VERSION ""

NS_ :

BS_:

BU_: ECU BMU SHDN CHRG TOOL LOGGER C125 DTI_L DTI_R SEVCON_L SEVCON_R SBG

BO_ 256 SBG_ECAN_MSG_STATUS_01: 8 SBG
 SG_ SBG_MSG_01_TIME_STAMP : 0|32@1+ (1,0) [0|4294970000] "µs" C125
 SG_ SBG_MSG_01_GENERAL : 32|16@1+ (1,0) [0|65535] "" C125
 SG_ SBG_MSG_01_CLOCK : 48|16@1+ (1,0) [0|65535] "" C125

BO_ 257 SBG_ECAN_MSG_STATUS_02: 8 SBG
 SG_ SBG_MSG_02_COM : 0|32@1+ (1,0) [0|4294970000] "" Vector__XXX
 SG_ SBG_MSG_02_AIDING : 32|32@1+ (1,0) [0|4294970000] "" Vector__XXX

BO_ 258 SBG_ECAN_MSG_STATUS_03: 6 SBG
 SG_ SBG_MSG_03_SOLUTION : 0|32@1+ (1,0) [0|4294970000] "" Vector__XXX
 SG_ SBG_MSG_03_HEAVE_STATUS : 32|16@1+ (1,0) [0|65535] "" Vector__XXX

BO_ 272 SBG_ECAN_MSG_UTC_0: 8 SBG
 SG_ SBG_UTC_0_TIME_STAMP : 0|32@1+ (1,0) [0|4294970000] "µs" Vector__XXX
 SG_ SBG_UTC_0_GPS_TOW : 32|32@1+ (1,0) [0|4294970000] "ms" Vector__XXX

BO_ 273 SBG_ECAN_MSG_UTC_1: 8 SBG
 SG_ YEAR : 0|8@1+ (1,2000) [2000|2255] "year" Vector__XXX
 SG_ MONTH : 8|8@1+ (1,0) [0|255] "month" Vector__XXX
 SG_ DAY : 16|8@1+ (1,0) [0|255] "d" Vector__XXX
 SG_ HOUR : 24|8@1+ (1,0) [0|255] "h" Vector__XXX
 SG_ MIN : 32|8@1+ (1,0) [0|255] "min" Vector__XXX
 SG_ SEC : 40|8@1+ (1,0) [0|255] "s" Vector__XXX
 SG_ MICRO_SEC : 48|16@1+ (100,0) [0|6553500] "us" Vector__XXX

BO_ 288 SBG_ECAN_MSG_IMU_INFO: 8 SBG
 SG_ SBG_IMU_TIME_STAMP : 0|32@1+ (1,0) [0|4294970000] "µs" Vector__XXX
 SG_ SBG_IMU_STATUS : 32|16@1+ (1,0) [0|65535] "" Vector__XXX
 SG_ SBG_IMU_TEMPERATURE : 48|16@1- (0.01,0) [-327.68|327.67] "°C" Vector__XXX

BO_ 289 SBG_ECAN_MSG_IMU_ACCEL: 6 SBG
 SG_ SBG_IMU_ACCEL_X : 0|16@1- (0.01,0) [-327.68|327.67] "m.s-2" C125
 SG_ SBG_IMU_ACCEL_Y : 16|16@1- (0.01,0) [-327.68|327.67] "m.s-2" C125
 SG_ SBG_IMU_ACCEL_Z : 32|16@1- (0.01,0) [-327.68|327.67] "m.s-2" C125

BO_ 290 SBG_ECAN_MSG_IMU_GYRO: 6 SBG
 SG_ SBG_IMU_GYRO_X : 0|16@1- (0.001,0) [-32.768|32.767] "rad.s-1" C125
 SG_ SBG_IMU_GYRO_Y : 16|16@1- (0.001,0) [-32.768|32.767] "rad.s-1" C125
 SG_ SBG_IMU_GYRO_Z : 32|16@1- (0.001,0) [-32.768|32.767] "rad.s-1" C125

BO_ 291 SBG_ECAN_MSG_IMU_DELTA_VEL: 6 SBG
 SG_ SBG_DELTA_VEL_X : 0|16@1- (0.01,0) [-327.68|327.67] "m.s-2" Vector__XXX
 SG_ SBG_DELTA_VEL_Y : 16|16@1- (0.01,0) [-327.68|327.67] "m.s-2" Vector__XXX
 SG_ SBG_DELTA_VEL_Z : 32|16@1- (0.01,0) [-327.68|327.67] "m.s-2" Vector__XXX

BO_ 292 SBG_ECAN_MSG_IMU_DELTA_ANGLE: 6 SBG
 SG_ SBG_DELTA_ANGLE_X : 0|16@1- (0.001,0) [-32.768|32.767] "rad.s-1" Vector__XXX
 SG_ SBG_DELTA_ANGLE_Y : 16|16@1- (0.001,0) [-32.768|32.767] "rad.s-1" Vector__XXX
 SG_ SBG_DELTA_ANGLE_Z : 32|16@1- (0.001,0) [-32.768|32.767] "rad.s-1" Vector__XXX

BO_ 304 SBG_ECAN_MSG_EKF_INFO: 4 SBG
 SG_ SBG_EFK_TIME_STAMP : 0|32@1+ (1,0) [0|4294970000] "µs" C125

BO_ 305 SBG_ECAN_MSG_EKF_QUAT: 8 SBG
 SG_ Q0 : 0|16@1- (0.0000305185,0) [-1|1] "" Vector__XXX
 SG_ Q1 : 16|16@1- (0.0000305185,0) [-1|1] "" Vector__XXX
 SG_ Q2 : 32|16@1- (0.0000305185,0) [-1|1] "" Vector__XXX
 SG_ Q3 : 48|16@1- (0.0000305185,0) [-1|1] "" Vector__XXX

BO_ 306 SBG_ECAN_MSG_EKF_EULER: 6 SBG
 SG_ SBG_EKF_EULER_ROLL : 0|16@1- (0.0001,0) [-3.2768|3.2767] "rad" C125
 SG_ SBG_EKF_EULER_PITCH : 16|16@1- (0.0001,0) [-3.2768|3.2767] "rad" C125
 SG_ SBG_EKF_EULER_YAW : 32|16@1- (0.0001,0) [-3.2768|3.2767] "rad" C125

BO_ 307 SBG_ECAN_MSG_EKF_ORIENTATION_ACC: 6 SBG
 SG_ SBG_EKF_ORIE_ROLL_ACC : 0|16@1+ (0.0001,0) [0|6.5535] "rad" Vector__XXX
 SG_ SBG_EKF_ORIE_PITCH_ACC : 16|16@1+ (0.0001,0) [0|6.5535] "rad" Vector__XXX
 SG_ SBG_EKF_ORIE_YAW_ACC : 32|16@1+ (0.0001,0) [0|6.5535] "rad" Vector__XXX

BO_ 308 SBG_ECAN_MSG_EKF_POS: 8 SBG
 SG_ SBG_EKF_POS_LATITUDE : 0|32@1- (0.0000001,0) [-214.7483648|214.7483647] "°" C125
 SG_ SBG_EKF_POS_LONGITUDE : 32|32@1- (0.0000001,0) [-214.7483648|214.7483647] "°" C125

BO_ 309 SBG_ECAN_MSG_EKF_ALTITUDE: 6 SBG
 SG_ SBG_EKF_ALTITUDE : 0|32@1- (0.001,0) [-2147480|2147480] "m" C125
 SG_ SBG_EKF_UNDULATION : 32|16@1- (0.005,0) [-163.84|163.835] "m" C125

BO_ 310 SBG_ECAN_MSG_EKF_POS_ACC: 6 SBG
 SG_ SBG_EKF_POS_LATITUDE_ACC : 0|16@1+ (0.01,0) [0|655.35] "m" Vector__XXX
 SG_ SBG_EKF_POS_LONGITUDE_ACC : 16|16@1+ (0.01,0) [0|655.35] "m" Vector__XXX
 SG_ SBG_EKF_POS_ALTITUDE_ACC : 32|16@1+ (0.01,0) [0|655.35] "m" Vector__XXX

BO_ 311 SBG_ECAN_MSG_EKF_VEL_NED: 6 SBG
 SG_ SBG_EKF_NED_VELOCITY_N : 0|16@1- (0.01,0) [-327.68|327.67] "m.s-1" C125
 SG_ SBG_EKF_NED_VELOCITY_E : 16|16@1- (0.01,0) [-327.68|327.67] "m.s-1" C125
 SG_ SBG_EKF_NED_VELOCITY_D : 32|16@1- (0.01,0) [-327.68|327.67] "m.s-1" C125

BO_ 312 SBG_ECAN_MSG_EKF_VEL_NED_ACC: 6 SBG
 SG_ SBG_EKF_NED_VELOCITY_ACC_N : 0|16@1- (0.01,0) [-327.68|327.67] "m.s-1" Vector__XXX
 SG_ SBG_EKF_NED_VELOCITY_ACC_E : 16|16@1- (0.01,0) [-327.68|327.67] "m.s-1" Vector__XXX
 SG_ SBG_EKF_NED_VELOCITY_ACC_D : 32|16@1- (0.01,0) [-327.68|327.67] "m.s-1" Vector__XXX

BO_ 313 SBG_ECAN_MSG_EKF_VEL_BODY: 6 SBG
 SG_ SBG_EKF_BODY_VELOCITY_X : 0|16@1- (0.01,0) [-327.68|327.67] "m.s-1" C125
 SG_ SBG_EKF_BODY_VELOCITY_Y : 16|16@1- (0.01,0) [-327.68|327.67] "m.s-1" C125
 SG_ SBG_EKF_BODY_VELOCITY_Z : 32|16@1- (0.01,0) [-327.68|327.67] "m.s-1" C125

BO_ 320 SBG_ECAN_MSG_SHIP_MOTION_INFO: 8 SBG
 SG_ SBG_SM_TIME_STAMP : 0|32@1+ (1,0) [0|4294970000] "µs" Vector__XXX
 SG_ SBG_SM_PERIOD : 32|16@1+ (0.01,0) [0|655.35] "s" Vector__XXX
 SG_ SBG_SM_STATUS : 48|16@1+ (1,0) [0|65535] "" Vector__XXX

BO_ 321 SBG_ECAN_MSG_SHIP_MOTION_0: 6 SBG
 SG_ SBG_SM_0_SURGE : 0|16@1- (0.001,0) [-32.768|32.767] "m" Vector__XXX
 SG_ SBG_SM_0_SWAY : 16|16@1- (0.001,0) [-32.768|32.767] "m" Vector__XXX
 SG_ SBG_SM_0_HEAVE : 32|16@1- (0.001,0) [-32.768|32.767] "m" Vector__XXX

BO_ 325 SBG_ECAN_MSG_SHIP_MOTION_1: 6 SBG
 SG_ SBG_SM_1_ACCEL_X : 0|16@1- (0.01,0) [-327.68|327.67] "m.s-2" Vector__XXX
 SG_ SBG_SM_1_ACCEL_Y : 16|16@1- (0.01,0) [-327.68|327.67] "m.s-2" Vector__XXX
 SG_ SBG_SM_1_ACCEL_Z : 32|16@1- (0.01,0) [-327.68|327.67] "m.s-2" Vector__XXX

BO_ 329 SBG_ECAN_MSG_SHIP_MOTION_2: 6 SBG
 SG_ SBG_SM_2_VEL_X : 0|16@1- (0.01,0) [-327.68|327.67] "m.s-1" Vector__XXX
 SG_ SBG_SM_2_VEL_Y : 16|16@1- (0.01,0) [-327.68|327.67] "m.s-1" Vector__XXX
 SG_ SBG_SM_2_VEL_Z : 32|16@1- (0.01,0) [-327.68|327.67] "m.s-1" Vector__XXX

BO_ 330 SBG_ECAN_MSG_SHIP_MOTION_HP_INFO: 8 SBG
 SG_ SBG_SM_HP_TIME_STAMP : 0|32@1+ (1,0) [0|4294970000] "µs" Vector__XXX
 SG_ SBG_SM_HP_PERIOD : 32|16@1+ (0.01,0) [0|655.35] "s" Vector__XXX
 SG_ SBG_SM_HP_STATUS : 48|16@1+ (1,0) [0|65535] "" Vector__XXX

BO_ 331 SBG_ECAN_MSG_SHIP_MOTION_HP_0: 6 SBG
 SG_ SBG_SM_HP_0_SURGE : 0|16@1- (0.001,0) [-32.768|32.767] "m" Vector__XXX
 SG_ SBG_SM_HP_0_SWAY : 16|16@1- (0.001,0) [-32.768|32.767] "m" Vector__XXX
 SG_ SBG_SM_HP_0_HEAVE : 32|16@1- (0.001,0) [-32.768|32.767] "m" Vector__XXX

BO_ 332 SBG_ECAN_MSG_SHIP_MOTION_HP_1: 6 SBG
 SG_ SBG_SM_HP_1_ACCEL_X : 0|16@1- (0.01,0) [-327.68|327.67] "m.s-2" Vector__XXX
 SG_ SBG_SM_HP_1_ACCEL_Y : 16|16@1- (0.01,0) [-327.68|327.67] "m.s-2" Vector__XXX
 SG_ SBG_SM_HP_1_ACCEL_Z : 32|16@1- (0.01,0) [-327.68|327.67] "m.s-2" Vector__XXX

BO_ 333 SBG_ECAN_MSG_SHIP_MOTION_HP_2: 6 SBG
 SG_ SBG_SM_HP_2_VEL_X : 0|16@1- (0.01,0) [-327.68|327.67] "m.s-1" Vector__XXX
 SG_ SBG_SM_HP_2_VEL_Y : 16|16@1- (0.01,0) [-327.68|327.67] "m.s-1" Vector__XXX
 SG_ SBG_SM_HP_2_VEL_Z : 32|16@1- (0.01,0) [-327.68|327.67] "m.s-1" Vector__XXX

BO_ 336 SBG_ECAN_MSG_MAG_0: 6 SBG
 SG_ SBG_MAG_0_TIME_STAMP : 0|32@1+ (1,0) [0|4294970000] "µs" Vector__XXX
 SG_ SBG_MAG_0_STATUS : 32|16@1+ (1,0) [0|65535] "" Vector__XXX

BO_ 337 SBG_ECAN_MSG_MAG_1: 6 SBG
 SG_ SBG_MAG_1_MAG_X : 0|16@1- (0.001,0) [-32.768|32.767] "a.u." Vector__XXX
 SG_ SBG_MAG_1_MAG_Y : 16|16@1- (0.001,0) [-32.768|32.767] "a.u." Vector__XXX
 SG_ SBG_MAG_1_MAG_Z : 32|16@1- (0.001,0) [-32.768|32.767] "a.u." Vector__XXX

BO_ 338 SBG_ECAN_MSG_MAG_2: 6 SBG
 SG_ SBG_MAG_2_ACCEL_X : 0|16@1- (0.01,0) [-327.68|327.67] "m.s-2" Vector__XXX
 SG_ SBG_MAG_2_ACCEL_Y : 16|16@1- (0.01,0) [-327.68|327.67] "m.s-2" Vector__XXX
 SG_ SBG_MAG_2_ACCEL_Z : 32|16@1- (0.01,0) [-327.68|327.67] "m.s-2" Vector__XXX

BO_ 352 SBG_ECAN_MSG_ODO_INFO: 6 SBG
 SG_ SBG_ODO_TIME_STAMP : 0|32@1+ (1,0) [0|4294970000] "µs" Vector__XXX
 SG_ SBG_ODO_ODO_STATUS : 32|16@1+ (1,0) [0|65535] "" Vector__XXX

BO_ 353 SBG_ECAN_MSG_ODO_VEL: 2 SBG
 SG_ SBG_ODO_VELOCITY : 0|16@1- (0.01,0) [-327.68|327.67] "m.s-1" Vector__XXX

BO_ 354 SBG_ECAN_MSG_AIR_DATA_INFO: 7 SBG
 SG_ SBG_AIR_TIME_STAMP : 0|32@1+ (1,0) [0|4294970000] "us" Vector__XXX
 SG_ SBG_AIR_AIR_DATA_STATUS : 32|8@1+ (1,0) [0|255] "" Vector__XXX
 SG_ SBG_AIR_AIR_TEMPERATURE : 40|16@1- (0.01,0) [-327.68|327.67] "°C" Vector__XXX

BO_ 355 SBG_ECAN_MSG_AIR_DATA_ALTITUDE: 8 SBG
 SG_ SBG_AIR_PRESSURE_ABS : 0|32@1+ (0.001,0) [0|4294967.2949999999] "Pa" Vector__XXX
 SG_ SBG_AIR_ALTITUDE : 32|32@1- (0.001,0) [-2147483.648|2147483.6469999999] "m" Vector__XXX

BO_ 356 SBG_ECAN_MSG_AIR_DATA_AIRSPEED: 6 SBG
 SG_ SBG_AIR_PRESSURE_DIFF : 0|32@1- (0.001,0) [-2147483.648|2147483.6469999999] "Pa" Vector__XXX
 SG_ SBG_AIR_AIRSPEED : 32|16@1- (0.01,0) [-327.68|327.67] "m.s-1" Vector__XXX

BO_ 358 SBG_ECAN_MSG_DEPTH_INFO: 5 SBG
 SG_ SBG_DEPTH_TIME_STAMP : 0|32@1+ (1,0) [0|4294970000] "us" Vector__XXX
 SG_ SBG_DEPTH_DEPTH_STATUS : 32|8@1+ (1,0) [0|255] "" Vector__XXX

BO_ 359 SBG_ECAN_MSG_DEPTH_ALTITUDE: 8 SBG
 SG_ SBG_DEPTH_PRESSURE_ABS : 0|32@1+ (0.1,0) [0|429497000] "Pa" Vector__XXX
 SG_ SBG_DEPTH_DEPTH : 32|32@1- (0.001,0) [-2147480|2147480] "m" Vector__XXX

BO_ 368 SBG_ECAN_MSG_GPS1_VEL_INFO: 8 SBG
 SG_ SBG_GPS1_VEL_TIME_STAMP : 0|32@1+ (1,0) [0|4294970000] "µs" Vector__XXX
 SG_ SBG_GPS1_VEL_STATUS : 32|32@1+ (1,0) [0|4294970000] "" Vector__XXX

BO_ 369 SBG_ECAN_MSG_GPS1_VEL: 6 SBG
 SG_ SBG_GPS1_VEL_VELOCITY_N : 0|16@1- (0.01,0) [-327.68|327.67] "m.s-1" C125
 SG_ SBG_GPS1_VEL_VELOCITY_E : 16|16@1- (0.01,0) [-327.68|327.67] "m.s-1" C125
 SG_ SBG_GPS1_VEL_VELOCITY_D : 32|16@1- (0.01,0) [-327.68|327.67] "m.s-1" C125

BO_ 370 SBG_ECAN_MSG_GPS1_VEL_ACC: 6 SBG
 SG_ SBG_GPS1_VEL_VELOCITY_ACC_N : 0|16@1- (0.01,0) [-327.68|327.67] "m.s-1" Vector__XXX
 SG_ SBG_GPS1_VEL_VELOCITY_ACC_E : 16|16@1- (0.01,0) [-327.68|327.67] "m.s-1" Vector__XXX
 SG_ SBG_GPS1_VEL_VELOCITY_ACC_D : 32|16@1- (0.01,0) [-327.68|327.67] "m.s-1" Vector__XXX

BO_ 371 SBG_ECAN_MSG_GPS1_VEL_COURSE: 4 SBG
 SG_ SBG_GPS1_VEL_COURSE : 0|16@1+ (0.01,0) [0|655.35] "°" Vector__XXX
 SG_ SBG_GPS1_VEL_COURSE_ACC : 16|16@1+ (0.01,0) [0|655.35] "°" Vector__XXX

BO_ 372 SBG_ECAN_MSG_GPS1_POS_INFO: 8 SBG
 SG_ SBG_GPS1_POS_TIME_STAMP : 0|32@1+ (1,0) [0|4294970000] "µs" Vector__XXX
 SG_ SBG_GPS1_POS_STATUS : 32|32@1+ (1,0) [0|4294970000] "" Vector__XXX

BO_ 373 SBG_ECAN_MSG_GPS1_POS: 8 SBG
 SG_ SBG_GPS1_POS_LATITUDE : 0|32@1- (0.0000001,0) [-214.7483648|214.7483647] "°" C125
 SG_ SBG_GPS1_POS_LONGITUDE : 32|32@1- (0.0000001,0) [-214.7483648|214.7483647] "°" C125

BO_ 374 SBG_ECAN_MSG_GPS1_POS_ALT: 8 SBG
 SG_ SBG_GPS1_POS_ALTITUDE : 0|32@1- (0.001,0) [-2147480|2147480] "m" Vector__XXX
 SG_ SBG_GPS1_POS_UNDULATION : 32|16@1- (0.005,0) [-163.84|163.835] "m" Vector__XXX
 SG_ SBG_GPS1_POS_NUM_SV : 48|8@1+ (1,0) [0|255] "" Vector__XXX
 SG_ SBG_GPS1_POS_DIFF_CORR_AGE : 56|8@1+ (1,0) [0|255] "s" Vector__XXX

BO_ 375 SBG_ECAN_MSG_GPS1_POS_ACC: 8 SBG
 SG_ SBG_GPS1_POS_LATITUDE_ACC : 0|16@1+ (0.01,0) [0|655.35] "m" Vector__XXX
 SG_ SBG_GPS1_POS_LONGITUDE_ACC : 16|16@1+ (0.01,0) [0|655.35] "m" Vector__XXX
 SG_ SBG_GPS1_POS_ALTITUDE_ACC : 32|16@1+ (0.01,0) [0|655.35] "m" Vector__XXX
 SG_ SBG_GPS1_POS_BASE_STATION_ID : 48|16@1+ (1,0) [0|65535] "" Vector__XXX

BO_ 376 SBG_ECAN_MSG_GPS1_HDT_INFO: 6 SBG
 SG_ SBG_GPS1_HDT_TIME_STAMP : 0|32@1+ (1,0) [0|4294970000] "µs" Vector__XXX
 SG_ SBG_GPS1_HDT_STATUS : 32|16@1+ (1,0) [0|65535] "" Vector__XXX

BO_ 377 SBG_ECAN_MSG_GPS1_HDT: 8 SBG
 SG_ SBG_GPS1_HDT_TRUE_HEADING : 0|16@1+ (0.01,0) [0|655.35] "°" Vector__XXX
 SG_ SBG_GPS1_HDT_TRUE_HEADING_ACC : 16|16@1+ (0.01,0) [0|655.35] "°" Vector__XXX
 SG_ SBG_GPS1_HDT_PITCH : 32|16@1- (0.01,0) [-327.68|327.67] "°" Vector__XXX
 SG_ SBG_GPS1_HDT_PITCH_ACC : 48|16@1+ (0.01,0) [0|655.35] "°" Vector__XXX

BO_ 384 SBG_ECAN_MSG_GPS2_VEL_INFO: 8 SBG
 SG_ SBG_GPS2_VEL_TIME_STAMP : 0|32@1+ (1,0) [0|4294970000] "µs" Vector__XXX
 SG_ SBG_GPS2_VEL_STATUS : 32|32@1+ (1,0) [0|4294970000] "" Vector__XXX

BO_ 385 SBG_ECAN_MSG_GPS2_VEL: 6 SBG
 SG_ VELOCITY_N : 0|16@1- (0.01,0) [-327.68|327.67] "m.s-1" Vector__XXX
 SG_ SBG_GPS2_VEL_VELOCITY_E : 16|16@1- (0.01,0) [-327.68|327.67] "m.s-1" Vector__XXX
 SG_ SBG_GPS2_VEL_VELOCITY_D : 32|16@1- (0.01,0) [-327.68|327.67] "m.s-1" Vector__XXX

BO_ 386 SBG_ECAN_MSG_GPS2_VEL_ACC: 6 SBG
 SG_ SBG_GPS2_VEL_VELOCITY_ACC_N : 0|16@1- (0.01,0) [-327.68|327.67] "m.s-1" Vector__XXX
 SG_ SBG_GPS2_VEL_VELOCITY_ACC_E : 16|16@1- (0.01,0) [-327.68|327.67] "m.s-1" Vector__XXX
 SG_ SBG_GPS2_VEL_VELOCITY_ACC_D : 32|16@1- (0.01,0) [-327.68|327.67] "m.s-1" Vector__XXX

BO_ 387 SBG_ECAN_MSG_GPS2_VEL_COURSE: 4 SBG
 SG_ SBG_GPS2_VEL_COURSE : 0|16@1+ (0.01,0) [0|655.35] "°" Vector__XXX
 SG_ SBG_GPS2_VEL_COURSE_ACC : 16|16@1+ (0.01,0) [0|655.35] "°" Vector__XXX

BO_ 388 SBG_ECAN_MSG_GPS2_POS_INFO: 8 SBG
 SG_ SGB_GPS2_POS_TIME_STAMP : 0|32@1+ (1,0) [0|4294970000] "µs" Vector__XXX
 SG_ SBG_GPS2_POS_STATUS : 32|32@1+ (1,0) [0|4294970000] "" Vector__XXX

BO_ 389 SBG_ECAN_MSG_GPS2_POS: 8 SBG
 SG_ SBG_GPS2_POS_LATITUDE : 0|32@1- (0.0000001,0) [-214.7483648|214.7483647] "°" Vector__XXX
 SG_ SBG_GPS2_POS_LONGITUDE : 32|32@1- (0.0000001,0) [-214.7483648|214.7483647] "°" Vector__XXX

BO_ 390 SBG_ECAN_MSG_GPS2_POS_ALT: 8 SBG
 SG_ SBG_GPS2_POS_ALTITUDE : 0|32@1- (0.001,0) [-2147480|2147480] "m" Vector__XXX
 SG_ SBG_GPS2_POS_UNDULATION : 32|16@1- (0.005,0) [-163.84|163.835] "m" Vector__XXX
 SG_ SBG_GPS2_POS_NUM_SV : 48|8@1+ (1,0) [0|255] "" Vector__XXX
 SG_ SBG_GPS2_POS_DIFF_CORR_AGE : 56|8@1+ (1,0) [0|255] "s" Vector__XXX

BO_ 391 SBG_ECAN_MSG_GPS2_POS_ACC: 8 SBG
 SG_ SBG_GPS2_POS_LATITUDE_ACC : 0|16@1+ (0.01,0) [0|655.35] "m" Vector__XXX
 SG_ SBG_GPS2_POS_LONGITUDE_ACC : 16|16@1+ (0.01,0) [0|655.35] "m" Vector__XXX
 SG_ SBG_GPS2_POS_ALTITUDE_ACC : 32|16@1+ (0.01,0) [0|655.35] "m" Vector__XXX
 SG_ SBG_GPS2_POS_BASE_STATION_ID : 48|16@1+ (1,0) [0|65535] "" Vector__XXX

BO_ 392 SBG_ECAN_MSG_GPS2_HDT_INFO: 6 SBG
 SG_ SBG_GPS2_HDT_TIME_STAMP : 0|32@1+ (1,0) [0|4294970000] "µs" Vector__XXX
 SG_ SBG_GPS2_HDT_STATUS : 32|16@1+ (1,0) [0|65535] "" Vector__XXX

BO_ 393 SBG_ECAN_MSG_GPS2_HDT: 8 SBG
 SG_ SBG_GPS2_HDT_TRUE_HEADING : 0|16@1+ (0.01,0) [0|655.35] "°" Vector__XXX
 SG_ SBG_GPS2_HDT_TRUE_HEADING_ACC : 16|16@1+ (0.01,0) [0|655.35] "°" Vector__XXX
 SG_ SBG_GPS2_HDT_PITCH : 32|16@1- (0.01,0) [-327.68|327.67] "°" Vector__XXX
 SG_ SBG_GPS2_HDT_PITCH_ACC : 48|16@1+ (0.01,0) [0|655.35] "°" Vector__XXX

BO_ 512 SBG_ECAN_MSG_EVENT_INFO_A: 8 SBG
 SG_ SBG_A_TIME_STAMP : 0|32@1+ (1,0) [0|4294970000] "µs" Vector__XXX
 SG_ SBG_A_STATUS : 32|16@1+ (1,0) [0|65535] "" Vector__XXX

BO_ 513 SBG_ECAN_MSG_EVENT_TIME_A: 8 SBG
 SG_ SBG_A_TIME_OFFSET_0 : 0|16@1+ (1,0) [0|65535] "µs" Vector__XXX
 SG_ SBG_A_TIME_OFFSET_1 : 16|16@1+ (1,0) [0|65535] "µs" Vector__XXX
 SG_ SBG_A_TIME_OFFSET_2 : 32|16@1+ (1,0) [0|65535] "µs" Vector__XXX
 SG_ SBG_A_TIME_OFFSET_3 : 48|16@1+ (1,0) [0|65535] "µs" Vector__XXX

BO_ 514 SBG_ECAN_MSG_EVENT_INFO_B: 8 SBG
 SG_ SBG_B_TIME_STAMP : 0|32@1+ (1,0) [0|4294970000] "µs" Vector__XXX
 SG_ SBG_B_STATUS : 32|16@1+ (1,0) [0|65535] "" Vector__XXX

BO_ 515 SBG_ECAN_MSG_EVENT_TIME_B: 8 SBG
 SG_ SBG_B_TIME_OFFSET_0 : 0|16@1+ (1,0) [0|65535] "µs" Vector__XXX
 SG_ SBG_B_TIME_OFFSET_1 : 16|16@1+ (1,0) [0|65535] "µs" Vector__XXX
 SG_ SBG_B_TIME_OFFSET_2 : 32|16@1+ (1,0) [0|65535] "µs" Vector__XXX
 SG_ SBG_B_TIME_OFFSET_3 : 48|16@1+ (1,0) [0|65535] "µs" Vector__XXX

BO_ 516 SBG_ECAN_MSG_EVENT_INFO_C: 8 SBG
 SG_ SBG_C_TIME_STAMP : 0|32@1+ (1,0) [0|4294970000] "µs" Vector__XXX
 SG_ SBG_C_STATUS : 32|16@1+ (1,0) [0|65535] "" Vector__XXX

BO_ 517 SBG_ECAN_MSG_EVENT_TIME_C: 8 SBG
 SG_ SBG_C_TIME_OFFSET_0 : 0|16@1+ (1,0) [0|65535] "µs" Vector__XXX
 SG_ SBG_C_TIME_OFFSET_1 : 16|16@1+ (1,0) [0|65535] "µs" Vector__XXX
 SG_ SBG_C_TIME_OFFSET_2 : 32|16@1+ (1,0) [0|65535] "µs" Vector__XXX
 SG_ SBG_C_TIME_OFFSET_3 : 48|16@1+ (1,0) [0|65535] "µs" Vector__XXX

BO_ 518 SBG_ECAN_MSG_EVENT_INFO_D: 8 SBG
 SG_ SBG_D_TIME_STAMP : 0|32@1+ (1,0) [0|4294970000] "µs" Vector__XXX
 SG_ SBG_D_STATUS : 32|16@1+ (1,0) [0|65535] "" Vector__XXX

BO_ 519 SBG_ECAN_MSG_EVENT_TIME_D: 8 SBG
 SG_ SBG_D_TIME_OFFSET_0 : 0|16@1+ (1,0) [0|65535] "µs" Vector__XXX
 SG_ SBG_D_TIME_OFFSET_1 : 16|16@1+ (1,0) [0|65535] "µs" Vector__XXX
 SG_ SBG_D_TIME_OFFSET_2 : 32|16@1+ (1,0) [0|65535] "µs" Vector__XXX
 SG_ SBG_D_TIME_OFFSET_3 : 48|16@1+ (1,0) [0|65535] "µs" Vector__XXX

BO_ 520 SBG_ECAN_MSG_EVENT_INFO_E: 8 SBG
 SG_ SBG_E_TIME_STAMP : 0|32@1+ (1,0) [0|4294970000] "µs" Vector__XXX
 SG_ SBG_E_STATUS : 32|16@1+ (1,0) [0|65535] "" Vector__XXX

BO_ 521 SBG_ECAN_MSG_EVENT_TIME_E: 8 SBG
 SG_ SBG_E_TIME_OFFSET_0 : 0|16@1+ (1,0) [0|65535] "µs" Vector__XXX
 SG_ SBG_E_TIME_OFFSET_1 : 16|16@1+ (1,0) [0|65535] "µs" Vector__XXX
 SG_ SBG_E_TIME_OFFSET_2 : 32|16@1+ (1,0) [0|65535] "µs" Vector__XXX
 SG_ SBG_E_TIME_OFFSET_3 : 48|16@1+ (1,0) [0|65535] "µs" Vector__XXX

BO_ 544 SBG_ECAN_MSG_AUTO_SLIP_CURV: 7 SBG
 SG_ SBG_ASLIP_ANGLE_TRACK : 0|16@1- (0.0001,0) [-3.2768|3.2767] "rad" C125
 SG_ SBG_ASLIP_ANGLE_SLIP : 16|16@1- (0.0001,0) [-3.2768|3.2767] "rad" C125
 SG_ SBG_ASLIP_CURVATURE_RADIUS : 32|16@1+ (0.01,0) [0|655.35] "m" C125
 SG_ SBG_ASLIP_AUTO_STATUS : 48|8@1+ (1,0) [0|255] "" C125

BO_ 2147484988 DTI_L_SET_REL_CURRENT: 8 ECU
 SG_ DTI_L_CmdRelCurrent : 7|16@0- (0.1,0) [-100|100] "%" DTI_L,C125

BO_ 2147484989 DTI_R_SET_REL_CURRENT: 8 ECU
 SG_ DTI_R_CmdRelCurrent : 7|16@0- (0.1,0) [-100|100] "%" DTI_R,C125

BO_ 2147485244 DTI_L_SET_REL_BRAKE: 8 ECU
 SG_ DTI_L_CmdRelBrake : 7|16@0- (0.1,0) [0|100] "%" DTI_L

BO_ 2147485245 DTI_R_SET_REL_BRAKE: 8 ECU
 SG_ DTI_R_CmdRelBrake : 7|16@0- (0.1,0) [0|100] "%" DTI_R

BO_ 2147485756 DTI_L_SET_MAX_AC_CURRENT: 8 ECU
 SG_ DTI_L_CmdMaxAc : 7|16@0- (0.1,0) [-3276.8|3276.7] "A" DTI_L

BO_ 2147485757 DTI_R_SET_MAX_AC_CURRENT: 8 ECU
 SG_ DTI_R_CmdMaxAc : 7|16@0- (0.1,0) [-3276.8|3276.7] "A" DTI_R

BO_ 2147486012 DTI_L_SET_MAX_AC_BRAKE: 8 ECU
 SG_ DTI_L_CmdMaxAcBrake : 7|16@0- (0.1,0) [-3276.8|3276.7] "A" DTI_L

BO_ 2147486013 DTI_R_SET_MAX_AC_BRAKE: 8 ECU
 SG_ DTI_R_CmdMaxAcBrake : 7|16@0- (0.1,0) [-3276.8|3276.7] "A" DTI_R

BO_ 2147486268 DTI_L_SET_MAX_DC_CURRENT: 8 ECU
 SG_ DTI_L_CmdMaxDc : 7|16@0- (0.1,0) [-3276.8|3276.7] "A" DTI_L

BO_ 2147486269 DTI_R_SET_MAX_DC_CURRENT: 8 ECU
 SG_ DTI_R_CmdMaxDc : 7|16@0- (0.1,0) [-3276.8|3276.7] "A" DTI_R

BO_ 2147486524 DTI_L_SET_MAX_DC_BRAKE: 8 ECU
 SG_ DTI_L_CmdMaxDcBrake : 7|16@0- (0.1,0) [-3276.8|3276.7] "A" DTI_L

BO_ 2147486525 DTI_R_SET_MAX_DC_BRAKE: 8 ECU
 SG_ DTI_R_CmdMaxDcBrake : 7|16@0- (0.1,0) [-3276.8|3276.7] "A" DTI_R

BO_ 2147486780 DTI_L_DRIVE_ENABLE: 8 ECU
 SG_ DTI_L_CmdDriveEnable : 7|8@0+ (1,0) [0|255] "" DTI_L,C125

BO_ 2147486781 DTI_R_DRIVE_ENABLE: 8 ECU
 SG_ DTI_R_CmdDriveEnable : 7|8@0+ (1,0) [0|255] "" DTI_R,C125

BO_ 2147491644 DTI_L_CONTROL_MODE: 8 DTI_L
 SG_ DTI_L_ControlMode : 7|8@0+ (1,0) [0|255] "" ECU
 SG_ DTI_L_TargetIq : 15|16@0- (0.1,0) [-3276.8|3276.7] "A" ECU
 SG_ DTI_L_MotorPosition : 31|16@0+ (0.1,0) [0|6553.5] "deg" ECU
 SG_ DTI_L_MotorStill : 47|8@0+ (1,0) [0|255] "" ECU

BO_ 2147491645 DTI_R_CONTROL_MODE: 8 DTI_R
 SG_ DTI_R_ControlMode : 7|8@0+ (1,0) [0|255] "" ECU
 SG_ DTI_R_TargetIq : 15|16@0- (0.1,0) [-3276.8|3276.7] "A" ECU
 SG_ DTI_R_MotorPosition : 31|16@0+ (0.1,0) [0|6553.5] "deg" ECU
 SG_ DTI_R_MotorStill : 47|8@0+ (1,0) [0|255] "" ECU

BO_ 2147491900 DTI_L_ERPM_DUTY_VIN: 8 DTI_L
 SG_ DTI_L_Erpm : 7|32@0- (1,0) [-2147483648|2147483647] "rpm" ECU,C125
 SG_ DTI_L_Duty : 39|16@0- (0.1,0) [-3276.8|3276.7] "%" ECU,C125
 SG_ DTI_L_InputVoltage : 55|16@0- (1,0) [-32768|32767] "V" ECU,C125

BO_ 2147491901 DTI_R_ERPM_DUTY_VIN: 8 DTI_R
 SG_ DTI_R_Erpm : 7|32@0- (1,0) [-2147483648|2147483647] "rpm" ECU,C125
 SG_ DTI_R_Duty : 39|16@0- (0.1,0) [-3276.8|3276.7] "%" ECU,C125
 SG_ DTI_R_InputVoltage : 55|16@0- (1,0) [-32768|32767] "V" ECU,C125

BO_ 2147492156 DTI_L_CURRENTS: 8 DTI_L
 SG_ DTI_L_AcCurrent : 7|16@0- (0.1,0) [-3276.8|3276.7] "A" ECU,C125
 SG_ DTI_L_DcCurrent : 23|16@0- (0.1,0) [-3276.8|3276.7] "A" ECU,C125

BO_ 2147492157 DTI_R_CURRENTS: 8 DTI_R
 SG_ DTI_R_AcCurrent : 7|16@0- (0.1,0) [-3276.8|3276.7] "A" ECU,C125
 SG_ DTI_R_DcCurrent : 23|16@0- (0.1,0) [-3276.8|3276.7] "A" ECU,C125

BO_ 2147492412 DTI_L_TEMPS_FAULT: 8 DTI_L
 SG_ DTI_L_CtrlTemp : 7|16@0- (0.1,0) [-3276.8|3276.7] "degC" ECU,C125
 SG_ DTI_L_MotorTemp : 23|16@0- (0.1,0) [-3276.8|3276.7] "degC" ECU,C125
 SG_ DTI_L_FaultCode : 39|8@0+ (1,0) [0|255] "" ECU,C125

BO_ 2147492413 DTI_R_TEMPS_FAULT: 8 DTI_R
 SG_ DTI_R_CtrlTemp : 7|16@0- (0.1,0) [-3276.8|3276.7] "degC" ECU,C125
 SG_ DTI_R_MotorTemp : 23|16@0- (0.1,0) [-3276.8|3276.7] "degC" ECU,C125
 SG_ DTI_R_FaultCode : 39|8@0+ (1,0) [0|255] "" ECU,C125

BO_ 2147492668 DTI_L_ID_IQ: 8 DTI_L
 SG_ DTI_L_Id : 7|32@0- (0.01,0) [-21474836.4800000004|21474836.4699999988] "A" ECU
 SG_ DTI_L_Iq : 39|32@0- (0.01,0) [-21474836.4800000004|21474836.4699999988] "A" ECU

BO_ 2147492669 DTI_R_ID_IQ: 8 DTI_R
 SG_ DTI_R_Id : 7|32@0- (0.01,0) [-21474836.4800000004|21474836.4699999988] "A" ECU
 SG_ DTI_R_Iq : 39|32@0- (0.01,0) [-21474836.4800000004|21474836.4699999988] "A" ECU

BO_ 2147492924 DTI_L_IO_STATUS: 8 DTI_L
 SG_ DTI_L_Throttle : 7|8@0- (1,0) [-128|127] "%" ECU
 SG_ DTI_L_Brake : 15|8@0- (1,0) [-128|127] "%" ECU
 SG_ DTI_L_DigOut4 : 23|1@0+ (1,0) [0|1] "" ECU
 SG_ DTI_L_DigOut3 : 22|1@0+ (1,0) [0|1] "" ECU
 SG_ DTI_L_DigOut2 : 21|1@0+ (1,0) [0|1] "" ECU
 SG_ DTI_L_DigOut1 : 20|1@0+ (1,0) [0|1] "" ECU
 SG_ DTI_L_DigIn4 : 19|1@0+ (1,0) [0|1] "" ECU
 SG_ DTI_L_DigIn3 : 18|1@0+ (1,0) [0|1] "" ECU
 SG_ DTI_L_DigIn2 : 17|1@0+ (1,0) [0|1] "" ECU
 SG_ DTI_L_DigIn1 : 16|1@0+ (1,0) [0|1] "" ECU
 SG_ DTI_L_DriveEnabled : 31|8@0+ (1,0) [0|255] "" ECU,C125
 SG_ DTI_L_LimMotorTemp : 39|1@0+ (1,0) [0|1] "" ECU,C125
 SG_ DTI_L_LimMotorAccelTemp : 38|1@0+ (1,0) [0|1] "" ECU,C125
 SG_ DTI_L_LimInputVoltage : 37|1@0+ (1,0) [0|1] "" ECU,C125
 SG_ DTI_L_LimIgbtTemp : 36|1@0+ (1,0) [0|1] "" ECU,C125
 SG_ DTI_L_LimIgbtAccelTemp : 35|1@0+ (1,0) [0|1] "" ECU,C125
 SG_ DTI_L_LimDriveEnable : 34|1@0+ (1,0) [0|1] "" ECU,C125
 SG_ DTI_L_LimDcCurrent : 33|1@0+ (1,0) [0|1] "" ECU,C125
 SG_ DTI_L_LimCapTemp : 32|1@0+ (1,0) [0|1] "" ECU,C125
 SG_ DTI_L_LimPower : 42|1@0+ (1,0) [0|1] "" ECU,C125
 SG_ DTI_L_LimRpmMax : 41|1@0+ (1,0) [0|1] "" ECU,C125
 SG_ DTI_L_LimRpmMin : 40|1@0+ (1,0) [0|1] "" ECU,C125
 SG_ DTI_L_CanMapVersion : 63|8@0+ (0.1,0) [0|25.5] "" ECU

BO_ 2147492925 DTI_R_IO_STATUS: 8 DTI_R
 SG_ DTI_R_Throttle : 7|8@0- (1,0) [-128|127] "%" ECU
 SG_ DTI_R_Brake : 15|8@0- (1,0) [-128|127] "%" ECU
 SG_ DTI_R_DigOut4 : 23|1@0+ (1,0) [0|1] "" ECU
 SG_ DTI_R_DigOut3 : 22|1@0+ (1,0) [0|1] "" ECU
 SG_ DTI_R_DigOut2 : 21|1@0+ (1,0) [0|1] "" ECU
 SG_ DTI_R_DigOut1 : 20|1@0+ (1,0) [0|1] "" ECU
 SG_ DTI_R_DigIn4 : 19|1@0+ (1,0) [0|1] "" ECU
 SG_ DTI_R_DigIn3 : 18|1@0+ (1,0) [0|1] "" ECU
 SG_ DTI_R_DigIn2 : 17|1@0+ (1,0) [0|1] "" ECU
 SG_ DTI_R_DigIn1 : 16|1@0+ (1,0) [0|1] "" ECU
 SG_ DTI_R_DriveEnabled : 31|8@0+ (1,0) [0|255] "" ECU,C125
 SG_ DTI_R_LimMotorTemp : 39|1@0+ (1,0) [0|1] "" ECU,C125
 SG_ DTI_R_LimMotorAccelTemp : 38|1@0+ (1,0) [0|1] "" ECU,C125
 SG_ DTI_R_LimInputVoltage : 37|1@0+ (1,0) [0|1] "" ECU,C125
 SG_ DTI_R_LimIgbtTemp : 36|1@0+ (1,0) [0|1] "" ECU,C125
 SG_ DTI_R_LimIgbtAccelTemp : 35|1@0+ (1,0) [0|1] "" ECU,C125
 SG_ DTI_R_LimDriveEnable : 34|1@0+ (1,0) [0|1] "" ECU,C125
 SG_ DTI_R_LimDcCurrent : 33|1@0+ (1,0) [0|1] "" ECU,C125
 SG_ DTI_R_LimCapTemp : 32|1@0+ (1,0) [0|1] "" ECU,C125
 SG_ DTI_R_LimPower : 42|1@0+ (1,0) [0|1] "" ECU,C125
 SG_ DTI_R_LimRpmMax : 41|1@0+ (1,0) [0|1] "" ECU,C125
 SG_ DTI_R_LimRpmMin : 40|1@0+ (1,0) [0|1] "" ECU,C125
 SG_ DTI_R_CanMapVersion : 63|8@0+ (0.1,0) [0|25.5] "" ECU

BO_ 2147493180 DTI_L_AC_LIMITS: 8 DTI_L
 SG_ DTI_L_MaxAc : 7|16@0- (0.1,0) [-3276.8|3276.7] "A" ECU
 SG_ DTI_L_AvMaxAc : 23|16@0- (0.1,0) [-3276.8|3276.7] "A" ECU
 SG_ DTI_L_MinAc : 39|16@0- (0.1,0) [-3276.8|3276.7] "A" ECU
 SG_ DTI_L_AvMinAc : 55|16@0- (0.1,0) [-3276.8|3276.7] "A" ECU

BO_ 2147493181 DTI_R_AC_LIMITS: 8 DTI_R
 SG_ DTI_R_MaxAc : 7|16@0- (0.1,0) [-3276.8|3276.7] "A" ECU
 SG_ DTI_R_AvMaxAc : 23|16@0- (0.1,0) [-3276.8|3276.7] "A" ECU
 SG_ DTI_R_MinAc : 39|16@0- (0.1,0) [-3276.8|3276.7] "A" ECU
 SG_ DTI_R_AvMinAc : 55|16@0- (0.1,0) [-3276.8|3276.7] "A" ECU

BO_ 2147493436 DTI_L_DC_LIMITS: 8 DTI_L
 SG_ DTI_L_MaxDc : 7|16@0- (0.1,0) [-3276.8|3276.7] "A" ECU
 SG_ DTI_L_AvMaxDc : 23|16@0- (0.1,0) [-3276.8|3276.7] "A" ECU
 SG_ DTI_L_MinDc : 39|16@0- (0.1,0) [-3276.8|3276.7] "A" ECU
 SG_ DTI_L_AvMinDc : 55|16@0- (0.1,0) [-3276.8|3276.7] "A" ECU

BO_ 2147493437 DTI_R_DC_LIMITS: 8 DTI_R
 SG_ DTI_R_MaxDc : 7|16@0- (0.1,0) [-3276.8|3276.7] "A" ECU
 SG_ DTI_R_AvMaxDc : 23|16@0- (0.1,0) [-3276.8|3276.7] "A" ECU
 SG_ DTI_R_MinDc : 39|16@0- (0.1,0) [-3276.8|3276.7] "A" ECU
 SG_ DTI_R_AvMinDc : 55|16@0- (0.1,0) [-3276.8|3276.7] "A" ECU

BO_ 2164260864 SHDN_SHUTDOWN_TRIGGERED: 3 SHDN
 SG_ SHDN_TrigSegment : 0|8@1+ (1,0) [0|255] "" ECU,BMU
 SG_ SHDN_TrigOpenMask : 8|16@1+ (1,0) [0|65535] "" ECU,BMU

BO_ 2165338473 Sevcon_1_HC1: 8 ECU
 SG_ Sevcon_1_TorqueDemand : 0|16@1- (0.0625,0) [-2048|2047.9375] "Nm" SEVCON_L
 SG_ Sevcon_1_ControlWord : 16|16@1+ (1,0) [0|65535] "" SEVCON_L
 SG_ Sevcon_1_TorqueLimit : 32|16@1- (0.0625,0) [-2048|2047.9375] "Nm" SEVCON_L

BO_ 2165338729 Sevcon_2_HC1: 8 ECU
 SG_ Sevcon_2_TorqueDemand : 0|16@1- (0.0625,0) [-2048|2047.9375] "Nm" SEVCON_R
 SG_ Sevcon_2_ControlWord : 16|16@1+ (1,0) [0|65535] "" SEVCON_R
 SG_ Sevcon_2_TorqueLimit : 32|16@1- (0.0625,0) [-2048|2047.9375] "Nm" SEVCON_R

BO_ 2165404009 Sevcon_1_HC2: 8 ECU
 SG_ Sevcon_1_RegenTorqueLimit : 0|16@1- (0.0625,0) [-2048|2047.9375] "Nm" SEVCON_L
 SG_ Sevcon_1_FwdSpeedLimit : 16|16@1+ (1,0) [0|65535] "RPM" SEVCON_L
 SG_ Sevcon_1_RevSpeedLimit : 32|16@1- (1,0) [-32768|32767] "RPM" SEVCON_L

BO_ 2165404265 Sevcon_2_HC2: 8 ECU
 SG_ Sevcon_2_RegenTorqueLimit : 0|16@1- (0.0625,0) [-2048|2047.9375] "Nm" SEVCON_R
 SG_ Sevcon_2_FwdSpeedLimit : 16|16@1+ (1,0) [0|65535] "RPM" SEVCON_R
 SG_ Sevcon_2_RevSpeedLimit : 32|16@1- (1,0) [-32768|32767] "RPM" SEVCON_R

BO_ 2165469545 Sevcon_1_HC3: 8 ECU
 SG_ Sevcon_1_DischargeLimit : 0|16@1- (1,0) [-32768|32767] "A" SEVCON_L
 SG_ Sevcon_1_ChargeLimit : 16|16@1- (1,0) [-32768|32767] "A" SEVCON_L
 SG_ Sevcon_1_TargetCapVoltage : 32|16@1- (1,0) [-32768|32767] "V" SEVCON_L

BO_ 2165469801 Sevcon_2_HC3: 8 ECU
 SG_ Sevcon_2_DischargeLimit : 0|16@1- (1,0) [-32768|32767] "A" SEVCON_R
 SG_ Sevcon_2_ChargeLimit : 16|16@1- (1,0) [-32768|32767] "A" SEVCON_R
 SG_ Sevcon_2_TargetCapVoltage : 32|16@1- (1,0) [-32768|32767] "V" SEVCON_R

BO_ 2281963520 BMU_HEARTBEAT: 8 BMU
 SG_ BMU_State : 0|8@1+ (1,0) [0|255] "" ECU,CHRG,C125
 SG_ BMU_F_HbCmu : 8|1@1+ (1,0) [0|1] "" ECU,CHRG,C125
 SG_ BMU_F_HbSendyne1 : 9|1@1+ (1,0) [0|1] "" ECU,CHRG,C125
 SG_ BMU_F_HbSendyne2 : 10|1@1+ (1,0) [0|1] "" ECU,CHRG,C125
 SG_ BMU_F_HbEcu : 11|1@1+ (1,0) [0|1] "" ECU,CHRG,C125
 SG_ BMU_F_HbChrgCtrl : 12|1@1+ (1,0) [0|1] "" ECU,CHRG,C125
 SG_ BMU_F_Watchdog : 13|1@1+ (1,0) [0|1] "" ECU,CHRG,C125
 SG_ BMU_F_Can1 : 14|1@1+ (1,0) [0|1] "" ECU,CHRG,C125
 SG_ BMU_F_Can2 : 15|1@1+ (1,0) [0|1] "" ECU,CHRG,C125
 SG_ BMU_F_ContactorPos : 16|1@1+ (1,0) [0|1] "" ECU,CHRG,C125
 SG_ BMU_F_ContactorNeg : 17|1@1+ (1,0) [0|1] "" ECU,CHRG,C125
 SG_ BMU_F_ContactorPchrg : 18|1@1+ (1,0) [0|1] "" ECU,CHRG,C125
 SG_ BMU_F_PrechargeTimeout : 19|1@1+ (1,0) [0|1] "" ECU,CHRG,C125
 SG_ BMU_F_CmuOverVolt : 20|1@1+ (1,0) [0|1] "" ECU,CHRG,C125
 SG_ BMU_F_CmuUnderVolt : 21|1@1+ (1,0) [0|1] "" ECU,CHRG,C125
 SG_ BMU_F_CmuBadTemp : 22|1@1+ (1,0) [0|1] "" ECU,CHRG,C125
 SG_ BMU_F_CmuOpenVolt : 23|1@1+ (1,0) [0|1] "" ECU,CHRG,C125
 SG_ BMU_F_CmuOpenTemp : 24|1@1+ (1,0) [0|1] "" ECU,CHRG,C125
 SG_ BMU_F_CmuMissingVolt : 25|1@1+ (1,0) [0|1] "" ECU,CHRG,C125
 SG_ BMU_F_CmuMissingTemp : 26|1@1+ (1,0) [0|1] "" ECU,CHRG,C125
 SG_ BMU_F_ShdnBmu : 27|1@1+ (1,0) [0|1] "" ECU,CHRG,C125
 SG_ BMU_F_ShdnPdoc : 28|1@1+ (1,0) [0|1] "" ECU,CHRG,C125
 SG_ BMU_F_ShdnImd : 29|1@1+ (1,0) [0|1] "" ECU,CHRG,C125
 SG_ BMU_F_ShdnInterlock : 30|1@1+ (1,0) [0|1] "" ECU,CHRG,C125
 SG_ BMU_F_Balancing : 31|1@1+ (1,0) [0|1] "" ECU,CHRG,C125
 SG_ BMU_F_DieTemps : 32|1@1+ (1,0) [0|1] "" ECU,CHRG,C125
 SG_ BMU_F_HvKey : 33|1@1+ (1,0) [0|1] "" ECU,CHRG,C125
 SG_ BMU_F_ChrgDetect : 34|1@1+ (1,0) [0|1] "" ECU,CHRG,C125
 SG_ BMU_F_ChrgCtrl : 35|1@1+ (1,0) [0|1] "" ECU,CHRG,C125
 SG_ BMU_PackState : 40|8@1+ (1,0) [0|255] "" ECU,CHRG
 SG_ BMU_SOC : 48|8@1+ (1,0) [0|255] "%" ECU,CHRG

BO_ 2284093440 BMU_TransmitVoltage_N_0_P_0: 8 BMU
 SG_ BMU_M00_V00 : 0|16@1+ (1,0) [0|65535] "mV" LOGGER
 SG_ BMU_M00_V01 : 16|16@1+ (1,0) [0|65535] "mV" LOGGER
 SG_ BMU_M00_V02 : 32|16@1+ (1,0) [0|65535] "mV" LOGGER
 SG_ BMU_M00_VAge0 : 48|16@1+ (1,0) [0|65535] "ms" LOGGER

BO_ 2284093441 BMU_TransmitVoltage_N_0_P_1: 8 BMU
 SG_ BMU_M00_V03 : 0|16@1+ (1,0) [0|65535] "mV" LOGGER
 SG_ BMU_M00_V04 : 16|16@1+ (1,0) [0|65535] "mV" LOGGER
 SG_ BMU_M00_V05 : 32|16@1+ (1,0) [0|65535] "mV" LOGGER
 SG_ BMU_M00_VAge1 : 48|16@1+ (1,0) [0|65535] "ms" LOGGER

BO_ 2284093442 BMU_TransmitVoltage_N_0_P_2: 8 BMU
 SG_ BMU_M00_V06 : 0|16@1+ (1,0) [0|65535] "mV" LOGGER
 SG_ BMU_M00_V07 : 16|16@1+ (1,0) [0|65535] "mV" LOGGER
 SG_ BMU_M00_V08 : 32|16@1+ (1,0) [0|65535] "mV" LOGGER
 SG_ BMU_M00_VAge2 : 48|16@1+ (1,0) [0|65535] "ms" LOGGER

BO_ 2284093443 BMU_TransmitVoltage_N_0_P_3: 8 BMU
 SG_ BMU_M00_V09 : 0|16@1+ (1,0) [0|65535] "mV" LOGGER
 SG_ BMU_M00_V10 : 16|16@1+ (1,0) [0|65535] "mV" LOGGER
 SG_ BMU_M00_V11 : 32|16@1+ (1,0) [0|65535] "mV" LOGGER
 SG_ BMU_M00_VAge3 : 48|16@1+ (1,0) [0|65535] "ms" LOGGER

BO_ 2284093456 BMU_TransmitVoltage_N_1_P_0: 8 BMU
 SG_ BMU_M01_V00 : 0|16@1+ (1,0) [0|65535] "mV" LOGGER
 SG_ BMU_M01_V01 : 16|16@1+ (1,0) [0|65535] "mV" LOGGER
 SG_ BMU_M01_V02 : 32|16@1+ (1,0) [0|65535] "mV" LOGGER
 SG_ BMU_M01_VAge0 : 48|16@1+ (1,0) [0|65535] "ms" LOGGER

BO_ 2284093457 BMU_TransmitVoltage_N_1_P_1: 8 BMU
 SG_ BMU_M01_V03 : 0|16@1+ (1,0) [0|65535] "mV" LOGGER
 SG_ BMU_M01_V04 : 16|16@1+ (1,0) [0|65535] "mV" LOGGER
 SG_ BMU_M01_V05 : 32|16@1+ (1,0) [0|65535] "mV" LOGGER
 SG_ BMU_M01_VAge1 : 48|16@1+ (1,0) [0|65535] "ms" LOGGER

BO_ 2284093458 BMU_TransmitVoltage_N_1_P_2: 8 BMU
 SG_ BMU_M01_V06 : 0|16@1+ (1,0) [0|65535] "mV" LOGGER
 SG_ BMU_M01_V07 : 16|16@1+ (1,0) [0|65535] "mV" LOGGER
 SG_ BMU_M01_V08 : 32|16@1+ (1,0) [0|65535] "mV" LOGGER
 SG_ BMU_M01_VAge2 : 48|16@1+ (1,0) [0|65535] "ms" LOGGER

BO_ 2284093459 BMU_TransmitVoltage_N_1_P_3: 8 BMU
 SG_ BMU_M01_V09 : 0|16@1+ (1,0) [0|65535] "mV" LOGGER
 SG_ BMU_M01_V10 : 16|16@1+ (1,0) [0|65535] "mV" LOGGER
 SG_ BMU_M01_V11 : 32|16@1+ (1,0) [0|65535] "mV" LOGGER
 SG_ BMU_M01_VAge3 : 48|16@1+ (1,0) [0|65535] "ms" LOGGER

BO_ 2284093472 BMU_TransmitVoltage_N_2_P_0: 8 BMU
 SG_ BMU_M02_V00 : 0|16@1+ (1,0) [0|65535] "mV" LOGGER
 SG_ BMU_M02_V01 : 16|16@1+ (1,0) [0|65535] "mV" LOGGER
 SG_ BMU_M02_V02 : 32|16@1+ (1,0) [0|65535] "mV" LOGGER
 SG_ BMU_M02_VAge0 : 48|16@1+ (1,0) [0|65535] "ms" LOGGER

BO_ 2284093473 BMU_TransmitVoltage_N_2_P_1: 8 BMU
 SG_ BMU_M02_V03 : 0|16@1+ (1,0) [0|65535] "mV" LOGGER
 SG_ BMU_M02_V04 : 16|16@1+ (1,0) [0|65535] "mV" LOGGER
 SG_ BMU_M02_V05 : 32|16@1+ (1,0) [0|65535] "mV" LOGGER
 SG_ BMU_M02_VAge1 : 48|16@1+ (1,0) [0|65535] "ms" LOGGER

BO_ 2284093474 BMU_TransmitVoltage_N_2_P_2: 8 BMU
 SG_ BMU_M02_V06 : 0|16@1+ (1,0) [0|65535] "mV" LOGGER
 SG_ BMU_M02_V07 : 16|16@1+ (1,0) [0|65535] "mV" LOGGER
 SG_ BMU_M02_V08 : 32|16@1+ (1,0) [0|65535] "mV" LOGGER
 SG_ BMU_M02_VAge2 : 48|16@1+ (1,0) [0|65535] "ms" LOGGER

BO_ 2284093475 BMU_TransmitVoltage_N_2_P_3: 8 BMU
 SG_ BMU_M02_V09 : 0|16@1+ (1,0) [0|65535] "mV" LOGGER
 SG_ BMU_M02_V10 : 16|16@1+ (1,0) [0|65535] "mV" LOGGER
 SG_ BMU_M02_V11 : 32|16@1+ (1,0) [0|65535] "mV" LOGGER
 SG_ BMU_M02_VAge3 : 48|16@1+ (1,0) [0|65535] "ms" LOGGER

BO_ 2284093488 BMU_TransmitVoltage_N_3_P_0: 8 BMU
 SG_ BMU_M03_V00 : 0|16@1+ (1,0) [0|65535] "mV" LOGGER
 SG_ BMU_M03_V01 : 16|16@1+ (1,0) [0|65535] "mV" LOGGER
 SG_ BMU_M03_V02 : 32|16@1+ (1,0) [0|65535] "mV" LOGGER
 SG_ BMU_M03_VAge0 : 48|16@1+ (1,0) [0|65535] "ms" LOGGER

BO_ 2284093489 BMU_TransmitVoltage_N_3_P_1: 8 BMU
 SG_ BMU_M03_V03 : 0|16@1+ (1,0) [0|65535] "mV" LOGGER
 SG_ BMU_M03_V04 : 16|16@1+ (1,0) [0|65535] "mV" LOGGER
 SG_ BMU_M03_V05 : 32|16@1+ (1,0) [0|65535] "mV" LOGGER
 SG_ BMU_M03_VAge1 : 48|16@1+ (1,0) [0|65535] "ms" LOGGER

BO_ 2284093490 BMU_TransmitVoltage_N_3_P_2: 8 BMU
 SG_ BMU_M03_V06 : 0|16@1+ (1,0) [0|65535] "mV" LOGGER
 SG_ BMU_M03_V07 : 16|16@1+ (1,0) [0|65535] "mV" LOGGER
 SG_ BMU_M03_V08 : 32|16@1+ (1,0) [0|65535] "mV" LOGGER
 SG_ BMU_M03_VAge2 : 48|16@1+ (1,0) [0|65535] "ms" LOGGER

BO_ 2284093491 BMU_TransmitVoltage_N_3_P_3: 8 BMU
 SG_ BMU_M03_V09 : 0|16@1+ (1,0) [0|65535] "mV" LOGGER
 SG_ BMU_M03_V10 : 16|16@1+ (1,0) [0|65535] "mV" LOGGER
 SG_ BMU_M03_V11 : 32|16@1+ (1,0) [0|65535] "mV" LOGGER
 SG_ BMU_M03_VAge3 : 48|16@1+ (1,0) [0|65535] "ms" LOGGER

BO_ 2284093504 BMU_TransmitVoltage_N_4_P_0: 8 BMU
 SG_ BMU_M04_V00 : 0|16@1+ (1,0) [0|65535] "mV" LOGGER
 SG_ BMU_M04_V01 : 16|16@1+ (1,0) [0|65535] "mV" LOGGER
 SG_ BMU_M04_V02 : 32|16@1+ (1,0) [0|65535] "mV" LOGGER
 SG_ BMU_M04_VAge0 : 48|16@1+ (1,0) [0|65535] "ms" LOGGER

BO_ 2284093505 BMU_TransmitVoltage_N_4_P_1: 8 BMU
 SG_ BMU_M04_V03 : 0|16@1+ (1,0) [0|65535] "mV" LOGGER
 SG_ BMU_M04_V04 : 16|16@1+ (1,0) [0|65535] "mV" LOGGER
 SG_ BMU_M04_V05 : 32|16@1+ (1,0) [0|65535] "mV" LOGGER
 SG_ BMU_M04_VAge1 : 48|16@1+ (1,0) [0|65535] "ms" LOGGER

BO_ 2284093506 BMU_TransmitVoltage_N_4_P_2: 8 BMU
 SG_ BMU_M04_V06 : 0|16@1+ (1,0) [0|65535] "mV" LOGGER
 SG_ BMU_M04_V07 : 16|16@1+ (1,0) [0|65535] "mV" LOGGER
 SG_ BMU_M04_V08 : 32|16@1+ (1,0) [0|65535] "mV" LOGGER
 SG_ BMU_M04_VAge2 : 48|16@1+ (1,0) [0|65535] "ms" LOGGER

BO_ 2284093507 BMU_TransmitVoltage_N_4_P_3: 8 BMU
 SG_ BMU_M04_V09 : 0|16@1+ (1,0) [0|65535] "mV" LOGGER
 SG_ BMU_M04_V10 : 16|16@1+ (1,0) [0|65535] "mV" LOGGER
 SG_ BMU_M04_V11 : 32|16@1+ (1,0) [0|65535] "mV" LOGGER
 SG_ BMU_M04_VAge3 : 48|16@1+ (1,0) [0|65535] "ms" LOGGER

BO_ 2284093520 BMU_TransmitVoltage_N_5_P_0: 8 BMU
 SG_ BMU_M05_V00 : 0|16@1+ (1,0) [0|65535] "mV" LOGGER
 SG_ BMU_M05_V01 : 16|16@1+ (1,0) [0|65535] "mV" LOGGER
 SG_ BMU_M05_V02 : 32|16@1+ (1,0) [0|65535] "mV" LOGGER
 SG_ BMU_M05_VAge0 : 48|16@1+ (1,0) [0|65535] "ms" LOGGER

BO_ 2284093521 BMU_TransmitVoltage_N_5_P_1: 8 BMU
 SG_ BMU_M05_V03 : 0|16@1+ (1,0) [0|65535] "mV" LOGGER
 SG_ BMU_M05_V04 : 16|16@1+ (1,0) [0|65535] "mV" LOGGER
 SG_ BMU_M05_V05 : 32|16@1+ (1,0) [0|65535] "mV" LOGGER
 SG_ BMU_M05_VAge1 : 48|16@1+ (1,0) [0|65535] "ms" LOGGER

BO_ 2284093522 BMU_TransmitVoltage_N_5_P_2: 8 BMU
 SG_ BMU_M05_V06 : 0|16@1+ (1,0) [0|65535] "mV" LOGGER
 SG_ BMU_M05_V07 : 16|16@1+ (1,0) [0|65535] "mV" LOGGER
 SG_ BMU_M05_V08 : 32|16@1+ (1,0) [0|65535] "mV" LOGGER
 SG_ BMU_M05_VAge2 : 48|16@1+ (1,0) [0|65535] "ms" LOGGER

BO_ 2284093523 BMU_TransmitVoltage_N_5_P_3: 8 BMU
 SG_ BMU_M05_V09 : 0|16@1+ (1,0) [0|65535] "mV" LOGGER
 SG_ BMU_M05_V10 : 16|16@1+ (1,0) [0|65535] "mV" LOGGER
 SG_ BMU_M05_V11 : 32|16@1+ (1,0) [0|65535] "mV" LOGGER
 SG_ BMU_M05_VAge3 : 48|16@1+ (1,0) [0|65535] "ms" LOGGER

BO_ 2284093536 BMU_TransmitVoltage_N_6_P_0: 8 BMU
 SG_ BMU_M06_V00 : 0|16@1+ (1,0) [0|65535] "mV" LOGGER
 SG_ BMU_M06_V01 : 16|16@1+ (1,0) [0|65535] "mV" LOGGER
 SG_ BMU_M06_V02 : 32|16@1+ (1,0) [0|65535] "mV" LOGGER
 SG_ BMU_M06_VAge0 : 48|16@1+ (1,0) [0|65535] "ms" LOGGER

BO_ 2284093537 BMU_TransmitVoltage_N_6_P_1: 8 BMU
 SG_ BMU_M06_V03 : 0|16@1+ (1,0) [0|65535] "mV" LOGGER
 SG_ BMU_M06_V04 : 16|16@1+ (1,0) [0|65535] "mV" LOGGER
 SG_ BMU_M06_V05 : 32|16@1+ (1,0) [0|65535] "mV" LOGGER
 SG_ BMU_M06_VAge1 : 48|16@1+ (1,0) [0|65535] "ms" LOGGER

BO_ 2284093538 BMU_TransmitVoltage_N_6_P_2: 8 BMU
 SG_ BMU_M06_V06 : 0|16@1+ (1,0) [0|65535] "mV" LOGGER
 SG_ BMU_M06_V07 : 16|16@1+ (1,0) [0|65535] "mV" LOGGER
 SG_ BMU_M06_V08 : 32|16@1+ (1,0) [0|65535] "mV" LOGGER
 SG_ BMU_M06_VAge2 : 48|16@1+ (1,0) [0|65535] "ms" LOGGER

BO_ 2284093539 BMU_TransmitVoltage_N_6_P_3: 8 BMU
 SG_ BMU_M06_V09 : 0|16@1+ (1,0) [0|65535] "mV" LOGGER
 SG_ BMU_M06_V10 : 16|16@1+ (1,0) [0|65535] "mV" LOGGER
 SG_ BMU_M06_V11 : 32|16@1+ (1,0) [0|65535] "mV" LOGGER
 SG_ BMU_M06_VAge3 : 48|16@1+ (1,0) [0|65535] "ms" LOGGER

BO_ 2284093552 BMU_TransmitVoltage_N_7_P_0: 8 BMU
 SG_ BMU_M07_V00 : 0|16@1+ (1,0) [0|65535] "mV" LOGGER
 SG_ BMU_M07_V01 : 16|16@1+ (1,0) [0|65535] "mV" LOGGER
 SG_ BMU_M07_V02 : 32|16@1+ (1,0) [0|65535] "mV" LOGGER
 SG_ BMU_M07_VAge0 : 48|16@1+ (1,0) [0|65535] "ms" LOGGER

BO_ 2284093553 BMU_TransmitVoltage_N_7_P_1: 8 BMU
 SG_ BMU_M07_V03 : 0|16@1+ (1,0) [0|65535] "mV" LOGGER
 SG_ BMU_M07_V04 : 16|16@1+ (1,0) [0|65535] "mV" LOGGER
 SG_ BMU_M07_V05 : 32|16@1+ (1,0) [0|65535] "mV" LOGGER
 SG_ BMU_M07_VAge1 : 48|16@1+ (1,0) [0|65535] "ms" LOGGER

BO_ 2284093554 BMU_TransmitVoltage_N_7_P_2: 8 BMU
 SG_ BMU_M07_V06 : 0|16@1+ (1,0) [0|65535] "mV" LOGGER
 SG_ BMU_M07_V07 : 16|16@1+ (1,0) [0|65535] "mV" LOGGER
 SG_ BMU_M07_V08 : 32|16@1+ (1,0) [0|65535] "mV" LOGGER
 SG_ BMU_M07_VAge2 : 48|16@1+ (1,0) [0|65535] "ms" LOGGER

BO_ 2284093555 BMU_TransmitVoltage_N_7_P_3: 8 BMU
 SG_ BMU_M07_V09 : 0|16@1+ (1,0) [0|65535] "mV" LOGGER
 SG_ BMU_M07_V10 : 16|16@1+ (1,0) [0|65535] "mV" LOGGER
 SG_ BMU_M07_V11 : 32|16@1+ (1,0) [0|65535] "mV" LOGGER
 SG_ BMU_M07_VAge3 : 48|16@1+ (1,0) [0|65535] "ms" LOGGER

BO_ 2284093568 BMU_TransmitVoltage_N_8_P_0: 8 BMU
 SG_ BMU_M08_V00 : 0|16@1+ (1,0) [0|65535] "mV" LOGGER
 SG_ BMU_M08_V01 : 16|16@1+ (1,0) [0|65535] "mV" LOGGER
 SG_ BMU_M08_V02 : 32|16@1+ (1,0) [0|65535] "mV" LOGGER
 SG_ BMU_M08_VAge0 : 48|16@1+ (1,0) [0|65535] "ms" LOGGER

BO_ 2284093569 BMU_TransmitVoltage_N_8_P_1: 8 BMU
 SG_ BMU_M08_V03 : 0|16@1+ (1,0) [0|65535] "mV" LOGGER
 SG_ BMU_M08_V04 : 16|16@1+ (1,0) [0|65535] "mV" LOGGER
 SG_ BMU_M08_V05 : 32|16@1+ (1,0) [0|65535] "mV" LOGGER
 SG_ BMU_M08_VAge1 : 48|16@1+ (1,0) [0|65535] "ms" LOGGER

BO_ 2284093570 BMU_TransmitVoltage_N_8_P_2: 8 BMU
 SG_ BMU_M08_V06 : 0|16@1+ (1,0) [0|65535] "mV" LOGGER
 SG_ BMU_M08_V07 : 16|16@1+ (1,0) [0|65535] "mV" LOGGER
 SG_ BMU_M08_V08 : 32|16@1+ (1,0) [0|65535] "mV" LOGGER
 SG_ BMU_M08_VAge2 : 48|16@1+ (1,0) [0|65535] "ms" LOGGER

BO_ 2284093571 BMU_TransmitVoltage_N_8_P_3: 8 BMU
 SG_ BMU_M08_V09 : 0|16@1+ (1,0) [0|65535] "mV" LOGGER
 SG_ BMU_M08_V10 : 16|16@1+ (1,0) [0|65535] "mV" LOGGER
 SG_ BMU_M08_V11 : 32|16@1+ (1,0) [0|65535] "mV" LOGGER
 SG_ BMU_M08_VAge3 : 48|16@1+ (1,0) [0|65535] "ms" LOGGER

BO_ 2284093584 BMU_TransmitVoltage_N_9_P_0: 8 BMU
 SG_ BMU_M09_V00 : 0|16@1+ (1,0) [0|65535] "mV" LOGGER
 SG_ BMU_M09_V01 : 16|16@1+ (1,0) [0|65535] "mV" LOGGER
 SG_ BMU_M09_V02 : 32|16@1+ (1,0) [0|65535] "mV" LOGGER
 SG_ BMU_M09_VAge0 : 48|16@1+ (1,0) [0|65535] "ms" LOGGER

BO_ 2284093585 BMU_TransmitVoltage_N_9_P_1: 8 BMU
 SG_ BMU_M09_V03 : 0|16@1+ (1,0) [0|65535] "mV" LOGGER
 SG_ BMU_M09_V04 : 16|16@1+ (1,0) [0|65535] "mV" LOGGER
 SG_ BMU_M09_V05 : 32|16@1+ (1,0) [0|65535] "mV" LOGGER
 SG_ BMU_M09_VAge1 : 48|16@1+ (1,0) [0|65535] "ms" LOGGER

BO_ 2284093586 BMU_TransmitVoltage_N_9_P_2: 8 BMU
 SG_ BMU_M09_V06 : 0|16@1+ (1,0) [0|65535] "mV" LOGGER
 SG_ BMU_M09_V07 : 16|16@1+ (1,0) [0|65535] "mV" LOGGER
 SG_ BMU_M09_V08 : 32|16@1+ (1,0) [0|65535] "mV" LOGGER
 SG_ BMU_M09_VAge2 : 48|16@1+ (1,0) [0|65535] "ms" LOGGER

BO_ 2284093587 BMU_TransmitVoltage_N_9_P_3: 8 BMU
 SG_ BMU_M09_V09 : 0|16@1+ (1,0) [0|65535] "mV" LOGGER
 SG_ BMU_M09_V10 : 16|16@1+ (1,0) [0|65535] "mV" LOGGER
 SG_ BMU_M09_V11 : 32|16@1+ (1,0) [0|65535] "mV" LOGGER
 SG_ BMU_M09_VAge3 : 48|16@1+ (1,0) [0|65535] "ms" LOGGER

BO_ 2284093600 BMU_TransmitVoltage_N_10_P_0: 8 BMU
 SG_ BMU_M10_V00 : 0|16@1+ (1,0) [0|65535] "mV" LOGGER
 SG_ BMU_M10_V01 : 16|16@1+ (1,0) [0|65535] "mV" LOGGER
 SG_ BMU_M10_V02 : 32|16@1+ (1,0) [0|65535] "mV" LOGGER
 SG_ BMU_M10_VAge0 : 48|16@1+ (1,0) [0|65535] "ms" LOGGER

BO_ 2284093601 BMU_TransmitVoltage_N_10_P_1: 8 BMU
 SG_ BMU_M10_V03 : 0|16@1+ (1,0) [0|65535] "mV" LOGGER
 SG_ BMU_M10_V04 : 16|16@1+ (1,0) [0|65535] "mV" LOGGER
 SG_ BMU_M10_V05 : 32|16@1+ (1,0) [0|65535] "mV" LOGGER
 SG_ BMU_M10_VAge1 : 48|16@1+ (1,0) [0|65535] "ms" LOGGER

BO_ 2284093602 BMU_TransmitVoltage_N_10_P_2: 8 BMU
 SG_ BMU_M10_V06 : 0|16@1+ (1,0) [0|65535] "mV" LOGGER
 SG_ BMU_M10_V07 : 16|16@1+ (1,0) [0|65535] "mV" LOGGER
 SG_ BMU_M10_V08 : 32|16@1+ (1,0) [0|65535] "mV" LOGGER
 SG_ BMU_M10_VAge2 : 48|16@1+ (1,0) [0|65535] "ms" LOGGER

BO_ 2284093603 BMU_TransmitVoltage_N_10_P_3: 8 BMU
 SG_ BMU_M10_V09 : 0|16@1+ (1,0) [0|65535] "mV" LOGGER
 SG_ BMU_M10_V10 : 16|16@1+ (1,0) [0|65535] "mV" LOGGER
 SG_ BMU_M10_V11 : 32|16@1+ (1,0) [0|65535] "mV" LOGGER
 SG_ BMU_M10_VAge3 : 48|16@1+ (1,0) [0|65535] "ms" LOGGER

BO_ 2284093616 BMU_TransmitVoltage_N_11_P_0: 8 BMU
 SG_ BMU_M11_V00 : 0|16@1+ (1,0) [0|65535] "mV" LOGGER
 SG_ BMU_M11_V01 : 16|16@1+ (1,0) [0|65535] "mV" LOGGER
 SG_ BMU_M11_V02 : 32|16@1+ (1,0) [0|65535] "mV" LOGGER
 SG_ BMU_M11_VAge0 : 48|16@1+ (1,0) [0|65535] "ms" LOGGER

BO_ 2284093617 BMU_TransmitVoltage_N_11_P_1: 8 BMU
 SG_ BMU_M11_V03 : 0|16@1+ (1,0) [0|65535] "mV" LOGGER
 SG_ BMU_M11_V04 : 16|16@1+ (1,0) [0|65535] "mV" LOGGER
 SG_ BMU_M11_V05 : 32|16@1+ (1,0) [0|65535] "mV" LOGGER
 SG_ BMU_M11_VAge1 : 48|16@1+ (1,0) [0|65535] "ms" LOGGER

BO_ 2284093618 BMU_TransmitVoltage_N_11_P_2: 8 BMU
 SG_ BMU_M11_V06 : 0|16@1+ (1,0) [0|65535] "mV" LOGGER
 SG_ BMU_M11_V07 : 16|16@1+ (1,0) [0|65535] "mV" LOGGER
 SG_ BMU_M11_V08 : 32|16@1+ (1,0) [0|65535] "mV" LOGGER
 SG_ BMU_M11_VAge2 : 48|16@1+ (1,0) [0|65535] "ms" LOGGER

BO_ 2284093619 BMU_TransmitVoltage_N_11_P_3: 8 BMU
 SG_ BMU_M11_V09 : 0|16@1+ (1,0) [0|65535] "mV" LOGGER
 SG_ BMU_M11_V10 : 16|16@1+ (1,0) [0|65535] "mV" LOGGER
 SG_ BMU_M11_V11 : 32|16@1+ (1,0) [0|65535] "mV" LOGGER
 SG_ BMU_M11_VAge3 : 48|16@1+ (1,0) [0|65535] "ms" LOGGER

BO_ 2284093632 BMU_TransmitVoltage_N_12_P_0: 8 BMU
 SG_ BMU_M12_V00 : 0|16@1+ (1,0) [0|65535] "mV" LOGGER
 SG_ BMU_M12_V01 : 16|16@1+ (1,0) [0|65535] "mV" LOGGER
 SG_ BMU_M12_V02 : 32|16@1+ (1,0) [0|65535] "mV" LOGGER
 SG_ BMU_M12_VAge0 : 48|16@1+ (1,0) [0|65535] "ms" LOGGER

BO_ 2284093633 BMU_TransmitVoltage_N_12_P_1: 8 BMU
 SG_ BMU_M12_V03 : 0|16@1+ (1,0) [0|65535] "mV" LOGGER
 SG_ BMU_M12_V04 : 16|16@1+ (1,0) [0|65535] "mV" LOGGER
 SG_ BMU_M12_V05 : 32|16@1+ (1,0) [0|65535] "mV" LOGGER
 SG_ BMU_M12_VAge1 : 48|16@1+ (1,0) [0|65535] "ms" LOGGER

BO_ 2284093634 BMU_TransmitVoltage_N_12_P_2: 8 BMU
 SG_ BMU_M12_V06 : 0|16@1+ (1,0) [0|65535] "mV" LOGGER
 SG_ BMU_M12_V07 : 16|16@1+ (1,0) [0|65535] "mV" LOGGER
 SG_ BMU_M12_V08 : 32|16@1+ (1,0) [0|65535] "mV" LOGGER
 SG_ BMU_M12_VAge2 : 48|16@1+ (1,0) [0|65535] "ms" LOGGER

BO_ 2284093635 BMU_TransmitVoltage_N_12_P_3: 8 BMU
 SG_ BMU_M12_V09 : 0|16@1+ (1,0) [0|65535] "mV" LOGGER
 SG_ BMU_M12_V10 : 16|16@1+ (1,0) [0|65535] "mV" LOGGER
 SG_ BMU_M12_V11 : 32|16@1+ (1,0) [0|65535] "mV" LOGGER
 SG_ BMU_M12_VAge3 : 48|16@1+ (1,0) [0|65535] "ms" LOGGER

BO_ 2284093648 BMU_TransmitVoltage_N_13_P_0: 8 BMU
 SG_ BMU_M13_V00 : 0|16@1+ (1,0) [0|65535] "mV" LOGGER
 SG_ BMU_M13_V01 : 16|16@1+ (1,0) [0|65535] "mV" LOGGER
 SG_ BMU_M13_V02 : 32|16@1+ (1,0) [0|65535] "mV" LOGGER
 SG_ BMU_M13_VAge0 : 48|16@1+ (1,0) [0|65535] "ms" LOGGER

BO_ 2284093649 BMU_TransmitVoltage_N_13_P_1: 8 BMU
 SG_ BMU_M13_V03 : 0|16@1+ (1,0) [0|65535] "mV" LOGGER
 SG_ BMU_M13_V04 : 16|16@1+ (1,0) [0|65535] "mV" LOGGER
 SG_ BMU_M13_V05 : 32|16@1+ (1,0) [0|65535] "mV" LOGGER
 SG_ BMU_M13_VAge1 : 48|16@1+ (1,0) [0|65535] "ms" LOGGER

BO_ 2284093650 BMU_TransmitVoltage_N_13_P_2: 8 BMU
 SG_ BMU_M13_V06 : 0|16@1+ (1,0) [0|65535] "mV" LOGGER
 SG_ BMU_M13_V07 : 16|16@1+ (1,0) [0|65535] "mV" LOGGER
 SG_ BMU_M13_V08 : 32|16@1+ (1,0) [0|65535] "mV" LOGGER
 SG_ BMU_M13_VAge2 : 48|16@1+ (1,0) [0|65535] "ms" LOGGER

BO_ 2284093651 BMU_TransmitVoltage_N_13_P_3: 8 BMU
 SG_ BMU_M13_V09 : 0|16@1+ (1,0) [0|65535] "mV" LOGGER
 SG_ BMU_M13_V10 : 16|16@1+ (1,0) [0|65535] "mV" LOGGER
 SG_ BMU_M13_V11 : 32|16@1+ (1,0) [0|65535] "mV" LOGGER
 SG_ BMU_M13_VAge3 : 48|16@1+ (1,0) [0|65535] "ms" LOGGER

BO_ 2284093664 BMU_TransmitVoltage_N_14_P_0: 8 BMU
 SG_ BMU_M14_V00 : 0|16@1+ (1,0) [0|65535] "mV" LOGGER
 SG_ BMU_M14_V01 : 16|16@1+ (1,0) [0|65535] "mV" LOGGER
 SG_ BMU_M14_V02 : 32|16@1+ (1,0) [0|65535] "mV" LOGGER
 SG_ BMU_M14_VAge0 : 48|16@1+ (1,0) [0|65535] "ms" LOGGER

BO_ 2284093665 BMU_TransmitVoltage_N_14_P_1: 8 BMU
 SG_ BMU_M14_V03 : 0|16@1+ (1,0) [0|65535] "mV" LOGGER
 SG_ BMU_M14_V04 : 16|16@1+ (1,0) [0|65535] "mV" LOGGER
 SG_ BMU_M14_V05 : 32|16@1+ (1,0) [0|65535] "mV" LOGGER
 SG_ BMU_M14_VAge1 : 48|16@1+ (1,0) [0|65535] "ms" LOGGER

BO_ 2284093666 BMU_TransmitVoltage_N_14_P_2: 8 BMU
 SG_ BMU_M14_V06 : 0|16@1+ (1,0) [0|65535] "mV" LOGGER
 SG_ BMU_M14_V07 : 16|16@1+ (1,0) [0|65535] "mV" LOGGER
 SG_ BMU_M14_V08 : 32|16@1+ (1,0) [0|65535] "mV" LOGGER
 SG_ BMU_M14_VAge2 : 48|16@1+ (1,0) [0|65535] "ms" LOGGER

BO_ 2284093667 BMU_TransmitVoltage_N_14_P_3: 8 BMU
 SG_ BMU_M14_V09 : 0|16@1+ (1,0) [0|65535] "mV" LOGGER
 SG_ BMU_M14_V10 : 16|16@1+ (1,0) [0|65535] "mV" LOGGER
 SG_ BMU_M14_V11 : 32|16@1+ (1,0) [0|65535] "mV" LOGGER
 SG_ BMU_M14_VAge3 : 48|16@1+ (1,0) [0|65535] "ms" LOGGER

BO_ 2284093680 BMU_TransmitVoltage_N_15_P_0: 8 BMU
 SG_ BMU_M15_V00 : 0|16@1+ (1,0) [0|65535] "mV" LOGGER
 SG_ BMU_M15_V01 : 16|16@1+ (1,0) [0|65535] "mV" LOGGER
 SG_ BMU_M15_V02 : 32|16@1+ (1,0) [0|65535] "mV" LOGGER
 SG_ BMU_M15_VAge0 : 48|16@1+ (1,0) [0|65535] "ms" LOGGER

BO_ 2284093681 BMU_TransmitVoltage_N_15_P_1: 8 BMU
 SG_ BMU_M15_V03 : 0|16@1+ (1,0) [0|65535] "mV" LOGGER
 SG_ BMU_M15_V04 : 16|16@1+ (1,0) [0|65535] "mV" LOGGER
 SG_ BMU_M15_V05 : 32|16@1+ (1,0) [0|65535] "mV" LOGGER
 SG_ BMU_M15_VAge1 : 48|16@1+ (1,0) [0|65535] "ms" LOGGER

BO_ 2284093682 BMU_TransmitVoltage_N_15_P_2: 8 BMU
 SG_ BMU_M15_V06 : 0|16@1+ (1,0) [0|65535] "mV" LOGGER
 SG_ BMU_M15_V07 : 16|16@1+ (1,0) [0|65535] "mV" LOGGER
 SG_ BMU_M15_V08 : 32|16@1+ (1,0) [0|65535] "mV" LOGGER
 SG_ BMU_M15_VAge2 : 48|16@1+ (1,0) [0|65535] "ms" LOGGER

BO_ 2284093683 BMU_TransmitVoltage_N_15_P_3: 8 BMU
 SG_ BMU_M15_V09 : 0|16@1+ (1,0) [0|65535] "mV" LOGGER
 SG_ BMU_M15_V10 : 16|16@1+ (1,0) [0|65535] "mV" LOGGER
 SG_ BMU_M15_V11 : 32|16@1+ (1,0) [0|65535] "mV" LOGGER
 SG_ BMU_M15_VAge3 : 48|16@1+ (1,0) [0|65535] "ms" LOGGER

BO_ 2284093696 BMU_TransmitVoltage_N_16_P_0: 8 BMU
 SG_ BMU_M16_V00 : 0|16@1+ (1,0) [0|65535] "mV" LOGGER
 SG_ BMU_M16_V01 : 16|16@1+ (1,0) [0|65535] "mV" LOGGER
 SG_ BMU_M16_V02 : 32|16@1+ (1,0) [0|65535] "mV" LOGGER
 SG_ BMU_M16_VAge0 : 48|16@1+ (1,0) [0|65535] "ms" LOGGER

BO_ 2284093697 BMU_TransmitVoltage_N_16_P_1: 8 BMU
 SG_ BMU_M16_V03 : 0|16@1+ (1,0) [0|65535] "mV" LOGGER
 SG_ BMU_M16_V04 : 16|16@1+ (1,0) [0|65535] "mV" LOGGER
 SG_ BMU_M16_V05 : 32|16@1+ (1,0) [0|65535] "mV" LOGGER
 SG_ BMU_M16_VAge1 : 48|16@1+ (1,0) [0|65535] "ms" LOGGER

BO_ 2284093698 BMU_TransmitVoltage_N_16_P_2: 8 BMU
 SG_ BMU_M16_V06 : 0|16@1+ (1,0) [0|65535] "mV" LOGGER
 SG_ BMU_M16_V07 : 16|16@1+ (1,0) [0|65535] "mV" LOGGER
 SG_ BMU_M16_V08 : 32|16@1+ (1,0) [0|65535] "mV" LOGGER
 SG_ BMU_M16_VAge2 : 48|16@1+ (1,0) [0|65535] "ms" LOGGER

BO_ 2284093699 BMU_TransmitVoltage_N_16_P_3: 8 BMU
 SG_ BMU_M16_V09 : 0|16@1+ (1,0) [0|65535] "mV" LOGGER
 SG_ BMU_M16_V10 : 16|16@1+ (1,0) [0|65535] "mV" LOGGER
 SG_ BMU_M16_V11 : 32|16@1+ (1,0) [0|65535] "mV" LOGGER
 SG_ BMU_M16_VAge3 : 48|16@1+ (1,0) [0|65535] "ms" LOGGER

BO_ 2284093712 BMU_TransmitVoltage_N_17_P_0: 8 BMU
 SG_ BMU_M17_V00 : 0|16@1+ (1,0) [0|65535] "mV" LOGGER
 SG_ BMU_M17_V01 : 16|16@1+ (1,0) [0|65535] "mV" LOGGER
 SG_ BMU_M17_V02 : 32|16@1+ (1,0) [0|65535] "mV" LOGGER
 SG_ BMU_M17_VAge0 : 48|16@1+ (1,0) [0|65535] "ms" LOGGER

BO_ 2284093713 BMU_TransmitVoltage_N_17_P_1: 8 BMU
 SG_ BMU_M17_V03 : 0|16@1+ (1,0) [0|65535] "mV" LOGGER
 SG_ BMU_M17_V04 : 16|16@1+ (1,0) [0|65535] "mV" LOGGER
 SG_ BMU_M17_V05 : 32|16@1+ (1,0) [0|65535] "mV" LOGGER
 SG_ BMU_M17_VAge1 : 48|16@1+ (1,0) [0|65535] "ms" LOGGER

BO_ 2284093714 BMU_TransmitVoltage_N_17_P_2: 8 BMU
 SG_ BMU_M17_V06 : 0|16@1+ (1,0) [0|65535] "mV" LOGGER
 SG_ BMU_M17_V07 : 16|16@1+ (1,0) [0|65535] "mV" LOGGER
 SG_ BMU_M17_V08 : 32|16@1+ (1,0) [0|65535] "mV" LOGGER
 SG_ BMU_M17_VAge2 : 48|16@1+ (1,0) [0|65535] "ms" LOGGER

BO_ 2284093715 BMU_TransmitVoltage_N_17_P_3: 8 BMU
 SG_ BMU_M17_V09 : 0|16@1+ (1,0) [0|65535] "mV" LOGGER
 SG_ BMU_M17_V10 : 16|16@1+ (1,0) [0|65535] "mV" LOGGER
 SG_ BMU_M17_V11 : 32|16@1+ (1,0) [0|65535] "mV" LOGGER
 SG_ BMU_M17_VAge3 : 48|16@1+ (1,0) [0|65535] "ms" LOGGER

BO_ 2284093728 BMU_TransmitVoltage_N_18_P_0: 8 BMU
 SG_ BMU_M18_V00 : 0|16@1+ (1,0) [0|65535] "mV" LOGGER
 SG_ BMU_M18_V01 : 16|16@1+ (1,0) [0|65535] "mV" LOGGER
 SG_ BMU_M18_V02 : 32|16@1+ (1,0) [0|65535] "mV" LOGGER
 SG_ BMU_M18_VAge0 : 48|16@1+ (1,0) [0|65535] "ms" LOGGER

BO_ 2284093729 BMU_TransmitVoltage_N_18_P_1: 8 BMU
 SG_ BMU_M18_V03 : 0|16@1+ (1,0) [0|65535] "mV" LOGGER
 SG_ BMU_M18_V04 : 16|16@1+ (1,0) [0|65535] "mV" LOGGER
 SG_ BMU_M18_V05 : 32|16@1+ (1,0) [0|65535] "mV" LOGGER
 SG_ BMU_M18_VAge1 : 48|16@1+ (1,0) [0|65535] "ms" LOGGER

BO_ 2284093730 BMU_TransmitVoltage_N_18_P_2: 8 BMU
 SG_ BMU_M18_V06 : 0|16@1+ (1,0) [0|65535] "mV" LOGGER
 SG_ BMU_M18_V07 : 16|16@1+ (1,0) [0|65535] "mV" LOGGER
 SG_ BMU_M18_V08 : 32|16@1+ (1,0) [0|65535] "mV" LOGGER
 SG_ BMU_M18_VAge2 : 48|16@1+ (1,0) [0|65535] "ms" LOGGER

BO_ 2284093731 BMU_TransmitVoltage_N_18_P_3: 8 BMU
 SG_ BMU_M18_V09 : 0|16@1+ (1,0) [0|65535] "mV" LOGGER
 SG_ BMU_M18_V10 : 16|16@1+ (1,0) [0|65535] "mV" LOGGER
 SG_ BMU_M18_V11 : 32|16@1+ (1,0) [0|65535] "mV" LOGGER
 SG_ BMU_M18_VAge3 : 48|16@1+ (1,0) [0|65535] "ms" LOGGER

BO_ 2284093744 BMU_TransmitVoltage_N_19_P_0: 8 BMU
 SG_ BMU_M19_V00 : 0|16@1+ (1,0) [0|65535] "mV" LOGGER
 SG_ BMU_M19_V01 : 16|16@1+ (1,0) [0|65535] "mV" LOGGER
 SG_ BMU_M19_V02 : 32|16@1+ (1,0) [0|65535] "mV" LOGGER
 SG_ BMU_M19_VAge0 : 48|16@1+ (1,0) [0|65535] "ms" LOGGER

BO_ 2284093745 BMU_TransmitVoltage_N_19_P_1: 8 BMU
 SG_ BMU_M19_V03 : 0|16@1+ (1,0) [0|65535] "mV" LOGGER
 SG_ BMU_M19_V04 : 16|16@1+ (1,0) [0|65535] "mV" LOGGER
 SG_ BMU_M19_V05 : 32|16@1+ (1,0) [0|65535] "mV" LOGGER
 SG_ BMU_M19_VAge1 : 48|16@1+ (1,0) [0|65535] "ms" LOGGER

BO_ 2284093746 BMU_TransmitVoltage_N_19_P_2: 8 BMU
 SG_ BMU_M19_V06 : 0|16@1+ (1,0) [0|65535] "mV" LOGGER
 SG_ BMU_M19_V07 : 16|16@1+ (1,0) [0|65535] "mV" LOGGER
 SG_ BMU_M19_V08 : 32|16@1+ (1,0) [0|65535] "mV" LOGGER
 SG_ BMU_M19_VAge2 : 48|16@1+ (1,0) [0|65535] "ms" LOGGER

BO_ 2284093747 BMU_TransmitVoltage_N_19_P_3: 8 BMU
 SG_ BMU_M19_V09 : 0|16@1+ (1,0) [0|65535] "mV" LOGGER
 SG_ BMU_M19_V10 : 16|16@1+ (1,0) [0|65535] "mV" LOGGER
 SG_ BMU_M19_V11 : 32|16@1+ (1,0) [0|65535] "mV" LOGGER
 SG_ BMU_M19_VAge3 : 48|16@1+ (1,0) [0|65535] "ms" LOGGER

BO_ 2284093760 BMU_TransmitVoltage_N_20_P_0: 8 BMU
 SG_ BMU_M20_V00 : 0|16@1+ (1,0) [0|65535] "mV" LOGGER
 SG_ BMU_M20_V01 : 16|16@1+ (1,0) [0|65535] "mV" LOGGER
 SG_ BMU_M20_V02 : 32|16@1+ (1,0) [0|65535] "mV" LOGGER
 SG_ BMU_M20_VAge0 : 48|16@1+ (1,0) [0|65535] "ms" LOGGER

BO_ 2284093761 BMU_TransmitVoltage_N_20_P_1: 8 BMU
 SG_ BMU_M20_V03 : 0|16@1+ (1,0) [0|65535] "mV" LOGGER
 SG_ BMU_M20_V04 : 16|16@1+ (1,0) [0|65535] "mV" LOGGER
 SG_ BMU_M20_V05 : 32|16@1+ (1,0) [0|65535] "mV" LOGGER
 SG_ BMU_M20_VAge1 : 48|16@1+ (1,0) [0|65535] "ms" LOGGER

BO_ 2284093762 BMU_TransmitVoltage_N_20_P_2: 8 BMU
 SG_ BMU_M20_V06 : 0|16@1+ (1,0) [0|65535] "mV" LOGGER
 SG_ BMU_M20_V07 : 16|16@1+ (1,0) [0|65535] "mV" LOGGER
 SG_ BMU_M20_V08 : 32|16@1+ (1,0) [0|65535] "mV" LOGGER
 SG_ BMU_M20_VAge2 : 48|16@1+ (1,0) [0|65535] "ms" LOGGER

BO_ 2284093763 BMU_TransmitVoltage_N_20_P_3: 8 BMU
 SG_ BMU_M20_V09 : 0|16@1+ (1,0) [0|65535] "mV" LOGGER
 SG_ BMU_M20_V10 : 16|16@1+ (1,0) [0|65535] "mV" LOGGER
 SG_ BMU_M20_V11 : 32|16@1+ (1,0) [0|65535] "mV" LOGGER
 SG_ BMU_M20_VAge3 : 48|16@1+ (1,0) [0|65535] "ms" LOGGER

BO_ 2284093776 BMU_TransmitVoltage_N_21_P_0: 8 BMU
 SG_ BMU_M21_V00 : 0|16@1+ (1,0) [0|65535] "mV" LOGGER
 SG_ BMU_M21_V01 : 16|16@1+ (1,0) [0|65535] "mV" LOGGER
 SG_ BMU_M21_V02 : 32|16@1+ (1,0) [0|65535] "mV" LOGGER
 SG_ BMU_M21_VAge0 : 48|16@1+ (1,0) [0|65535] "ms" LOGGER

BO_ 2284093777 BMU_TransmitVoltage_N_21_P_1: 8 BMU
 SG_ BMU_M21_V03 : 0|16@1+ (1,0) [0|65535] "mV" LOGGER
 SG_ BMU_M21_V04 : 16|16@1+ (1,0) [0|65535] "mV" LOGGER
 SG_ BMU_M21_V05 : 32|16@1+ (1,0) [0|65535] "mV" LOGGER
 SG_ BMU_M21_VAge1 : 48|16@1+ (1,0) [0|65535] "ms" LOGGER

BO_ 2284093778 BMU_TransmitVoltage_N_21_P_2: 8 BMU
 SG_ BMU_M21_V06 : 0|16@1+ (1,0) [0|65535] "mV" LOGGER
 SG_ BMU_M21_V07 : 16|16@1+ (1,0) [0|65535] "mV" LOGGER
 SG_ BMU_M21_V08 : 32|16@1+ (1,0) [0|65535] "mV" LOGGER
 SG_ BMU_M21_VAge2 : 48|16@1+ (1,0) [0|65535] "ms" LOGGER

BO_ 2284093779 BMU_TransmitVoltage_N_21_P_3: 8 BMU
 SG_ BMU_M21_V09 : 0|16@1+ (1,0) [0|65535] "mV" LOGGER
 SG_ BMU_M21_V10 : 16|16@1+ (1,0) [0|65535] "mV" LOGGER
 SG_ BMU_M21_V11 : 32|16@1+ (1,0) [0|65535] "mV" LOGGER
 SG_ BMU_M21_VAge3 : 48|16@1+ (1,0) [0|65535] "ms" LOGGER

BO_ 2284093792 BMU_TransmitVoltage_N_22_P_0: 8 BMU
 SG_ BMU_M22_V00 : 0|16@1+ (1,0) [0|65535] "mV" LOGGER
 SG_ BMU_M22_V01 : 16|16@1+ (1,0) [0|65535] "mV" LOGGER
 SG_ BMU_M22_V02 : 32|16@1+ (1,0) [0|65535] "mV" LOGGER
 SG_ BMU_M22_VAge0 : 48|16@1+ (1,0) [0|65535] "ms" LOGGER

BO_ 2284093793 BMU_TransmitVoltage_N_22_P_1: 8 BMU
 SG_ BMU_M22_V03 : 0|16@1+ (1,0) [0|65535] "mV" LOGGER
 SG_ BMU_M22_V04 : 16|16@1+ (1,0) [0|65535] "mV" LOGGER
 SG_ BMU_M22_V05 : 32|16@1+ (1,0) [0|65535] "mV" LOGGER
 SG_ BMU_M22_VAge1 : 48|16@1+ (1,0) [0|65535] "ms" LOGGER

BO_ 2284093794 BMU_TransmitVoltage_N_22_P_2: 8 BMU
 SG_ BMU_M22_V06 : 0|16@1+ (1,0) [0|65535] "mV" LOGGER
 SG_ BMU_M22_V07 : 16|16@1+ (1,0) [0|65535] "mV" LOGGER
 SG_ BMU_M22_V08 : 32|16@1+ (1,0) [0|65535] "mV" LOGGER
 SG_ BMU_M22_VAge2 : 48|16@1+ (1,0) [0|65535] "ms" LOGGER

BO_ 2284093795 BMU_TransmitVoltage_N_22_P_3: 8 BMU
 SG_ BMU_M22_V09 : 0|16@1+ (1,0) [0|65535] "mV" LOGGER
 SG_ BMU_M22_V10 : 16|16@1+ (1,0) [0|65535] "mV" LOGGER
 SG_ BMU_M22_V11 : 32|16@1+ (1,0) [0|65535] "mV" LOGGER
 SG_ BMU_M22_VAge3 : 48|16@1+ (1,0) [0|65535] "ms" LOGGER

BO_ 2284093808 BMU_TransmitVoltage_N_23_P_0: 8 BMU
 SG_ BMU_M23_V00 : 0|16@1+ (1,0) [0|65535] "mV" LOGGER
 SG_ BMU_M23_V01 : 16|16@1+ (1,0) [0|65535] "mV" LOGGER
 SG_ BMU_M23_V02 : 32|16@1+ (1,0) [0|65535] "mV" LOGGER
 SG_ BMU_M23_VAge0 : 48|16@1+ (1,0) [0|65535] "ms" LOGGER

BO_ 2284093809 BMU_TransmitVoltage_N_23_P_1: 8 BMU
 SG_ BMU_M23_V03 : 0|16@1+ (1,0) [0|65535] "mV" LOGGER
 SG_ BMU_M23_V04 : 16|16@1+ (1,0) [0|65535] "mV" LOGGER
 SG_ BMU_M23_V05 : 32|16@1+ (1,0) [0|65535] "mV" LOGGER
 SG_ BMU_M23_VAge1 : 48|16@1+ (1,0) [0|65535] "ms" LOGGER

BO_ 2284093810 BMU_TransmitVoltage_N_23_P_2: 8 BMU
 SG_ BMU_M23_V06 : 0|16@1+ (1,0) [0|65535] "mV" LOGGER
 SG_ BMU_M23_V07 : 16|16@1+ (1,0) [0|65535] "mV" LOGGER
 SG_ BMU_M23_V08 : 32|16@1+ (1,0) [0|65535] "mV" LOGGER
 SG_ BMU_M23_VAge2 : 48|16@1+ (1,0) [0|65535] "ms" LOGGER

BO_ 2284093811 BMU_TransmitVoltage_N_23_P_3: 8 BMU
 SG_ BMU_M23_V09 : 0|16@1+ (1,0) [0|65535] "mV" LOGGER
 SG_ BMU_M23_V10 : 16|16@1+ (1,0) [0|65535] "mV" LOGGER
 SG_ BMU_M23_V11 : 32|16@1+ (1,0) [0|65535] "mV" LOGGER
 SG_ BMU_M23_VAge3 : 48|16@1+ (1,0) [0|65535] "ms" LOGGER

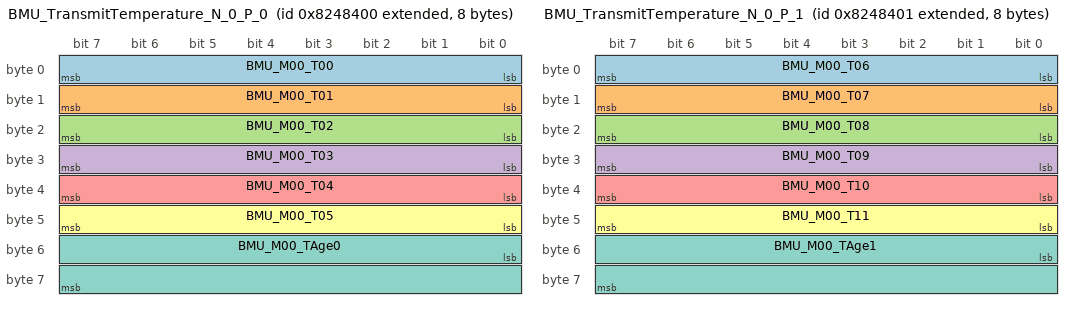
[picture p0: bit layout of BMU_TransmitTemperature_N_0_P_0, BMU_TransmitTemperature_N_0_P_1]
BO_ 2284094464 BMU_TransmitTemperature_N_0_P_0: 8 BMU
 SG_ BMU_M00_T00 : 0|8@1+ (1,0) [0|255] "degC" ECU,LOGGER
 SG_ BMU_M00_T01 : 8|8@1+ (1,0) [0|255] "degC" ECU,LOGGER
 SG_ BMU_M00_T02 : 16|8@1+ (1,0) [0|255] "degC" ECU,LOGGER
 SG_ BMU_M00_T03 : 24|8@1+ (1,0) [0|255] "degC" ECU,LOGGER
 SG_ BMU_M00_T04 : 32|8@1+ (1,0) [0|255] "degC" ECU,LOGGER
 SG_ BMU_M00_T05 : 40|8@1+ (1,0) [0|255] "degC" ECU,LOGGER
 SG_ BMU_M00_TAge0 : 48|16@1+ (1,0) [0|65535] "ms" ECU,LOGGER

BO_ 2284094465 BMU_TransmitTemperature_N_0_P_1: 8 BMU
 SG_ BMU_M00_T06 : 0|8@1+ (1,0) [0|255] "degC" ECU,LOGGER
 SG_ BMU_M00_T07 : 8|8@1+ (1,0) [0|255] "degC" ECU,LOGGER
 SG_ BMU_M00_T08 : 16|8@1+ (1,0) [0|255] "degC" ECU,LOGGER
 SG_ BMU_M00_T09 : 24|8@1+ (1,0) [0|255] "degC" ECU,LOGGER
 SG_ BMU_M00_T10 : 32|8@1+ (1,0) [0|255] "degC" ECU,LOGGER
 SG_ BMU_M00_T11 : 40|8@1+ (1,0) [0|255] "degC" ECU,LOGGER
 SG_ BMU_M00_TAge1 : 48|16@1+ (1,0) [0|65535] "ms" ECU,LOGGER

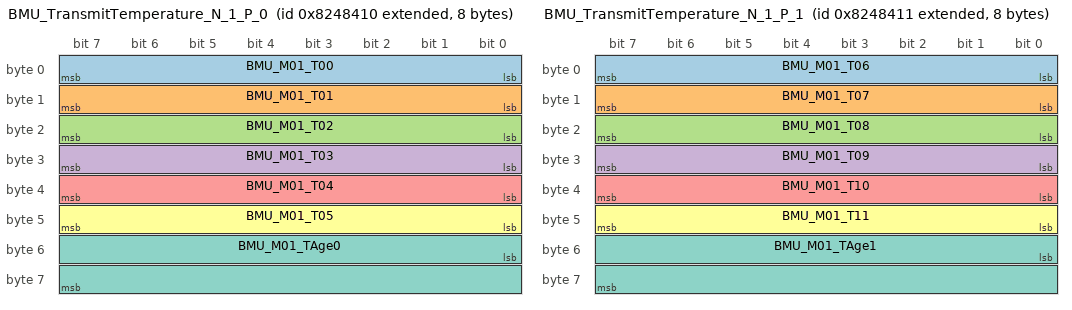
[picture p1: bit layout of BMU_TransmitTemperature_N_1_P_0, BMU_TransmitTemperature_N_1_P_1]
BO_ 2284094480 BMU_TransmitTemperature_N_1_P_0: 8 BMU
 SG_ BMU_M01_T00 : 0|8@1+ (1,0) [0|255] "degC" ECU,LOGGER
 SG_ BMU_M01_T01 : 8|8@1+ (1,0) [0|255] "degC" ECU,LOGGER
 SG_ BMU_M01_T02 : 16|8@1+ (1,0) [0|255] "degC" ECU,LOGGER
 SG_ BMU_M01_T03 : 24|8@1+ (1,0) [0|255] "degC" ECU,LOGGER
 SG_ BMU_M01_T04 : 32|8@1+ (1,0) [0|255] "degC" ECU,LOGGER
 SG_ BMU_M01_T05 : 40|8@1+ (1,0) [0|255] "degC" ECU,LOGGER
 SG_ BMU_M01_TAge0 : 48|16@1+ (1,0) [0|65535] "ms" ECU,LOGGER

BO_ 2284094481 BMU_TransmitTemperature_N_1_P_1: 8 BMU
 SG_ BMU_M01_T06 : 0|8@1+ (1,0) [0|255] "degC" ECU,LOGGER
 SG_ BMU_M01_T07 : 8|8@1+ (1,0) [0|255] "degC" ECU,LOGGER
 SG_ BMU_M01_T08 : 16|8@1+ (1,0) [0|255] "degC" ECU,LOGGER
 SG_ BMU_M01_T09 : 24|8@1+ (1,0) [0|255] "degC" ECU,LOGGER
 SG_ BMU_M01_T10 : 32|8@1+ (1,0) [0|255] "degC" ECU,LOGGER
 SG_ BMU_M01_T11 : 40|8@1+ (1,0) [0|255] "degC" ECU,LOGGER
 SG_ BMU_M01_TAge1 : 48|16@1+ (1,0) [0|65535] "ms" ECU,LOGGER

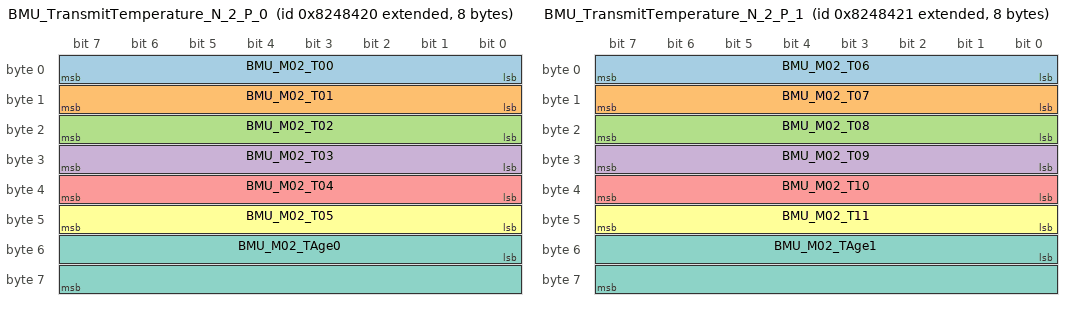
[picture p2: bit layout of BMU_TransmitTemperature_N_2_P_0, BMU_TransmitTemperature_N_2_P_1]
BO_ 2284094496 BMU_TransmitTemperature_N_2_P_0: 8 BMU
 SG_ BMU_M02_T00 : 0|8@1+ (1,0) [0|255] "degC" ECU,LOGGER
 SG_ BMU_M02_T01 : 8|8@1+ (1,0) [0|255] "degC" ECU,LOGGER
 SG_ BMU_M02_T02 : 16|8@1+ (1,0) [0|255] "degC" ECU,LOGGER
 SG_ BMU_M02_T03 : 24|8@1+ (1,0) [0|255] "degC" ECU,LOGGER
 SG_ BMU_M02_T04 : 32|8@1+ (1,0) [0|255] "degC" ECU,LOGGER
 SG_ BMU_M02_T05 : 40|8@1+ (1,0) [0|255] "degC" ECU,LOGGER
 SG_ BMU_M02_TAge0 : 48|16@1+ (1,0) [0|65535] "ms" ECU,LOGGER

BO_ 2284094497 BMU_TransmitTemperature_N_2_P_1: 8 BMU
 SG_ BMU_M02_T06 : 0|8@1+ (1,0) [0|255] "degC" ECU,LOGGER
 SG_ BMU_M02_T07 : 8|8@1+ (1,0) [0|255] "degC" ECU,LOGGER
 SG_ BMU_M02_T08 : 16|8@1+ (1,0) [0|255] "degC" ECU,LOGGER
 SG_ BMU_M02_T09 : 24|8@1+ (1,0) [0|255] "degC" ECU,LOGGER
 SG_ BMU_M02_T10 : 32|8@1+ (1,0) [0|255] "degC" ECU,LOGGER
 SG_ BMU_M02_T11 : 40|8@1+ (1,0) [0|255] "degC" ECU,LOGGER
 SG_ BMU_M02_TAge1 : 48|16@1+ (1,0) [0|65535] "ms" ECU,LOGGER

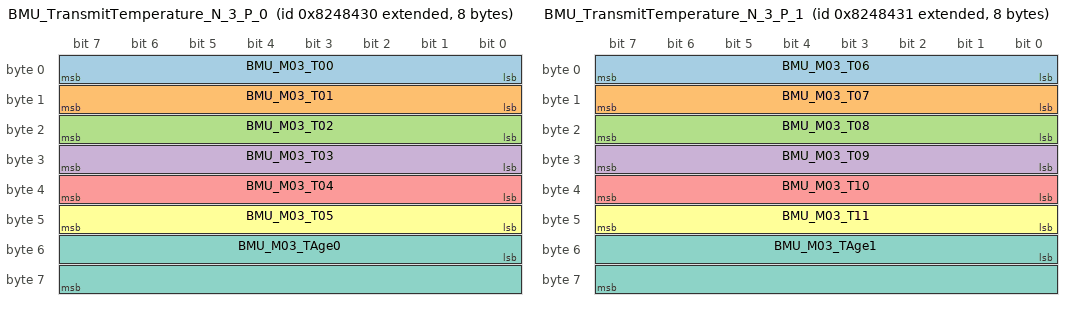
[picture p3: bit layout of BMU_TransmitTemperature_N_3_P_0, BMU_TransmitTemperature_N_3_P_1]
BO_ 2284094512 BMU_TransmitTemperature_N_3_P_0: 8 BMU
 SG_ BMU_M03_T00 : 0|8@1+ (1,0) [0|255] "degC" ECU,LOGGER
 SG_ BMU_M03_T01 : 8|8@1+ (1,0) [0|255] "degC" ECU,LOGGER
 SG_ BMU_M03_T02 : 16|8@1+ (1,0) [0|255] "degC" ECU,LOGGER
 SG_ BMU_M03_T03 : 24|8@1+ (1,0) [0|255] "degC" ECU,LOGGER
 SG_ BMU_M03_T04 : 32|8@1+ (1,0) [0|255] "degC" ECU,LOGGER
 SG_ BMU_M03_T05 : 40|8@1+ (1,0) [0|255] "degC" ECU,LOGGER
 SG_ BMU_M03_TAge0 : 48|16@1+ (1,0) [0|65535] "ms" ECU,LOGGER

BO_ 2284094513 BMU_TransmitTemperature_N_3_P_1: 8 BMU
 SG_ BMU_M03_T06 : 0|8@1+ (1,0) [0|255] "degC" ECU,LOGGER
 SG_ BMU_M03_T07 : 8|8@1+ (1,0) [0|255] "degC" ECU,LOGGER
 SG_ BMU_M03_T08 : 16|8@1+ (1,0) [0|255] "degC" ECU,LOGGER
 SG_ BMU_M03_T09 : 24|8@1+ (1,0) [0|255] "degC" ECU,LOGGER
 SG_ BMU_M03_T10 : 32|8@1+ (1,0) [0|255] "degC" ECU,LOGGER
 SG_ BMU_M03_T11 : 40|8@1+ (1,0) [0|255] "degC" ECU,LOGGER
 SG_ BMU_M03_TAge1 : 48|16@1+ (1,0) [0|65535] "ms" ECU,LOGGER

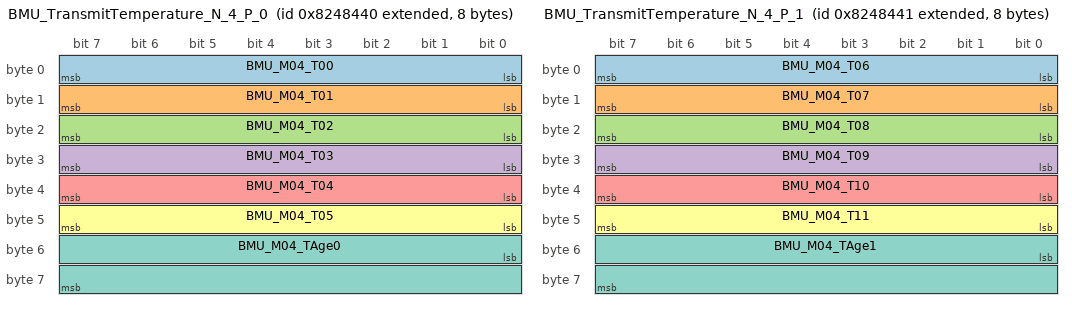
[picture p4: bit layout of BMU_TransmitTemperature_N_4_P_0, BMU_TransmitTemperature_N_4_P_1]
BO_ 2284094528 BMU_TransmitTemperature_N_4_P_0: 8 BMU
 SG_ BMU_M04_T00 : 0|8@1+ (1,0) [0|255] "degC" ECU,LOGGER
 SG_ BMU_M04_T01 : 8|8@1+ (1,0) [0|255] "degC" ECU,LOGGER
 SG_ BMU_M04_T02 : 16|8@1+ (1,0) [0|255] "degC" ECU,LOGGER
 SG_ BMU_M04_T03 : 24|8@1+ (1,0) [0|255] "degC" ECU,LOGGER
 SG_ BMU_M04_T04 : 32|8@1+ (1,0) [0|255] "degC" ECU,LOGGER
 SG_ BMU_M04_T05 : 40|8@1+ (1,0) [0|255] "degC" ECU,LOGGER
 SG_ BMU_M04_TAge0 : 48|16@1+ (1,0) [0|65535] "ms" ECU,LOGGER

BO_ 2284094529 BMU_TransmitTemperature_N_4_P_1: 8 BMU
 SG_ BMU_M04_T06 : 0|8@1+ (1,0) [0|255] "degC" ECU,LOGGER
 SG_ BMU_M04_T07 : 8|8@1+ (1,0) [0|255] "degC" ECU,LOGGER
 SG_ BMU_M04_T08 : 16|8@1+ (1,0) [0|255] "degC" ECU,LOGGER
 SG_ BMU_M04_T09 : 24|8@1+ (1,0) [0|255] "degC" ECU,LOGGER
 SG_ BMU_M04_T10 : 32|8@1+ (1,0) [0|255] "degC" ECU,LOGGER
 SG_ BMU_M04_T11 : 40|8@1+ (1,0) [0|255] "degC" ECU,LOGGER
 SG_ BMU_M04_TAge1 : 48|16@1+ (1,0) [0|65535] "ms" ECU,LOGGER

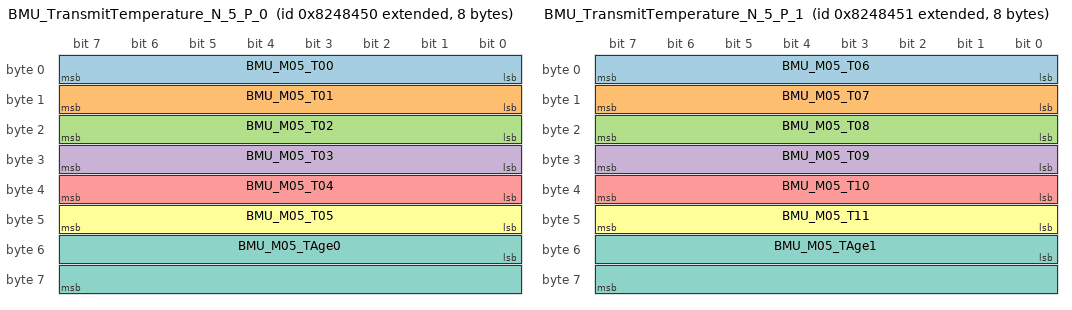
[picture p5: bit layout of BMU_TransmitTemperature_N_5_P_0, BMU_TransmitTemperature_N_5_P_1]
BO_ 2284094544 BMU_TransmitTemperature_N_5_P_0: 8 BMU
 SG_ BMU_M05_T00 : 0|8@1+ (1,0) [0|255] "degC" ECU,LOGGER
 SG_ BMU_M05_T01 : 8|8@1+ (1,0) [0|255] "degC" ECU,LOGGER
 SG_ BMU_M05_T02 : 16|8@1+ (1,0) [0|255] "degC" ECU,LOGGER
 SG_ BMU_M05_T03 : 24|8@1+ (1,0) [0|255] "degC" ECU,LOGGER
 SG_ BMU_M05_T04 : 32|8@1+ (1,0) [0|255] "degC" ECU,LOGGER
 SG_ BMU_M05_T05 : 40|8@1+ (1,0) [0|255] "degC" ECU,LOGGER
 SG_ BMU_M05_TAge0 : 48|16@1+ (1,0) [0|65535] "ms" ECU,LOGGER

BO_ 2284094545 BMU_TransmitTemperature_N_5_P_1: 8 BMU
 SG_ BMU_M05_T06 : 0|8@1+ (1,0) [0|255] "degC" ECU,LOGGER
 SG_ BMU_M05_T07 : 8|8@1+ (1,0) [0|255] "degC" ECU,LOGGER
 SG_ BMU_M05_T08 : 16|8@1+ (1,0) [0|255] "degC" ECU,LOGGER
 SG_ BMU_M05_T09 : 24|8@1+ (1,0) [0|255] "degC" ECU,LOGGER
 SG_ BMU_M05_T10 : 32|8@1+ (1,0) [0|255] "degC" ECU,LOGGER
 SG_ BMU_M05_T11 : 40|8@1+ (1,0) [0|255] "degC" ECU,LOGGER
 SG_ BMU_M05_TAge1 : 48|16@1+ (1,0) [0|65535] "ms" ECU,LOGGER

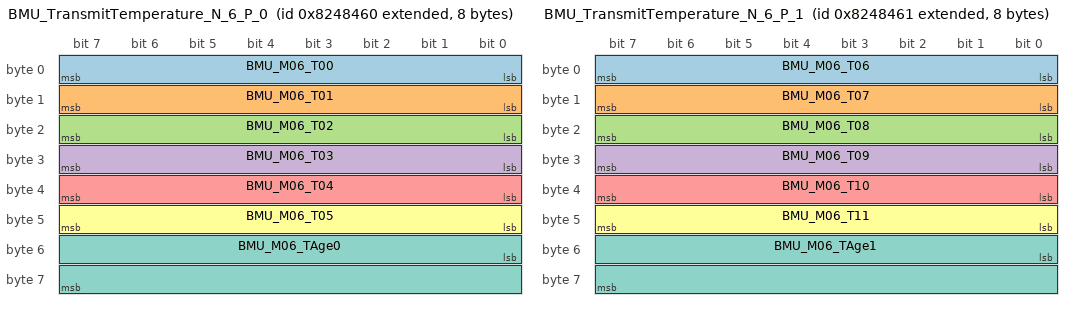
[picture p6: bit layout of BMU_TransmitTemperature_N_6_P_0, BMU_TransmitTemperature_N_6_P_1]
BO_ 2284094560 BMU_TransmitTemperature_N_6_P_0: 8 BMU
 SG_ BMU_M06_T00 : 0|8@1+ (1,0) [0|255] "degC" ECU,LOGGER
 SG_ BMU_M06_T01 : 8|8@1+ (1,0) [0|255] "degC" ECU,LOGGER
 SG_ BMU_M06_T02 : 16|8@1+ (1,0) [0|255] "degC" ECU,LOGGER
 SG_ BMU_M06_T03 : 24|8@1+ (1,0) [0|255] "degC" ECU,LOGGER
 SG_ BMU_M06_T04 : 32|8@1+ (1,0) [0|255] "degC" ECU,LOGGER
 SG_ BMU_M06_T05 : 40|8@1+ (1,0) [0|255] "degC" ECU,LOGGER
 SG_ BMU_M06_TAge0 : 48|16@1+ (1,0) [0|65535] "ms" ECU,LOGGER

BO_ 2284094561 BMU_TransmitTemperature_N_6_P_1: 8 BMU
 SG_ BMU_M06_T06 : 0|8@1+ (1,0) [0|255] "degC" ECU,LOGGER
 SG_ BMU_M06_T07 : 8|8@1+ (1,0) [0|255] "degC" ECU,LOGGER
 SG_ BMU_M06_T08 : 16|8@1+ (1,0) [0|255] "degC" ECU,LOGGER
 SG_ BMU_M06_T09 : 24|8@1+ (1,0) [0|255] "degC" ECU,LOGGER
 SG_ BMU_M06_T10 : 32|8@1+ (1,0) [0|255] "degC" ECU,LOGGER
 SG_ BMU_M06_T11 : 40|8@1+ (1,0) [0|255] "degC" ECU,LOGGER
 SG_ BMU_M06_TAge1 : 48|16@1+ (1,0) [0|65535] "ms" ECU,LOGGER

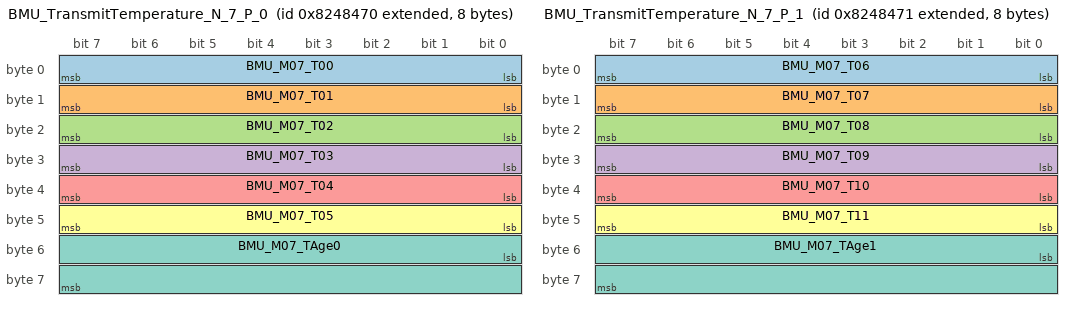
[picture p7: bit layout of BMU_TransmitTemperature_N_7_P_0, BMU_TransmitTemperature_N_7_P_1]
BO_ 2284094576 BMU_TransmitTemperature_N_7_P_0: 8 BMU
 SG_ BMU_M07_T00 : 0|8@1+ (1,0) [0|255] "degC" ECU,LOGGER
 SG_ BMU_M07_T01 : 8|8@1+ (1,0) [0|255] "degC" ECU,LOGGER
 SG_ BMU_M07_T02 : 16|8@1+ (1,0) [0|255] "degC" ECU,LOGGER
 SG_ BMU_M07_T03 : 24|8@1+ (1,0) [0|255] "degC" ECU,LOGGER
 SG_ BMU_M07_T04 : 32|8@1+ (1,0) [0|255] "degC" ECU,LOGGER
 SG_ BMU_M07_T05 : 40|8@1+ (1,0) [0|255] "degC" ECU,LOGGER
 SG_ BMU_M07_TAge0 : 48|16@1+ (1,0) [0|65535] "ms" ECU,LOGGER

BO_ 2284094577 BMU_TransmitTemperature_N_7_P_1: 8 BMU
 SG_ BMU_M07_T06 : 0|8@1+ (1,0) [0|255] "degC" ECU,LOGGER
 SG_ BMU_M07_T07 : 8|8@1+ (1,0) [0|255] "degC" ECU,LOGGER
 SG_ BMU_M07_T08 : 16|8@1+ (1,0) [0|255] "degC" ECU,LOGGER
 SG_ BMU_M07_T09 : 24|8@1+ (1,0) [0|255] "degC" ECU,LOGGER
 SG_ BMU_M07_T10 : 32|8@1+ (1,0) [0|255] "degC" ECU,LOGGER
 SG_ BMU_M07_T11 : 40|8@1+ (1,0) [0|255] "degC" ECU,LOGGER
 SG_ BMU_M07_TAge1 : 48|16@1+ (1,0) [0|65535] "ms" ECU,LOGGER

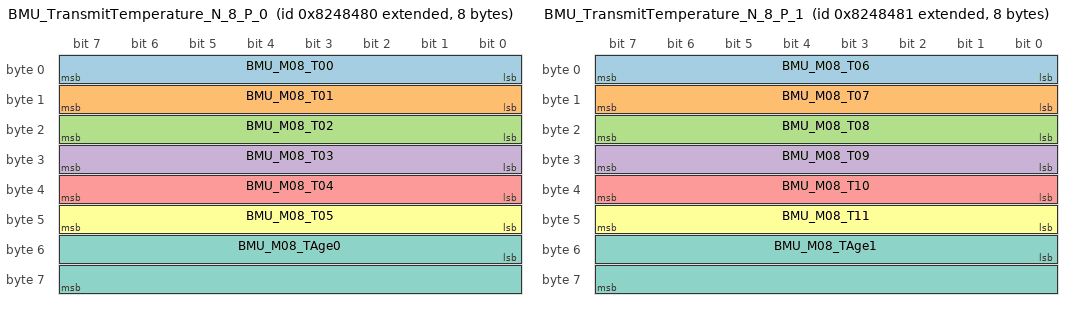
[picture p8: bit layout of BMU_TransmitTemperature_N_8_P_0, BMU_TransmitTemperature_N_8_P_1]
BO_ 2284094592 BMU_TransmitTemperature_N_8_P_0: 8 BMU
 SG_ BMU_M08_T00 : 0|8@1+ (1,0) [0|255] "degC" ECU,LOGGER
 SG_ BMU_M08_T01 : 8|8@1+ (1,0) [0|255] "degC" ECU,LOGGER
 SG_ BMU_M08_T02 : 16|8@1+ (1,0) [0|255] "degC" ECU,LOGGER
 SG_ BMU_M08_T03 : 24|8@1+ (1,0) [0|255] "degC" ECU,LOGGER
 SG_ BMU_M08_T04 : 32|8@1+ (1,0) [0|255] "degC" ECU,LOGGER
 SG_ BMU_M08_T05 : 40|8@1+ (1,0) [0|255] "degC" ECU,LOGGER
 SG_ BMU_M08_TAge0 : 48|16@1+ (1,0) [0|65535] "ms" ECU,LOGGER

BO_ 2284094593 BMU_TransmitTemperature_N_8_P_1: 8 BMU
 SG_ BMU_M08_T06 : 0|8@1+ (1,0) [0|255] "degC" ECU,LOGGER
 SG_ BMU_M08_T07 : 8|8@1+ (1,0) [0|255] "degC" ECU,LOGGER
 SG_ BMU_M08_T08 : 16|8@1+ (1,0) [0|255] "degC" ECU,LOGGER
 SG_ BMU_M08_T09 : 24|8@1+ (1,0) [0|255] "degC" ECU,LOGGER
 SG_ BMU_M08_T10 : 32|8@1+ (1,0) [0|255] "degC" ECU,LOGGER
 SG_ BMU_M08_T11 : 40|8@1+ (1,0) [0|255] "degC" ECU,LOGGER
 SG_ BMU_M08_TAge1 : 48|16@1+ (1,0) [0|65535] "ms" ECU,LOGGER

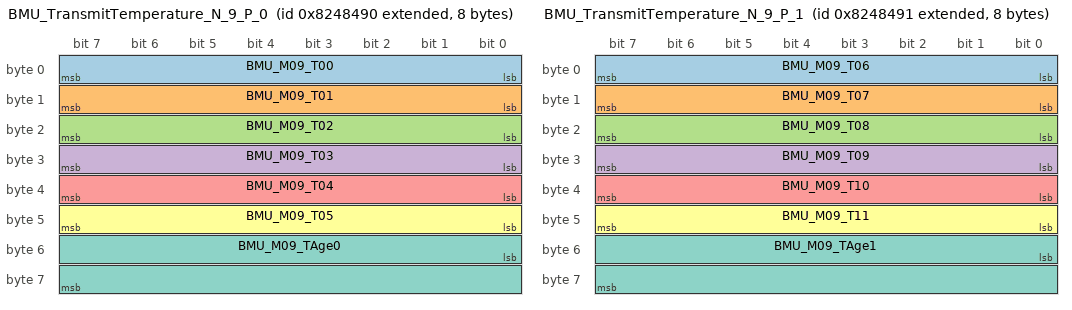
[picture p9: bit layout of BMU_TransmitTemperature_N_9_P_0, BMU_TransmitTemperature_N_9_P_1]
BO_ 2284094608 BMU_TransmitTemperature_N_9_P_0: 8 BMU
 SG_ BMU_M09_T00 : 0|8@1+ (1,0) [0|255] "degC" ECU,LOGGER
 SG_ BMU_M09_T01 : 8|8@1+ (1,0) [0|255] "degC" ECU,LOGGER
 SG_ BMU_M09_T02 : 16|8@1+ (1,0) [0|255] "degC" ECU,LOGGER
 SG_ BMU_M09_T03 : 24|8@1+ (1,0) [0|255] "degC" ECU,LOGGER
 SG_ BMU_M09_T04 : 32|8@1+ (1,0) [0|255] "degC" ECU,LOGGER
 SG_ BMU_M09_T05 : 40|8@1+ (1,0) [0|255] "degC" ECU,LOGGER
 SG_ BMU_M09_TAge0 : 48|16@1+ (1,0) [0|65535] "ms" ECU,LOGGER

BO_ 2284094609 BMU_TransmitTemperature_N_9_P_1: 8 BMU
 SG_ BMU_M09_T06 : 0|8@1+ (1,0) [0|255] "degC" ECU,LOGGER
 SG_ BMU_M09_T07 : 8|8@1+ (1,0) [0|255] "degC" ECU,LOGGER
 SG_ BMU_M09_T08 : 16|8@1+ (1,0) [0|255] "degC" ECU,LOGGER
 SG_ BMU_M09_T09 : 24|8@1+ (1,0) [0|255] "degC" ECU,LOGGER
 SG_ BMU_M09_T10 : 32|8@1+ (1,0) [0|255] "degC" ECU,LOGGER
 SG_ BMU_M09_T11 : 40|8@1+ (1,0) [0|255] "degC" ECU,LOGGER
 SG_ BMU_M09_TAge1 : 48|16@1+ (1,0) [0|65535] "ms" ECU,LOGGER

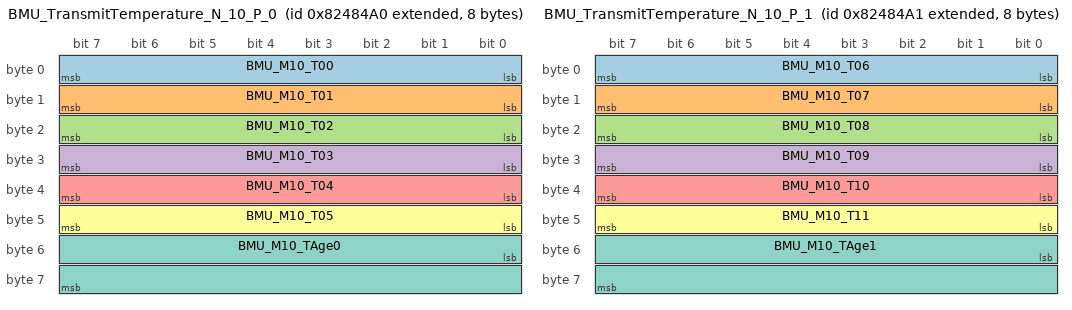
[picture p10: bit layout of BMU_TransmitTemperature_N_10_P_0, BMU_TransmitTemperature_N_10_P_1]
BO_ 2284094624 BMU_TransmitTemperature_N_10_P_0: 8 BMU
 SG_ BMU_M10_T00 : 0|8@1+ (1,0) [0|255] "degC" ECU,LOGGER
 SG_ BMU_M10_T01 : 8|8@1+ (1,0) [0|255] "degC" ECU,LOGGER
 SG_ BMU_M10_T02 : 16|8@1+ (1,0) [0|255] "degC" ECU,LOGGER
 SG_ BMU_M10_T03 : 24|8@1+ (1,0) [0|255] "degC" ECU,LOGGER
 SG_ BMU_M10_T04 : 32|8@1+ (1,0) [0|255] "degC" ECU,LOGGER
 SG_ BMU_M10_T05 : 40|8@1+ (1,0) [0|255] "degC" ECU,LOGGER
 SG_ BMU_M10_TAge0 : 48|16@1+ (1,0) [0|65535] "ms" ECU,LOGGER

BO_ 2284094625 BMU_TransmitTemperature_N_10_P_1: 8 BMU
 SG_ BMU_M10_T06 : 0|8@1+ (1,0) [0|255] "degC" ECU,LOGGER
 SG_ BMU_M10_T07 : 8|8@1+ (1,0) [0|255] "degC" ECU,LOGGER
 SG_ BMU_M10_T08 : 16|8@1+ (1,0) [0|255] "degC" ECU,LOGGER
 SG_ BMU_M10_T09 : 24|8@1+ (1,0) [0|255] "degC" ECU,LOGGER
 SG_ BMU_M10_T10 : 32|8@1+ (1,0) [0|255] "degC" ECU,LOGGER
 SG_ BMU_M10_T11 : 40|8@1+ (1,0) [0|255] "degC" ECU,LOGGER
 SG_ BMU_M10_TAge1 : 48|16@1+ (1,0) [0|65535] "ms" ECU,LOGGER

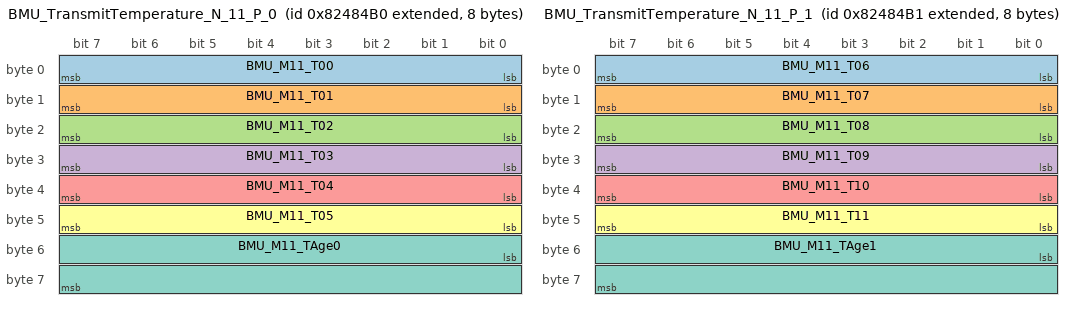
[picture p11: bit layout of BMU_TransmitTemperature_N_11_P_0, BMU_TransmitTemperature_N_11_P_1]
BO_ 2284094640 BMU_TransmitTemperature_N_11_P_0: 8 BMU
 SG_ BMU_M11_T00 : 0|8@1+ (1,0) [0|255] "degC" ECU,LOGGER
 SG_ BMU_M11_T01 : 8|8@1+ (1,0) [0|255] "degC" ECU,LOGGER
 SG_ BMU_M11_T02 : 16|8@1+ (1,0) [0|255] "degC" ECU,LOGGER
 SG_ BMU_M11_T03 : 24|8@1+ (1,0) [0|255] "degC" ECU,LOGGER
 SG_ BMU_M11_T04 : 32|8@1+ (1,0) [0|255] "degC" ECU,LOGGER
 SG_ BMU_M11_T05 : 40|8@1+ (1,0) [0|255] "degC" ECU,LOGGER
 SG_ BMU_M11_TAge0 : 48|16@1+ (1,0) [0|65535] "ms" ECU,LOGGER

BO_ 2284094641 BMU_TransmitTemperature_N_11_P_1: 8 BMU
 SG_ BMU_M11_T06 : 0|8@1+ (1,0) [0|255] "degC" ECU,LOGGER
 SG_ BMU_M11_T07 : 8|8@1+ (1,0) [0|255] "degC" ECU,LOGGER
 SG_ BMU_M11_T08 : 16|8@1+ (1,0) [0|255] "degC" ECU,LOGGER
 SG_ BMU_M11_T09 : 24|8@1+ (1,0) [0|255] "degC" ECU,LOGGER
 SG_ BMU_M11_T10 : 32|8@1+ (1,0) [0|255] "degC" ECU,LOGGER
 SG_ BMU_M11_T11 : 40|8@1+ (1,0) [0|255] "degC" ECU,LOGGER
 SG_ BMU_M11_TAge1 : 48|16@1+ (1,0) [0|65535] "ms" ECU,LOGGER

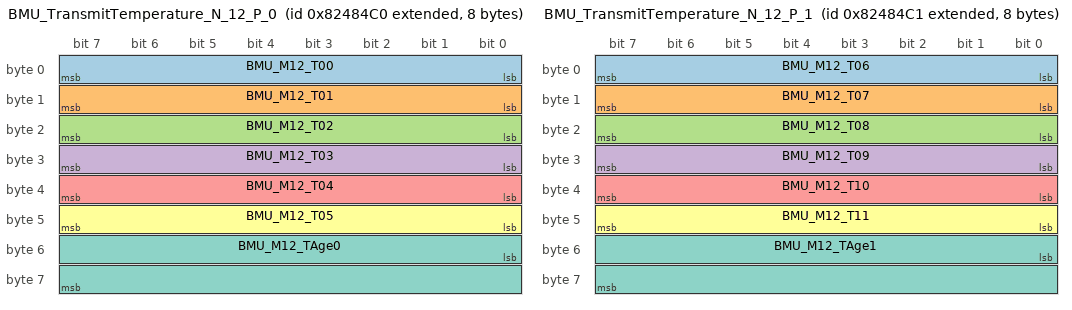
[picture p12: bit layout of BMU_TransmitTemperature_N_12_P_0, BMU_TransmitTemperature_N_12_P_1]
BO_ 2284094656 BMU_TransmitTemperature_N_12_P_0: 8 BMU
 SG_ BMU_M12_T00 : 0|8@1+ (1,0) [0|255] "degC" ECU,LOGGER
 SG_ BMU_M12_T01 : 8|8@1+ (1,0) [0|255] "degC" ECU,LOGGER
 SG_ BMU_M12_T02 : 16|8@1+ (1,0) [0|255] "degC" ECU,LOGGER
 SG_ BMU_M12_T03 : 24|8@1+ (1,0) [0|255] "degC" ECU,LOGGER
 SG_ BMU_M12_T04 : 32|8@1+ (1,0) [0|255] "degC" ECU,LOGGER
 SG_ BMU_M12_T05 : 40|8@1+ (1,0) [0|255] "degC" ECU,LOGGER
 SG_ BMU_M12_TAge0 : 48|16@1+ (1,0) [0|65535] "ms" ECU,LOGGER

BO_ 2284094657 BMU_TransmitTemperature_N_12_P_1: 8 BMU
 SG_ BMU_M12_T06 : 0|8@1+ (1,0) [0|255] "degC" ECU,LOGGER
 SG_ BMU_M12_T07 : 8|8@1+ (1,0) [0|255] "degC" ECU,LOGGER
 SG_ BMU_M12_T08 : 16|8@1+ (1,0) [0|255] "degC" ECU,LOGGER
 SG_ BMU_M12_T09 : 24|8@1+ (1,0) [0|255] "degC" ECU,LOGGER
 SG_ BMU_M12_T10 : 32|8@1+ (1,0) [0|255] "degC" ECU,LOGGER
 SG_ BMU_M12_T11 : 40|8@1+ (1,0) [0|255] "degC" ECU,LOGGER
 SG_ BMU_M12_TAge1 : 48|16@1+ (1,0) [0|65535] "ms" ECU,LOGGER

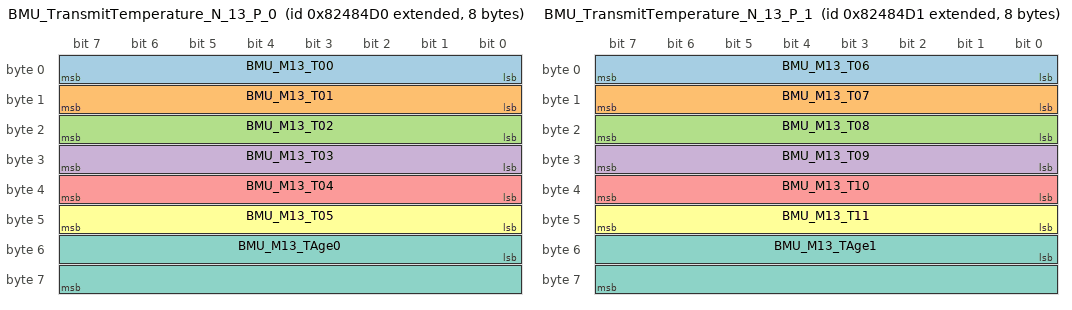
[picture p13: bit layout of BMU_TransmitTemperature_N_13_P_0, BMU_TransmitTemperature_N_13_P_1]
BO_ 2284094672 BMU_TransmitTemperature_N_13_P_0: 8 BMU
 SG_ BMU_M13_T00 : 0|8@1+ (1,0) [0|255] "degC" ECU,LOGGER
 SG_ BMU_M13_T01 : 8|8@1+ (1,0) [0|255] "degC" ECU,LOGGER
 SG_ BMU_M13_T02 : 16|8@1+ (1,0) [0|255] "degC" ECU,LOGGER
 SG_ BMU_M13_T03 : 24|8@1+ (1,0) [0|255] "degC" ECU,LOGGER
 SG_ BMU_M13_T04 : 32|8@1+ (1,0) [0|255] "degC" ECU,LOGGER
 SG_ BMU_M13_T05 : 40|8@1+ (1,0) [0|255] "degC" ECU,LOGGER
 SG_ BMU_M13_TAge0 : 48|16@1+ (1,0) [0|65535] "ms" ECU,LOGGER

BO_ 2284094673 BMU_TransmitTemperature_N_13_P_1: 8 BMU
 SG_ BMU_M13_T06 : 0|8@1+ (1,0) [0|255] "degC" ECU,LOGGER
 SG_ BMU_M13_T07 : 8|8@1+ (1,0) [0|255] "degC" ECU,LOGGER
 SG_ BMU_M13_T08 : 16|8@1+ (1,0) [0|255] "degC" ECU,LOGGER
 SG_ BMU_M13_T09 : 24|8@1+ (1,0) [0|255] "degC" ECU,LOGGER
 SG_ BMU_M13_T10 : 32|8@1+ (1,0) [0|255] "degC" ECU,LOGGER
 SG_ BMU_M13_T11 : 40|8@1+ (1,0) [0|255] "degC" ECU,LOGGER
 SG_ BMU_M13_TAge1 : 48|16@1+ (1,0) [0|65535] "ms" ECU,LOGGER

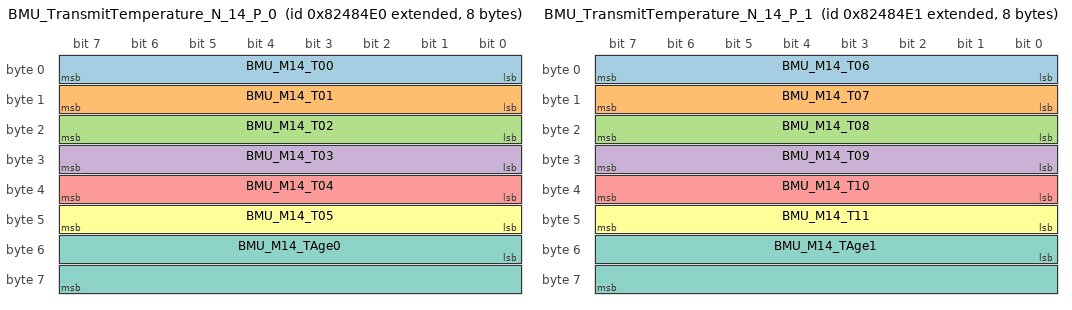
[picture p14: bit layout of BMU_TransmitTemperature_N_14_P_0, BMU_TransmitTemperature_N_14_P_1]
BO_ 2284094688 BMU_TransmitTemperature_N_14_P_0: 8 BMU
 SG_ BMU_M14_T00 : 0|8@1+ (1,0) [0|255] "degC" ECU,LOGGER
 SG_ BMU_M14_T01 : 8|8@1+ (1,0) [0|255] "degC" ECU,LOGGER
 SG_ BMU_M14_T02 : 16|8@1+ (1,0) [0|255] "degC" ECU,LOGGER
 SG_ BMU_M14_T03 : 24|8@1+ (1,0) [0|255] "degC" ECU,LOGGER
 SG_ BMU_M14_T04 : 32|8@1+ (1,0) [0|255] "degC" ECU,LOGGER
 SG_ BMU_M14_T05 : 40|8@1+ (1,0) [0|255] "degC" ECU,LOGGER
 SG_ BMU_M14_TAge0 : 48|16@1+ (1,0) [0|65535] "ms" ECU,LOGGER

BO_ 2284094689 BMU_TransmitTemperature_N_14_P_1: 8 BMU
 SG_ BMU_M14_T06 : 0|8@1+ (1,0) [0|255] "degC" ECU,LOGGER
 SG_ BMU_M14_T07 : 8|8@1+ (1,0) [0|255] "degC" ECU,LOGGER
 SG_ BMU_M14_T08 : 16|8@1+ (1,0) [0|255] "degC" ECU,LOGGER
 SG_ BMU_M14_T09 : 24|8@1+ (1,0) [0|255] "degC" ECU,LOGGER
 SG_ BMU_M14_T10 : 32|8@1+ (1,0) [0|255] "degC" ECU,LOGGER
 SG_ BMU_M14_T11 : 40|8@1+ (1,0) [0|255] "degC" ECU,LOGGER
 SG_ BMU_M14_TAge1 : 48|16@1+ (1,0) [0|65535] "ms" ECU,LOGGER

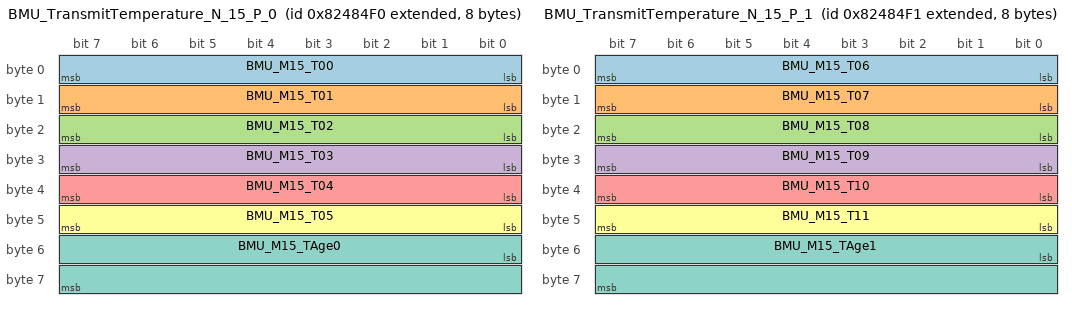
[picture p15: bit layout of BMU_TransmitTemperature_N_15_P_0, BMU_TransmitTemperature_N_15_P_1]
BO_ 2284094704 BMU_TransmitTemperature_N_15_P_0: 8 BMU
 SG_ BMU_M15_T00 : 0|8@1+ (1,0) [0|255] "degC" ECU,LOGGER
 SG_ BMU_M15_T01 : 8|8@1+ (1,0) [0|255] "degC" ECU,LOGGER
 SG_ BMU_M15_T02 : 16|8@1+ (1,0) [0|255] "degC" ECU,LOGGER
 SG_ BMU_M15_T03 : 24|8@1+ (1,0) [0|255] "degC" ECU,LOGGER
 SG_ BMU_M15_T04 : 32|8@1+ (1,0) [0|255] "degC" ECU,LOGGER
 SG_ BMU_M15_T05 : 40|8@1+ (1,0) [0|255] "degC" ECU,LOGGER
 SG_ BMU_M15_TAge0 : 48|16@1+ (1,0) [0|65535] "ms" ECU,LOGGER

BO_ 2284094705 BMU_TransmitTemperature_N_15_P_1: 8 BMU
 SG_ BMU_M15_T06 : 0|8@1+ (1,0) [0|255] "degC" ECU,LOGGER
 SG_ BMU_M15_T07 : 8|8@1+ (1,0) [0|255] "degC" ECU,LOGGER
 SG_ BMU_M15_T08 : 16|8@1+ (1,0) [0|255] "degC" ECU,LOGGER
 SG_ BMU_M15_T09 : 24|8@1+ (1,0) [0|255] "degC" ECU,LOGGER
 SG_ BMU_M15_T10 : 32|8@1+ (1,0) [0|255] "degC" ECU,LOGGER
 SG_ BMU_M15_T11 : 40|8@1+ (1,0) [0|255] "degC" ECU,LOGGER
 SG_ BMU_M15_TAge1 : 48|16@1+ (1,0) [0|65535] "ms" ECU,LOGGER

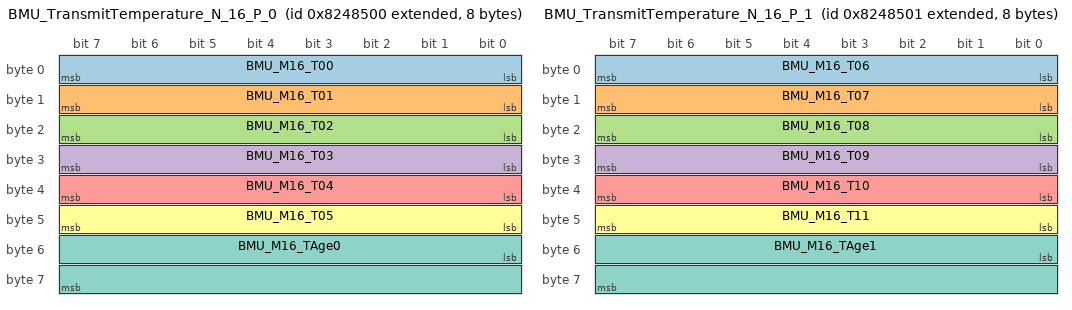
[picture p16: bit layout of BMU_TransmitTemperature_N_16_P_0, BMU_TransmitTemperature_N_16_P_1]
BO_ 2284094720 BMU_TransmitTemperature_N_16_P_0: 8 BMU
 SG_ BMU_M16_T00 : 0|8@1+ (1,0) [0|255] "degC" ECU,LOGGER
 SG_ BMU_M16_T01 : 8|8@1+ (1,0) [0|255] "degC" ECU,LOGGER
 SG_ BMU_M16_T02 : 16|8@1+ (1,0) [0|255] "degC" ECU,LOGGER
 SG_ BMU_M16_T03 : 24|8@1+ (1,0) [0|255] "degC" ECU,LOGGER
 SG_ BMU_M16_T04 : 32|8@1+ (1,0) [0|255] "degC" ECU,LOGGER
 SG_ BMU_M16_T05 : 40|8@1+ (1,0) [0|255] "degC" ECU,LOGGER
 SG_ BMU_M16_TAge0 : 48|16@1+ (1,0) [0|65535] "ms" ECU,LOGGER

BO_ 2284094721 BMU_TransmitTemperature_N_16_P_1: 8 BMU
 SG_ BMU_M16_T06 : 0|8@1+ (1,0) [0|255] "degC" ECU,LOGGER
 SG_ BMU_M16_T07 : 8|8@1+ (1,0) [0|255] "degC" ECU,LOGGER
 SG_ BMU_M16_T08 : 16|8@1+ (1,0) [0|255] "degC" ECU,LOGGER
 SG_ BMU_M16_T09 : 24|8@1+ (1,0) [0|255] "degC" ECU,LOGGER
 SG_ BMU_M16_T10 : 32|8@1+ (1,0) [0|255] "degC" ECU,LOGGER
 SG_ BMU_M16_T11 : 40|8@1+ (1,0) [0|255] "degC" ECU,LOGGER
 SG_ BMU_M16_TAge1 : 48|16@1+ (1,0) [0|65535] "ms" ECU,LOGGER

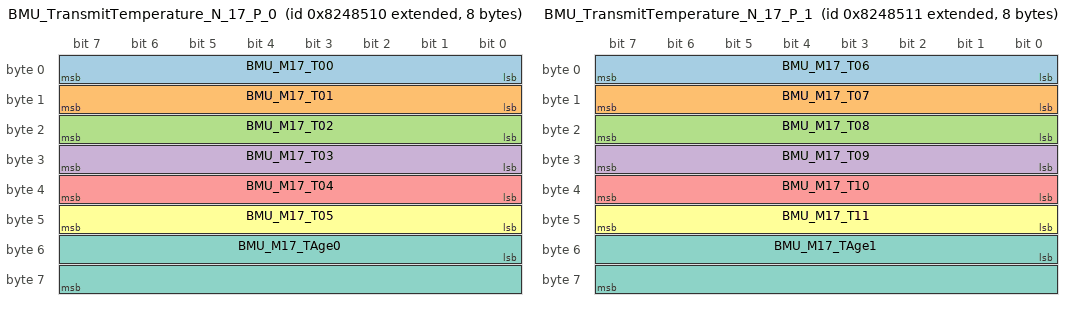
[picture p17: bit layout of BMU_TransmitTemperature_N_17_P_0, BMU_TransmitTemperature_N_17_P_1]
BO_ 2284094736 BMU_TransmitTemperature_N_17_P_0: 8 BMU
 SG_ BMU_M17_T00 : 0|8@1+ (1,0) [0|255] "degC" ECU,LOGGER
 SG_ BMU_M17_T01 : 8|8@1+ (1,0) [0|255] "degC" ECU,LOGGER
 SG_ BMU_M17_T02 : 16|8@1+ (1,0) [0|255] "degC" ECU,LOGGER
 SG_ BMU_M17_T03 : 24|8@1+ (1,0) [0|255] "degC" ECU,LOGGER
 SG_ BMU_M17_T04 : 32|8@1+ (1,0) [0|255] "degC" ECU,LOGGER
 SG_ BMU_M17_T05 : 40|8@1+ (1,0) [0|255] "degC" ECU,LOGGER
 SG_ BMU_M17_TAge0 : 48|16@1+ (1,0) [0|65535] "ms" ECU,LOGGER

BO_ 2284094737 BMU_TransmitTemperature_N_17_P_1: 8 BMU
 SG_ BMU_M17_T06 : 0|8@1+ (1,0) [0|255] "degC" ECU,LOGGER
 SG_ BMU_M17_T07 : 8|8@1+ (1,0) [0|255] "degC" ECU,LOGGER
 SG_ BMU_M17_T08 : 16|8@1+ (1,0) [0|255] "degC" ECU,LOGGER
 SG_ BMU_M17_T09 : 24|8@1+ (1,0) [0|255] "degC" ECU,LOGGER
 SG_ BMU_M17_T10 : 32|8@1+ (1,0) [0|255] "degC" ECU,LOGGER
 SG_ BMU_M17_T11 : 40|8@1+ (1,0) [0|255] "degC" ECU,LOGGER
 SG_ BMU_M17_TAge1 : 48|16@1+ (1,0) [0|65535] "ms" ECU,LOGGER

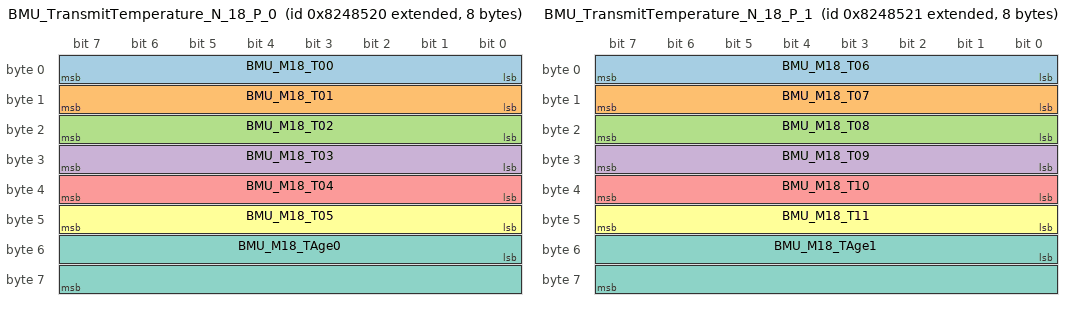
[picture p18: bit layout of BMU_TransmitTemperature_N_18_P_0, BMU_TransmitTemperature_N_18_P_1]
BO_ 2284094752 BMU_TransmitTemperature_N_18_P_0: 8 BMU
 SG_ BMU_M18_T00 : 0|8@1+ (1,0) [0|255] "degC" ECU,LOGGER
 SG_ BMU_M18_T01 : 8|8@1+ (1,0) [0|255] "degC" ECU,LOGGER
 SG_ BMU_M18_T02 : 16|8@1+ (1,0) [0|255] "degC" ECU,LOGGER
 SG_ BMU_M18_T03 : 24|8@1+ (1,0) [0|255] "degC" ECU,LOGGER
 SG_ BMU_M18_T04 : 32|8@1+ (1,0) [0|255] "degC" ECU,LOGGER
 SG_ BMU_M18_T05 : 40|8@1+ (1,0) [0|255] "degC" ECU,LOGGER
 SG_ BMU_M18_TAge0 : 48|16@1+ (1,0) [0|65535] "ms" ECU,LOGGER

BO_ 2284094753 BMU_TransmitTemperature_N_18_P_1: 8 BMU
 SG_ BMU_M18_T06 : 0|8@1+ (1,0) [0|255] "degC" ECU,LOGGER
 SG_ BMU_M18_T07 : 8|8@1+ (1,0) [0|255] "degC" ECU,LOGGER
 SG_ BMU_M18_T08 : 16|8@1+ (1,0) [0|255] "degC" ECU,LOGGER
 SG_ BMU_M18_T09 : 24|8@1+ (1,0) [0|255] "degC" ECU,LOGGER
 SG_ BMU_M18_T10 : 32|8@1+ (1,0) [0|255] "degC" ECU,LOGGER
 SG_ BMU_M18_T11 : 40|8@1+ (1,0) [0|255] "degC" ECU,LOGGER
 SG_ BMU_M18_TAge1 : 48|16@1+ (1,0) [0|65535] "ms" ECU,LOGGER

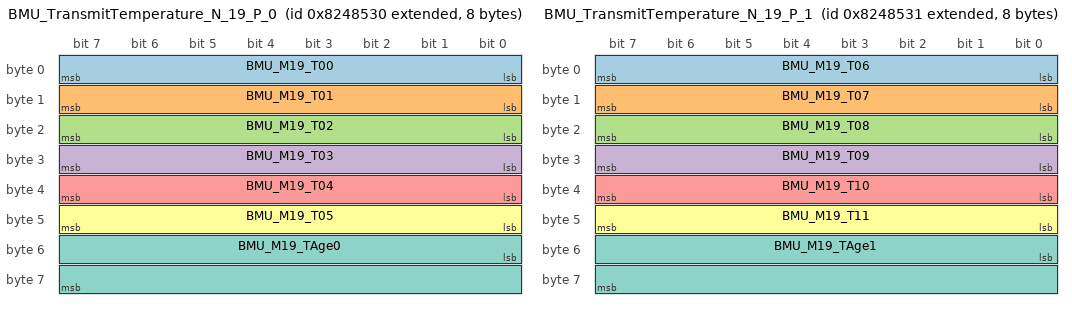
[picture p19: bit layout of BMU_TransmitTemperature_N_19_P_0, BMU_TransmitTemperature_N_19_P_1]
BO_ 2284094768 BMU_TransmitTemperature_N_19_P_0: 8 BMU
 SG_ BMU_M19_T00 : 0|8@1+ (1,0) [0|255] "degC" ECU,LOGGER
 SG_ BMU_M19_T01 : 8|8@1+ (1,0) [0|255] "degC" ECU,LOGGER
 SG_ BMU_M19_T02 : 16|8@1+ (1,0) [0|255] "degC" ECU,LOGGER
 SG_ BMU_M19_T03 : 24|8@1+ (1,0) [0|255] "degC" ECU,LOGGER
 SG_ BMU_M19_T04 : 32|8@1+ (1,0) [0|255] "degC" ECU,LOGGER
 SG_ BMU_M19_T05 : 40|8@1+ (1,0) [0|255] "degC" ECU,LOGGER
 SG_ BMU_M19_TAge0 : 48|16@1+ (1,0) [0|65535] "ms" ECU,LOGGER

BO_ 2284094769 BMU_TransmitTemperature_N_19_P_1: 8 BMU
 SG_ BMU_M19_T06 : 0|8@1+ (1,0) [0|255] "degC" ECU,LOGGER
 SG_ BMU_M19_T07 : 8|8@1+ (1,0) [0|255] "degC" ECU,LOGGER
 SG_ BMU_M19_T08 : 16|8@1+ (1,0) [0|255] "degC" ECU,LOGGER
 SG_ BMU_M19_T09 : 24|8@1+ (1,0) [0|255] "degC" ECU,LOGGER
 SG_ BMU_M19_T10 : 32|8@1+ (1,0) [0|255] "degC" ECU,LOGGER
 SG_ BMU_M19_T11 : 40|8@1+ (1,0) [0|255] "degC" ECU,LOGGER
 SG_ BMU_M19_TAge1 : 48|16@1+ (1,0) [0|65535] "ms" ECU,LOGGER

BO_ 2284094784 BMU_TransmitTemperature_N_20_P_0: 8 BMU
 SG_ BMU_M20_T00 : 0|8@1+ (1,0) [0|255] "degC" ECU,LOGGER
 SG_ BMU_M20_T01 : 8|8@1+ (1,0) [0|255] "degC" ECU,LOGGER
 SG_ BMU_M20_T02 : 16|8@1+ (1,0) [0|255] "degC" ECU,LOGGER
 SG_ BMU_M20_T03 : 24|8@1+ (1,0) [0|255] "degC" ECU,LOGGER
 SG_ BMU_M20_T04 : 32|8@1+ (1,0) [0|255] "degC" ECU,LOGGER
 SG_ BMU_M20_T05 : 40|8@1+ (1,0) [0|255] "degC" ECU,LOGGER
 SG_ BMU_M20_TAge0 : 48|16@1+ (1,0) [0|65535] "ms" ECU,LOGGER

BO_ 2284094785 BMU_TransmitTemperature_N_20_P_1: 8 BMU
 SG_ BMU_M20_T06 : 0|8@1+ (1,0) [0|255] "degC" ECU,LOGGER
 SG_ BMU_M20_T07 : 8|8@1+ (1,0) [0|255] "degC" ECU,LOGGER
 SG_ BMU_M20_T08 : 16|8@1+ (1,0) [0|255] "degC" ECU,LOGGER
 SG_ BMU_M20_T09 : 24|8@1+ (1,0) [0|255] "degC" ECU,LOGGER
 SG_ BMU_M20_T10 : 32|8@1+ (1,0) [0|255] "degC" ECU,LOGGER
 SG_ BMU_M20_T11 : 40|8@1+ (1,0) [0|255] "degC" ECU,LOGGER
 SG_ BMU_M20_TAge1 : 48|16@1+ (1,0) [0|65535] "ms" ECU,LOGGER

BO_ 2284094800 BMU_TransmitTemperature_N_21_P_0: 8 BMU
 SG_ BMU_M21_T00 : 0|8@1+ (1,0) [0|255] "degC" ECU,LOGGER
 SG_ BMU_M21_T01 : 8|8@1+ (1,0) [0|255] "degC" ECU,LOGGER
 SG_ BMU_M21_T02 : 16|8@1+ (1,0) [0|255] "degC" ECU,LOGGER
 SG_ BMU_M21_T03 : 24|8@1+ (1,0) [0|255] "degC" ECU,LOGGER
 SG_ BMU_M21_T04 : 32|8@1+ (1,0) [0|255] "degC" ECU,LOGGER
 SG_ BMU_M21_T05 : 40|8@1+ (1,0) [0|255] "degC" ECU,LOGGER
 SG_ BMU_M21_TAge0 : 48|16@1+ (1,0) [0|65535] "ms" ECU,LOGGER

BO_ 2284094801 BMU_TransmitTemperature_N_21_P_1: 8 BMU
 SG_ BMU_M21_T06 : 0|8@1+ (1,0) [0|255] "degC" ECU,LOGGER
 SG_ BMU_M21_T07 : 8|8@1+ (1,0) [0|255] "degC" ECU,LOGGER
 SG_ BMU_M21_T08 : 16|8@1+ (1,0) [0|255] "degC" ECU,LOGGER
 SG_ BMU_M21_T09 : 24|8@1+ (1,0) [0|255] "degC" ECU,LOGGER
 SG_ BMU_M21_T10 : 32|8@1+ (1,0) [0|255] "degC" ECU,LOGGER
 SG_ BMU_M21_T11 : 40|8@1+ (1,0) [0|255] "degC" ECU,LOGGER
 SG_ BMU_M21_TAge1 : 48|16@1+ (1,0) [0|65535] "ms" ECU,LOGGER

BO_ 2284094816 BMU_TransmitTemperature_N_22_P_0: 8 BMU
 SG_ BMU_M22_T00 : 0|8@1+ (1,0) [0|255] "degC" ECU,LOGGER
 SG_ BMU_M22_T01 : 8|8@1+ (1,0) [0|255] "degC" ECU,LOGGER
 SG_ BMU_M22_T02 : 16|8@1+ (1,0) [0|255] "degC" ECU,LOGGER
 SG_ BMU_M22_T03 : 24|8@1+ (1,0) [0|255] "degC" ECU,LOGGER
 SG_ BMU_M22_T04 : 32|8@1+ (1,0) [0|255] "degC" ECU,LOGGER
 SG_ BMU_M22_T05 : 40|8@1+ (1,0) [0|255] "degC" ECU,LOGGER
 SG_ BMU_M22_TAge0 : 48|16@1+ (1,0) [0|65535] "ms" ECU,LOGGER

BO_ 2284094817 BMU_TransmitTemperature_N_22_P_1: 8 BMU
 SG_ BMU_M22_T06 : 0|8@1+ (1,0) [0|255] "degC" ECU,LOGGER
 SG_ BMU_M22_T07 : 8|8@1+ (1,0) [0|255] "degC" ECU,LOGGER
 SG_ BMU_M22_T08 : 16|8@1+ (1,0) [0|255] "degC" ECU,LOGGER
 SG_ BMU_M22_T09 : 24|8@1+ (1,0) [0|255] "degC" ECU,LOGGER
 SG_ BMU_M22_T10 : 32|8@1+ (1,0) [0|255] "degC" ECU,LOGGER
 SG_ BMU_M22_T11 : 40|8@1+ (1,0) [0|255] "degC" ECU,LOGGER
 SG_ BMU_M22_TAge1 : 48|16@1+ (1,0) [0|65535] "ms" ECU,LOGGER

BO_ 2284094832 BMU_TransmitTemperature_N_23_P_0: 8 BMU
 SG_ BMU_M23_T00 : 0|8@1+ (1,0) [0|255] "degC" ECU,LOGGER
 SG_ BMU_M23_T01 : 8|8@1+ (1,0) [0|255] "degC" ECU,LOGGER
 SG_ BMU_M23_T02 : 16|8@1+ (1,0) [0|255] "degC" ECU,LOGGER
 SG_ BMU_M23_T03 : 24|8@1+ (1,0) [0|255] "degC" ECU,LOGGER
 SG_ BMU_M23_T04 : 32|8@1+ (1,0) [0|255] "degC" ECU,LOGGER
 SG_ BMU_M23_T05 : 40|8@1+ (1,0) [0|255] "degC" ECU,LOGGER
 SG_ BMU_M23_TAge0 : 48|16@1+ (1,0) [0|65535] "ms" ECU,LOGGER

BO_ 2284094833 BMU_TransmitTemperature_N_23_P_1: 8 BMU
 SG_ BMU_M23_T06 : 0|8@1+ (1,0) [0|255] "degC" ECU,LOGGER
 SG_ BMU_M23_T07 : 8|8@1+ (1,0) [0|255] "degC" ECU,LOGGER
 SG_ BMU_M23_T08 : 16|8@1+ (1,0) [0|255] "degC" ECU,LOGGER
 SG_ BMU_M23_T09 : 24|8@1+ (1,0) [0|255] "degC" ECU,LOGGER
 SG_ BMU_M23_T10 : 32|8@1+ (1,0) [0|255] "degC" ECU,LOGGER
 SG_ BMU_M23_T11 : 40|8@1+ (1,0) [0|255] "degC" ECU,LOGGER
 SG_ BMU_M23_TAge1 : 48|16@1+ (1,0) [0|65535] "ms" ECU,LOGGER

BO_ 2284095488 BMU_TransmitBalancing_N_0: 8 BMU
 SG_ BMU_M00_Balance : 0|16@1+ (1,0) [0|65535] "" LOGGER
 SG_ BMU_M00_DieTemp : 16|8@1+ (1,0) [0|255] "degC" LOGGER

BO_ 2284095504 BMU_TransmitBalancing_N_1: 8 BMU
 SG_ BMU_M01_Balance : 0|16@1+ (1,0) [0|65535] "" LOGGER
 SG_ BMU_M01_DieTemp : 16|8@1+ (1,0) [0|255] "degC" LOGGER

BO_ 2284095520 BMU_TransmitBalancing_N_2: 8 BMU
 SG_ BMU_M02_Balance : 0|16@1+ (1,0) [0|65535] "" LOGGER
 SG_ BMU_M02_DieTemp : 16|8@1+ (1,0) [0|255] "degC" LOGGER

BO_ 2284095536 BMU_TransmitBalancing_N_3: 8 BMU
 SG_ BMU_M03_Balance : 0|16@1+ (1,0) [0|65535] "" LOGGER
 SG_ BMU_M03_DieTemp : 16|8@1+ (1,0) [0|255] "degC" LOGGER

BO_ 2284095552 BMU_TransmitBalancing_N_4: 8 BMU
 SG_ BMU_M04_Balance : 0|16@1+ (1,0) [0|65535] "" LOGGER
 SG_ BMU_M04_DieTemp : 16|8@1+ (1,0) [0|255] "degC" LOGGER

BO_ 2284095568 BMU_TransmitBalancing_N_5: 8 BMU
 SG_ BMU_M05_Balance : 0|16@1+ (1,0) [0|65535] "" LOGGER
 SG_ BMU_M05_DieTemp : 16|8@1+ (1,0) [0|255] "degC" LOGGER

BO_ 2284095584 BMU_TransmitBalancing_N_6: 8 BMU
 SG_ BMU_M06_Balance : 0|16@1+ (1,0) [0|65535] "" LOGGER
 SG_ BMU_M06_DieTemp : 16|8@1+ (1,0) [0|255] "degC" LOGGER

BO_ 2284095600 BMU_TransmitBalancing_N_7: 8 BMU
 SG_ BMU_M07_Balance : 0|16@1+ (1,0) [0|65535] "" LOGGER
 SG_ BMU_M07_DieTemp : 16|8@1+ (1,0) [0|255] "degC" LOGGER

BO_ 2284095616 BMU_TransmitBalancing_N_8: 8 BMU
 SG_ BMU_M08_Balance : 0|16@1+ (1,0) [0|65535] "" LOGGER
 SG_ BMU_M08_DieTemp : 16|8@1+ (1,0) [0|255] "degC" LOGGER

BO_ 2284095632 BMU_TransmitBalancing_N_9: 8 BMU
 SG_ BMU_M09_Balance : 0|16@1+ (1,0) [0|65535] "" LOGGER
 SG_ BMU_M09_DieTemp : 16|8@1+ (1,0) [0|255] "degC" LOGGER

BO_ 2284095648 BMU_TransmitBalancing_N_10: 8 BMU
 SG_ BMU_M10_Balance : 0|16@1+ (1,0) [0|65535] "" LOGGER
 SG_ BMU_M10_DieTemp : 16|8@1+ (1,0) [0|255] "degC" LOGGER

BO_ 2284095664 BMU_TransmitBalancing_N_11: 8 BMU
 SG_ BMU_M11_Balance : 0|16@1+ (1,0) [0|65535] "" LOGGER
 SG_ BMU_M11_DieTemp : 16|8@1+ (1,0) [0|255] "degC" LOGGER

BO_ 2284095680 BMU_TransmitBalancing_N_12: 8 BMU
 SG_ BMU_M12_Balance : 0|16@1+ (1,0) [0|65535] "" LOGGER
 SG_ BMU_M12_DieTemp : 16|8@1+ (1,0) [0|255] "degC" LOGGER

BO_ 2284095696 BMU_TransmitBalancing_N_13: 8 BMU
 SG_ BMU_M13_Balance : 0|16@1+ (1,0) [0|65535] "" LOGGER
 SG_ BMU_M13_DieTemp : 16|8@1+ (1,0) [0|255] "degC" LOGGER

BO_ 2284095712 BMU_TransmitBalancing_N_14: 8 BMU
 SG_ BMU_M14_Balance : 0|16@1+ (1,0) [0|65535] "" LOGGER
 SG_ BMU_M14_DieTemp : 16|8@1+ (1,0) [0|255] "degC" LOGGER

BO_ 2284095728 BMU_TransmitBalancing_N_15: 8 BMU
 SG_ BMU_M15_Balance : 0|16@1+ (1,0) [0|65535] "" LOGGER
 SG_ BMU_M15_DieTemp : 16|8@1+ (1,0) [0|255] "degC" LOGGER

CM_ BO_ 2147485244 "Regen's off for comp so MoTeC doesn't bother with it";
CM_ BO_ 2147485245 "Regen's off for comp so MoTeC doesn't bother with it";
CM_ SG_ 2147486012 DTI_L_CmdMaxAcBrake "Negative only";
CM_ SG_ 2147486013 DTI_R_CmdMaxAcBrake "Negative only";
CM_ SG_ 2147486524 DTI_L_CmdMaxDcBrake "Negative only, the manual says % but it's A x10";
CM_ SG_ 2147486525 DTI_R_CmdMaxDcBrake "Negative only, the manual says % but it's A x10";
CM_ BO_ 2147491644 "Leave it off unless something actually needs it";
CM_ BO_ 2147491645 "Leave it off unless something actually needs it";
CM_ BO_ 2147491900 "Broadcast periods are whatever's set in the DTI CAN Tool, not us";
CM_ SG_ 2147491900 DTI_L_Erpm "Electrical, divide by pole pairs for the motor";
CM_ BO_ 2147491901 "Broadcast periods are whatever's set in the DTI CAN Tool, not us";
CM_ SG_ 2147491901 DTI_R_Erpm "Electrical, divide by pole pairs for the motor";
CM_ BO_ 2164260864 "Error priority so it beats everything else onto the bus";
CM_ SG_ 2281963520 BMU_F_HbEcu "BMU can't hear our heartbeat";
CM_ SG_ 2281963520 BMU_F_PrechargeTimeout "comp25 sets this on any trip with the contactors shut, not just a slow precharge";
CM_ SG_ 2281963520 BMU_PackState "comp25 never fills this";
CM_ SG_ 2281963520 BMU_SOC "comp25 never fills this";
BA_DEF_  "BusType" STRING ;
BA_DEF_  "DBName" STRING ;
BA_DEF_ BO_  "GenMsgCycleTime" INT 0 65535;
BA_DEF_ BO_  "SendType" STRING;
BA_DEF_ BO_  "RxTimeoutMs" INT 0 65535;
BA_DEF_ BO_  "MoTeC" STRING;
BA_DEF_ SG_  "MoTeCLog" STRING;
BA_DEF_ SG_  "MoTeCGroup" STRING;
BA_DEF_ BO_  "Status" STRING;
BA_DEF_ BO_  "Variant" STRING;
BA_DEF_ BO_  "VFrameFormat" ENUM "StandardCAN","ExtendedCAN";
BA_DEF_DEF_  "BusType" "CAN";
BA_DEF_DEF_  "DBName" "";
BA_DEF_DEF_  "GenMsgCycleTime" 0;
BA_DEF_DEF_  "SendType" "Cyclic";
BA_DEF_DEF_  "RxTimeoutMs" 0;
BA_DEF_DEF_  "MoTeC" "No";
BA_DEF_DEF_  "MoTeCLog" "";
BA_DEF_DEF_  "MoTeCGroup" "";
BA_DEF_DEF_  "Status" "Current";
BA_DEF_DEF_  "Variant" "";
BA_DEF_DEF_  "VFrameFormat" "StandardCAN";
BA_ "DBName" "qev6_can_a";
BA_ "GenMsgCycleTime" BO_ 256 1000;
BA_ "RxTimeoutMs" BO_ 256 3000;
BA_ "MoTeC" BO_ 256 "Yes";
BA_ "SendType" BO_ 257 "Event";
BA_ "SendType" BO_ 258 "Event";
BA_ "SendType" BO_ 272 "Event";
BA_ "SendType" BO_ 273 "Event";
BA_ "SendType" BO_ 288 "Event";
BA_ "GenMsgCycleTime" BO_ 289 10;
BA_ "RxTimeoutMs" BO_ 289 30;
BA_ "MoTeC" BO_ 289 "Yes";
BA_ "GenMsgCycleTime" BO_ 290 10;
BA_ "RxTimeoutMs" BO_ 290 30;
BA_ "MoTeC" BO_ 290 "Yes";
BA_ "SendType" BO_ 291 "Event";
BA_ "SendType" BO_ 292 "Event";
BA_ "GenMsgCycleTime" BO_ 304 1000;
BA_ "RxTimeoutMs" BO_ 304 3000;
BA_ "MoTeC" BO_ 304 "Yes";
BA_ "SendType" BO_ 305 "Event";
BA_ "GenMsgCycleTime" BO_ 306 20;
BA_ "RxTimeoutMs" BO_ 306 60;
BA_ "MoTeC" BO_ 306 "Yes";
BA_ "SendType" BO_ 307 "Event";
BA_ "GenMsgCycleTime" BO_ 308 100;
BA_ "RxTimeoutMs" BO_ 308 300;
BA_ "MoTeC" BO_ 308 "Yes";
BA_ "GenMsgCycleTime" BO_ 309 100;
BA_ "RxTimeoutMs" BO_ 309 300;
BA_ "MoTeC" BO_ 309 "Yes";
BA_ "SendType" BO_ 310 "Event";
BA_ "GenMsgCycleTime" BO_ 311 20;
BA_ "RxTimeoutMs" BO_ 311 60;
BA_ "MoTeC" BO_ 311 "Yes";
BA_ "SendType" BO_ 312 "Event";
BA_ "GenMsgCycleTime" BO_ 313 20;
BA_ "RxTimeoutMs" BO_ 313 60;
BA_ "MoTeC" BO_ 313 "Yes";
BA_ "SendType" BO_ 320 "Event";
BA_ "SendType" BO_ 321 "Event";
BA_ "SendType" BO_ 325 "Event";
BA_ "SendType" BO_ 329 "Event";
BA_ "SendType" BO_ 330 "Event";
BA_ "SendType" BO_ 331 "Event";
BA_ "SendType" BO_ 332 "Event";
BA_ "SendType" BO_ 333 "Event";
BA_ "SendType" BO_ 336 "Event";
BA_ "SendType" BO_ 337 "Event";
BA_ "SendType" BO_ 338 "Event";
BA_ "SendType" BO_ 352 "Event";
BA_ "SendType" BO_ 353 "Event";
BA_ "SendType" BO_ 354 "Event";
BA_ "SendType" BO_ 355 "Event";
BA_ "SendType" BO_ 356 "Event";
BA_ "SendType" BO_ 358 "Event";
BA_ "SendType" BO_ 359 "Event";
BA_ "SendType" BO_ 368 "Event";
BA_ "GenMsgCycleTime" BO_ 369 100;
BA_ "RxTimeoutMs" BO_ 369 300;
BA_ "MoTeC" BO_ 369 "Yes";
BA_ "SendType" BO_ 370 "Event";
BA_ "SendType" BO_ 371 "Event";
BA_ "SendType" BO_ 372 "Event";
BA_ "GenMsgCycleTime" BO_ 373 100;
BA_ "RxTimeoutMs" BO_ 373 300;
BA_ "MoTeC" BO_ 373 "Yes";
BA_ "SendType" BO_ 374 "Event";
BA_ "SendType" BO_ 375 "Event";
BA_ "SendType" BO_ 376 "Event";
BA_ "SendType" BO_ 377 "Event";
BA_ "SendType" BO_ 384 "Event";
BA_ "SendType" BO_ 385 "Event";
BA_ "SendType" BO_ 386 "Event";
BA_ "SendType" BO_ 387 "Event";
BA_ "SendType" BO_ 388 "Event";
BA_ "SendType" BO_ 389 "Event";
BA_ "SendType" BO_ 390 "Event";
BA_ "SendType" BO_ 391 "Event";
BA_ "SendType" BO_ 392 "Event";
BA_ "SendType" BO_ 393 "Event";
BA_ "SendType" BO_ 512 "Event";
BA_ "SendType" BO_ 513 "Event";
BA_ "SendType" BO_ 514 "Event";
BA_ "SendType" BO_ 515 "Event";
BA_ "SendType" BO_ 516 "Event";
BA_ "SendType" BO_ 517 "Event";
BA_ "SendType" BO_ 518 "Event";
BA_ "SendType" BO_ 519 "Event";
BA_ "SendType" BO_ 520 "Event";
BA_ "SendType" BO_ 521 "Event";
BA_ "GenMsgCycleTime" BO_ 544 20;
BA_ "RxTimeoutMs" BO_ 544 60;
BA_ "MoTeC" BO_ 544 "Yes";
BA_ "GenMsgCycleTime" BO_ 2147484988 10;
BA_ "MoTeC" BO_ 2147484988 "Yes";
BA_ "Variant" BO_ 2147484988 "inv_dti";
BA_ "VFrameFormat" BO_ 2147484988 1;
BA_ "GenMsgCycleTime" BO_ 2147484989 10;
BA_ "MoTeC" BO_ 2147484989 "Yes";
BA_ "Variant" BO_ 2147484989 "inv_dti";
BA_ "VFrameFormat" BO_ 2147484989 1;
BA_ "GenMsgCycleTime" BO_ 2147485244 10;
BA_ "SendType" BO_ 2147485244 "Event";
BA_ "Variant" BO_ 2147485244 "inv_dti";
BA_ "VFrameFormat" BO_ 2147485244 1;
BA_ "GenMsgCycleTime" BO_ 2147485245 10;
BA_ "SendType" BO_ 2147485245 "Event";
BA_ "Variant" BO_ 2147485245 "inv_dti";
BA_ "VFrameFormat" BO_ 2147485245 1;
BA_ "SendType" BO_ 2147485756 "Event";
BA_ "Variant" BO_ 2147485756 "inv_dti";
BA_ "VFrameFormat" BO_ 2147485756 1;
BA_ "SendType" BO_ 2147485757 "Event";
BA_ "Variant" BO_ 2147485757 "inv_dti";
BA_ "VFrameFormat" BO_ 2147485757 1;
BA_ "SendType" BO_ 2147486012 "Event";
BA_ "Variant" BO_ 2147486012 "inv_dti";
BA_ "VFrameFormat" BO_ 2147486012 1;
BA_ "SendType" BO_ 2147486013 "Event";
BA_ "Variant" BO_ 2147486013 "inv_dti";
BA_ "VFrameFormat" BO_ 2147486013 1;
BA_ "SendType" BO_ 2147486268 "Event";
BA_ "Variant" BO_ 2147486268 "inv_dti";
BA_ "VFrameFormat" BO_ 2147486268 1;
BA_ "SendType" BO_ 2147486269 "Event";
BA_ "Variant" BO_ 2147486269 "inv_dti";
BA_ "VFrameFormat" BO_ 2147486269 1;
BA_ "SendType" BO_ 2147486524 "Event";
BA_ "Variant" BO_ 2147486524 "inv_dti";
BA_ "VFrameFormat" BO_ 2147486524 1;
BA_ "SendType" BO_ 2147486525 "Event";
BA_ "Variant" BO_ 2147486525 "inv_dti";
BA_ "VFrameFormat" BO_ 2147486525 1;
BA_ "GenMsgCycleTime" BO_ 2147486780 100;
BA_ "MoTeC" BO_ 2147486780 "Yes";
BA_ "Variant" BO_ 2147486780 "inv_dti";
BA_ "VFrameFormat" BO_ 2147486780 1;
BA_ "GenMsgCycleTime" BO_ 2147486781 100;
BA_ "MoTeC" BO_ 2147486781 "Yes";
BA_ "Variant" BO_ 2147486781 "inv_dti";
BA_ "VFrameFormat" BO_ 2147486781 1;
BA_ "SendType" BO_ 2147491644 "Event";
BA_ "Variant" BO_ 2147491644 "inv_dti";
BA_ "VFrameFormat" BO_ 2147491644 1;
BA_ "SendType" BO_ 2147491645 "Event";
BA_ "Variant" BO_ 2147491645 "inv_dti";
BA_ "VFrameFormat" BO_ 2147491645 1;
BA_ "GenMsgCycleTime" BO_ 2147491900 10;
BA_ "RxTimeoutMs" BO_ 2147491900 500;
BA_ "MoTeC" BO_ 2147491900 "Yes";
BA_ "Variant" BO_ 2147491900 "inv_dti";
BA_ "VFrameFormat" BO_ 2147491900 1;
BA_ "GenMsgCycleTime" BO_ 2147491901 10;
BA_ "RxTimeoutMs" BO_ 2147491901 500;
BA_ "MoTeC" BO_ 2147491901 "Yes";
BA_ "Variant" BO_ 2147491901 "inv_dti";
BA_ "VFrameFormat" BO_ 2147491901 1;
BA_ "GenMsgCycleTime" BO_ 2147492156 10;
BA_ "RxTimeoutMs" BO_ 2147492156 500;
BA_ "MoTeC" BO_ 2147492156 "Yes";
BA_ "Variant" BO_ 2147492156 "inv_dti";
BA_ "VFrameFormat" BO_ 2147492156 1;
BA_ "GenMsgCycleTime" BO_ 2147492157 10;
BA_ "RxTimeoutMs" BO_ 2147492157 500;
BA_ "MoTeC" BO_ 2147492157 "Yes";
BA_ "Variant" BO_ 2147492157 "inv_dti";
BA_ "VFrameFormat" BO_ 2147492157 1;
BA_ "GenMsgCycleTime" BO_ 2147492412 50;
BA_ "RxTimeoutMs" BO_ 2147492412 500;
BA_ "MoTeC" BO_ 2147492412 "Yes";
BA_ "Variant" BO_ 2147492412 "inv_dti";
BA_ "VFrameFormat" BO_ 2147492412 1;
BA_ "GenMsgCycleTime" BO_ 2147492413 50;
BA_ "RxTimeoutMs" BO_ 2147492413 500;
BA_ "MoTeC" BO_ 2147492413 "Yes";
BA_ "Variant" BO_ 2147492413 "inv_dti";
BA_ "VFrameFormat" BO_ 2147492413 1;
BA_ "GenMsgCycleTime" BO_ 2147492668 100;
BA_ "RxTimeoutMs" BO_ 2147492668 500;
BA_ "Variant" BO_ 2147492668 "inv_dti";
BA_ "VFrameFormat" BO_ 2147492668 1;
BA_ "GenMsgCycleTime" BO_ 2147492669 100;
BA_ "RxTimeoutMs" BO_ 2147492669 500;
BA_ "Variant" BO_ 2147492669 "inv_dti";
BA_ "VFrameFormat" BO_ 2147492669 1;
BA_ "GenMsgCycleTime" BO_ 2147492924 50;
BA_ "RxTimeoutMs" BO_ 2147492924 500;
BA_ "MoTeC" BO_ 2147492924 "Yes";
BA_ "Variant" BO_ 2147492924 "inv_dti";
BA_ "VFrameFormat" BO_ 2147492924 1;
BA_ "MoTeCLog" SG_ 2147492924 DTI_L_Throttle "No";
BA_ "MoTeCLog" SG_ 2147492924 DTI_L_Brake "No";
BA_ "MoTeCLog" SG_ 2147492924 DTI_L_DigOut4 "No";
BA_ "MoTeCLog" SG_ 2147492924 DTI_L_DigOut3 "No";
BA_ "MoTeCLog" SG_ 2147492924 DTI_L_DigOut2 "No";
BA_ "MoTeCLog" SG_ 2147492924 DTI_L_DigOut1 "No";
BA_ "MoTeCLog" SG_ 2147492924 DTI_L_DigIn4 "No";
BA_ "MoTeCLog" SG_ 2147492924 DTI_L_DigIn3 "No";
BA_ "MoTeCLog" SG_ 2147492924 DTI_L_DigIn2 "No";
BA_ "MoTeCLog" SG_ 2147492924 DTI_L_DigIn1 "No";
BA_ "MoTeCGroup" SG_ 2147492924 DTI_L_LimMotorTemp "DTI_L_Limits";
BA_ "MoTeCGroup" SG_ 2147492924 DTI_L_LimMotorAccelTemp "DTI_L_Limits";
BA_ "MoTeCGroup" SG_ 2147492924 DTI_L_LimInputVoltage "DTI_L_Limits";
BA_ "MoTeCGroup" SG_ 2147492924 DTI_L_LimIgbtTemp "DTI_L_Limits";
BA_ "MoTeCGroup" SG_ 2147492924 DTI_L_LimIgbtAccelTemp "DTI_L_Limits";
BA_ "MoTeCGroup" SG_ 2147492924 DTI_L_LimDriveEnable "DTI_L_Limits";
BA_ "MoTeCGroup" SG_ 2147492924 DTI_L_LimDcCurrent "DTI_L_Limits";
BA_ "MoTeCGroup" SG_ 2147492924 DTI_L_LimCapTemp "DTI_L_Limits";
BA_ "MoTeCGroup" SG_ 2147492924 DTI_L_LimPower "DTI_L_Limits";
BA_ "MoTeCGroup" SG_ 2147492924 DTI_L_LimRpmMax "DTI_L_Limits";
BA_ "MoTeCGroup" SG_ 2147492924 DTI_L_LimRpmMin "DTI_L_Limits";
BA_ "MoTeCLog" SG_ 2147492924 DTI_L_CanMapVersion "No";
BA_ "GenMsgCycleTime" BO_ 2147492925 50;
BA_ "RxTimeoutMs" BO_ 2147492925 500;
BA_ "MoTeC" BO_ 2147492925 "Yes";
BA_ "Variant" BO_ 2147492925 "inv_dti";
BA_ "VFrameFormat" BO_ 2147492925 1;
BA_ "MoTeCLog" SG_ 2147492925 DTI_R_Throttle "No";
BA_ "MoTeCLog" SG_ 2147492925 DTI_R_Brake "No";
BA_ "MoTeCLog" SG_ 2147492925 DTI_R_DigOut4 "No";
BA_ "MoTeCLog" SG_ 2147492925 DTI_R_DigOut3 "No";
BA_ "MoTeCLog" SG_ 2147492925 DTI_R_DigOut2 "No";
BA_ "MoTeCLog" SG_ 2147492925 DTI_R_DigOut1 "No";
BA_ "MoTeCLog" SG_ 2147492925 DTI_R_DigIn4 "No";
BA_ "MoTeCLog" SG_ 2147492925 DTI_R_DigIn3 "No";
BA_ "MoTeCLog" SG_ 2147492925 DTI_R_DigIn2 "No";
BA_ "MoTeCLog" SG_ 2147492925 DTI_R_DigIn1 "No";
BA_ "MoTeCGroup" SG_ 2147492925 DTI_R_LimMotorTemp "DTI_R_Limits";
BA_ "MoTeCGroup" SG_ 2147492925 DTI_R_LimMotorAccelTemp "DTI_R_Limits";
BA_ "MoTeCGroup" SG_ 2147492925 DTI_R_LimInputVoltage "DTI_R_Limits";
BA_ "MoTeCGroup" SG_ 2147492925 DTI_R_LimIgbtTemp "DTI_R_Limits";
BA_ "MoTeCGroup" SG_ 2147492925 DTI_R_LimIgbtAccelTemp "DTI_R_Limits";
BA_ "MoTeCGroup" SG_ 2147492925 DTI_R_LimDriveEnable "DTI_R_Limits";
BA_ "MoTeCGroup" SG_ 2147492925 DTI_R_LimDcCurrent "DTI_R_Limits";
BA_ "MoTeCGroup" SG_ 2147492925 DTI_R_LimCapTemp "DTI_R_Limits";
BA_ "MoTeCGroup" SG_ 2147492925 DTI_R_LimPower "DTI_R_Limits";
BA_ "MoTeCGroup" SG_ 2147492925 DTI_R_LimRpmMax "DTI_R_Limits";
BA_ "MoTeCGroup" SG_ 2147492925 DTI_R_LimRpmMin "DTI_R_Limits";
BA_ "MoTeCLog" SG_ 2147492925 DTI_R_CanMapVersion "No";
BA_ "GenMsgCycleTime" BO_ 2147493180 100;
BA_ "RxTimeoutMs" BO_ 2147493180 500;
BA_ "Variant" BO_ 2147493180 "inv_dti";
BA_ "VFrameFormat" BO_ 2147493180 1;
BA_ "GenMsgCycleTime" BO_ 2147493181 100;
BA_ "RxTimeoutMs" BO_ 2147493181 500;
BA_ "Variant" BO_ 2147493181 "inv_dti";
BA_ "VFrameFormat" BO_ 2147493181 1;
BA_ "GenMsgCycleTime" BO_ 2147493436 100;
BA_ "RxTimeoutMs" BO_ 2147493436 500;
BA_ "Variant" BO_ 2147493436 "inv_dti";
BA_ "VFrameFormat" BO_ 2147493436 1;
BA_ "GenMsgCycleTime" BO_ 2147493437 100;
BA_ "RxTimeoutMs" BO_ 2147493437 500;
BA_ "Variant" BO_ 2147493437 "inv_dti";
BA_ "VFrameFormat" BO_ 2147493437 1;
BA_ "SendType" BO_ 2164260864 "Event";
BA_ "Status" BO_ 2164260864 "Planned";
BA_ "VFrameFormat" BO_ 2164260864 1;
BA_ "GenMsgCycleTime" BO_ 2165338473 10;
BA_ "Variant" BO_ 2165338473 "inv_sevcon";
BA_ "VFrameFormat" BO_ 2165338473 1;
BA_ "GenMsgCycleTime" BO_ 2165338729 10;
BA_ "Variant" BO_ 2165338729 "inv_sevcon";
BA_ "VFrameFormat" BO_ 2165338729 1;
BA_ "GenMsgCycleTime" BO_ 2165404009 10;
BA_ "Variant" BO_ 2165404009 "inv_sevcon";
BA_ "VFrameFormat" BO_ 2165404009 1;
BA_ "GenMsgCycleTime" BO_ 2165404265 10;
BA_ "Variant" BO_ 2165404265 "inv_sevcon";
BA_ "VFrameFormat" BO_ 2165404265 1;
BA_ "GenMsgCycleTime" BO_ 2165469545 10;
BA_ "Variant" BO_ 2165469545 "inv_sevcon";
BA_ "VFrameFormat" BO_ 2165469545 1;
BA_ "GenMsgCycleTime" BO_ 2165469801 10;
BA_ "Variant" BO_ 2165469801 "inv_sevcon";
BA_ "VFrameFormat" BO_ 2165469801 1;
BA_ "GenMsgCycleTime" BO_ 2281963520 100;
BA_ "RxTimeoutMs" BO_ 2281963520 1000;
BA_ "MoTeC" BO_ 2281963520 "Yes";
BA_ "Status" BO_ 2281963520 "Planned";
BA_ "Variant" BO_ 2281963520 "bmu_qev6";
BA_ "VFrameFormat" BO_ 2281963520 1;
BA_ "MoTeCGroup" SG_ 2281963520 BMU_F_HbCmu "BMU_Flags";
BA_ "MoTeCGroup" SG_ 2281963520 BMU_F_HbSendyne1 "BMU_Flags";
BA_ "MoTeCGroup" SG_ 2281963520 BMU_F_HbSendyne2 "BMU_Flags";
BA_ "MoTeCGroup" SG_ 2281963520 BMU_F_HbEcu "BMU_Flags";
BA_ "MoTeCGroup" SG_ 2281963520 BMU_F_HbChrgCtrl "BMU_Flags";
BA_ "MoTeCGroup" SG_ 2281963520 BMU_F_Watchdog "BMU_Flags";
BA_ "MoTeCGroup" SG_ 2281963520 BMU_F_Can1 "BMU_Flags";
BA_ "MoTeCGroup" SG_ 2281963520 BMU_F_Can2 "BMU_Flags";
BA_ "MoTeCGroup" SG_ 2281963520 BMU_F_ContactorPos "BMU_Flags";
BA_ "MoTeCGroup" SG_ 2281963520 BMU_F_ContactorNeg "BMU_Flags";
BA_ "MoTeCGroup" SG_ 2281963520 BMU_F_ContactorPchrg "BMU_Flags";
BA_ "MoTeCGroup" SG_ 2281963520 BMU_F_PrechargeTimeout "BMU_Flags";
BA_ "MoTeCGroup" SG_ 2281963520 BMU_F_CmuOverVolt "BMU_Flags";
BA_ "MoTeCGroup" SG_ 2281963520 BMU_F_CmuUnderVolt "BMU_Flags";
BA_ "MoTeCGroup" SG_ 2281963520 BMU_F_CmuBadTemp "BMU_Flags";
BA_ "MoTeCGroup" SG_ 2281963520 BMU_F_CmuOpenVolt "BMU_Flags";
BA_ "MoTeCGroup" SG_ 2281963520 BMU_F_CmuOpenTemp "BMU_Flags";
BA_ "MoTeCGroup" SG_ 2281963520 BMU_F_CmuMissingVolt "BMU_Flags";
BA_ "MoTeCGroup" SG_ 2281963520 BMU_F_CmuMissingTemp "BMU_Flags";
BA_ "MoTeCGroup" SG_ 2281963520 BMU_F_ShdnBmu "BMU_Flags";
BA_ "MoTeCGroup" SG_ 2281963520 BMU_F_ShdnPdoc "BMU_Flags";
BA_ "MoTeCGroup" SG_ 2281963520 BMU_F_ShdnImd "BMU_Flags";
BA_ "MoTeCGroup" SG_ 2281963520 BMU_F_ShdnInterlock "BMU_Flags";
BA_ "MoTeCGroup" SG_ 2281963520 BMU_F_Balancing "BMU_Flags";
BA_ "MoTeCGroup" SG_ 2281963520 BMU_F_DieTemps "BMU_Flags";
BA_ "MoTeCGroup" SG_ 2281963520 BMU_F_HvKey "BMU_Flags";
BA_ "MoTeCGroup" SG_ 2281963520 BMU_F_ChrgDetect "BMU_Flags";
BA_ "MoTeCGroup" SG_ 2281963520 BMU_F_ChrgCtrl "BMU_Flags";
BA_ "MoTeCLog" SG_ 2281963520 BMU_PackState "No";
BA_ "MoTeCLog" SG_ 2281963520 BMU_SOC "No";
BA_ "GenMsgCycleTime" BO_ 2284093440 3300;
BA_ "SendType" BO_ 2284093440 "Burst";
BA_ "Variant" BO_ 2284093440 "bmu_comp25";
BA_ "VFrameFormat" BO_ 2284093440 1;
BA_ "GenMsgCycleTime" BO_ 2284093441 3300;
BA_ "SendType" BO_ 2284093441 "Burst";
BA_ "Variant" BO_ 2284093441 "bmu_comp25";
BA_ "VFrameFormat" BO_ 2284093441 1;
BA_ "GenMsgCycleTime" BO_ 2284093442 3300;
BA_ "SendType" BO_ 2284093442 "Burst";
BA_ "Variant" BO_ 2284093442 "bmu_comp25";
BA_ "VFrameFormat" BO_ 2284093442 1;
BA_ "GenMsgCycleTime" BO_ 2284093443 3300;
BA_ "SendType" BO_ 2284093443 "Burst";
BA_ "Variant" BO_ 2284093443 "bmu_comp25";
BA_ "VFrameFormat" BO_ 2284093443 1;
BA_ "GenMsgCycleTime" BO_ 2284093456 3300;
BA_ "SendType" BO_ 2284093456 "Burst";
BA_ "Variant" BO_ 2284093456 "bmu_comp25";
BA_ "VFrameFormat" BO_ 2284093456 1;
BA_ "GenMsgCycleTime" BO_ 2284093457 3300;
BA_ "SendType" BO_ 2284093457 "Burst";
BA_ "Variant" BO_ 2284093457 "bmu_comp25";
BA_ "VFrameFormat" BO_ 2284093457 1;
BA_ "GenMsgCycleTime" BO_ 2284093458 3300;
BA_ "SendType" BO_ 2284093458 "Burst";
BA_ "Variant" BO_ 2284093458 "bmu_comp25";
BA_ "VFrameFormat" BO_ 2284093458 1;
BA_ "GenMsgCycleTime" BO_ 2284093459 3300;
BA_ "SendType" BO_ 2284093459 "Burst";
BA_ "Variant" BO_ 2284093459 "bmu_comp25";
BA_ "VFrameFormat" BO_ 2284093459 1;
BA_ "GenMsgCycleTime" BO_ 2284093472 3300;
BA_ "SendType" BO_ 2284093472 "Burst";
BA_ "Variant" BO_ 2284093472 "bmu_comp25";
BA_ "VFrameFormat" BO_ 2284093472 1;
BA_ "GenMsgCycleTime" BO_ 2284093473 3300;
BA_ "SendType" BO_ 2284093473 "Burst";
BA_ "Variant" BO_ 2284093473 "bmu_comp25";
BA_ "VFrameFormat" BO_ 2284093473 1;
BA_ "GenMsgCycleTime" BO_ 2284093474 3300;
BA_ "SendType" BO_ 2284093474 "Burst";
BA_ "Variant" BO_ 2284093474 "bmu_comp25";
BA_ "VFrameFormat" BO_ 2284093474 1;
BA_ "GenMsgCycleTime" BO_ 2284093475 3300;
BA_ "SendType" BO_ 2284093475 "Burst";
BA_ "Variant" BO_ 2284093475 "bmu_comp25";
BA_ "VFrameFormat" BO_ 2284093475 1;
BA_ "GenMsgCycleTime" BO_ 2284093488 3300;
BA_ "SendType" BO_ 2284093488 "Burst";
BA_ "Variant" BO_ 2284093488 "bmu_comp25";
BA_ "VFrameFormat" BO_ 2284093488 1;
BA_ "GenMsgCycleTime" BO_ 2284093489 3300;
BA_ "SendType" BO_ 2284093489 "Burst";
BA_ "Variant" BO_ 2284093489 "bmu_comp25";
BA_ "VFrameFormat" BO_ 2284093489 1;
BA_ "GenMsgCycleTime" BO_ 2284093490 3300;
BA_ "SendType" BO_ 2284093490 "Burst";
BA_ "Variant" BO_ 2284093490 "bmu_comp25";
BA_ "VFrameFormat" BO_ 2284093490 1;
BA_ "GenMsgCycleTime" BO_ 2284093491 3300;
BA_ "SendType" BO_ 2284093491 "Burst";
BA_ "Variant" BO_ 2284093491 "bmu_comp25";
BA_ "VFrameFormat" BO_ 2284093491 1;
BA_ "GenMsgCycleTime" BO_ 2284093504 3300;
BA_ "SendType" BO_ 2284093504 "Burst";
BA_ "Variant" BO_ 2284093504 "bmu_comp25";
BA_ "VFrameFormat" BO_ 2284093504 1;
BA_ "GenMsgCycleTime" BO_ 2284093505 3300;
BA_ "SendType" BO_ 2284093505 "Burst";
BA_ "Variant" BO_ 2284093505 "bmu_comp25";
BA_ "VFrameFormat" BO_ 2284093505 1;
BA_ "GenMsgCycleTime" BO_ 2284093506 3300;
BA_ "SendType" BO_ 2284093506 "Burst";
BA_ "Variant" BO_ 2284093506 "bmu_comp25";
BA_ "VFrameFormat" BO_ 2284093506 1;
BA_ "GenMsgCycleTime" BO_ 2284093507 3300;
BA_ "SendType" BO_ 2284093507 "Burst";
BA_ "Variant" BO_ 2284093507 "bmu_comp25";
BA_ "VFrameFormat" BO_ 2284093507 1;
BA_ "GenMsgCycleTime" BO_ 2284093520 3300;
BA_ "SendType" BO_ 2284093520 "Burst";
BA_ "Variant" BO_ 2284093520 "bmu_comp25";
BA_ "VFrameFormat" BO_ 2284093520 1;
BA_ "GenMsgCycleTime" BO_ 2284093521 3300;
BA_ "SendType" BO_ 2284093521 "Burst";
BA_ "Variant" BO_ 2284093521 "bmu_comp25";
BA_ "VFrameFormat" BO_ 2284093521 1;
BA_ "GenMsgCycleTime" BO_ 2284093522 3300;
BA_ "SendType" BO_ 2284093522 "Burst";
BA_ "Variant" BO_ 2284093522 "bmu_comp25";
BA_ "VFrameFormat" BO_ 2284093522 1;
BA_ "GenMsgCycleTime" BO_ 2284093523 3300;
BA_ "SendType" BO_ 2284093523 "Burst";
BA_ "Variant" BO_ 2284093523 "bmu_comp25";
BA_ "VFrameFormat" BO_ 2284093523 1;
BA_ "GenMsgCycleTime" BO_ 2284093536 3300;
BA_ "SendType" BO_ 2284093536 "Burst";
BA_ "Variant" BO_ 2284093536 "bmu_comp25";
BA_ "VFrameFormat" BO_ 2284093536 1;
BA_ "GenMsgCycleTime" BO_ 2284093537 3300;
BA_ "SendType" BO_ 2284093537 "Burst";
BA_ "Variant" BO_ 2284093537 "bmu_comp25";
BA_ "VFrameFormat" BO_ 2284093537 1;
BA_ "GenMsgCycleTime" BO_ 2284093538 3300;
BA_ "SendType" BO_ 2284093538 "Burst";
BA_ "Variant" BO_ 2284093538 "bmu_comp25";
BA_ "VFrameFormat" BO_ 2284093538 1;
BA_ "GenMsgCycleTime" BO_ 2284093539 3300;
BA_ "SendType" BO_ 2284093539 "Burst";
BA_ "Variant" BO_ 2284093539 "bmu_comp25";
BA_ "VFrameFormat" BO_ 2284093539 1;
BA_ "GenMsgCycleTime" BO_ 2284093552 3300;
BA_ "SendType" BO_ 2284093552 "Burst";
BA_ "Variant" BO_ 2284093552 "bmu_comp25";
BA_ "VFrameFormat" BO_ 2284093552 1;
BA_ "GenMsgCycleTime" BO_ 2284093553 3300;
BA_ "SendType" BO_ 2284093553 "Burst";
BA_ "Variant" BO_ 2284093553 "bmu_comp25";
BA_ "VFrameFormat" BO_ 2284093553 1;
BA_ "GenMsgCycleTime" BO_ 2284093554 3300;
BA_ "SendType" BO_ 2284093554 "Burst";
BA_ "Variant" BO_ 2284093554 "bmu_comp25";
BA_ "VFrameFormat" BO_ 2284093554 1;
BA_ "GenMsgCycleTime" BO_ 2284093555 3300;
BA_ "SendType" BO_ 2284093555 "Burst";
BA_ "Variant" BO_ 2284093555 "bmu_comp25";
BA_ "VFrameFormat" BO_ 2284093555 1;
BA_ "GenMsgCycleTime" BO_ 2284093568 3300;
BA_ "SendType" BO_ 2284093568 "Burst";
BA_ "Variant" BO_ 2284093568 "bmu_comp25";
BA_ "VFrameFormat" BO_ 2284093568 1;
BA_ "GenMsgCycleTime" BO_ 2284093569 3300;
BA_ "SendType" BO_ 2284093569 "Burst";
BA_ "Variant" BO_ 2284093569 "bmu_comp25";
BA_ "VFrameFormat" BO_ 2284093569 1;
BA_ "GenMsgCycleTime" BO_ 2284093570 3300;
BA_ "SendType" BO_ 2284093570 "Burst";
BA_ "Variant" BO_ 2284093570 "bmu_comp25";
BA_ "VFrameFormat" BO_ 2284093570 1;
BA_ "GenMsgCycleTime" BO_ 2284093571 3300;
BA_ "SendType" BO_ 2284093571 "Burst";
BA_ "Variant" BO_ 2284093571 "bmu_comp25";
BA_ "VFrameFormat" BO_ 2284093571 1;
BA_ "GenMsgCycleTime" BO_ 2284093584 3300;
BA_ "SendType" BO_ 2284093584 "Burst";
BA_ "Variant" BO_ 2284093584 "bmu_comp25";
BA_ "VFrameFormat" BO_ 2284093584 1;
BA_ "GenMsgCycleTime" BO_ 2284093585 3300;
BA_ "SendType" BO_ 2284093585 "Burst";
BA_ "Variant" BO_ 2284093585 "bmu_comp25";
BA_ "VFrameFormat" BO_ 2284093585 1;
BA_ "GenMsgCycleTime" BO_ 2284093586 3300;
BA_ "SendType" BO_ 2284093586 "Burst";
BA_ "Variant" BO_ 2284093586 "bmu_comp25";
BA_ "VFrameFormat" BO_ 2284093586 1;
BA_ "GenMsgCycleTime" BO_ 2284093587 3300;
BA_ "SendType" BO_ 2284093587 "Burst";
BA_ "Variant" BO_ 2284093587 "bmu_comp25";
BA_ "VFrameFormat" BO_ 2284093587 1;
BA_ "GenMsgCycleTime" BO_ 2284093600 3300;
BA_ "SendType" BO_ 2284093600 "Burst";
BA_ "Variant" BO_ 2284093600 "bmu_comp25";
BA_ "VFrameFormat" BO_ 2284093600 1;
BA_ "GenMsgCycleTime" BO_ 2284093601 3300;
BA_ "SendType" BO_ 2284093601 "Burst";
BA_ "Variant" BO_ 2284093601 "bmu_comp25";
BA_ "VFrameFormat" BO_ 2284093601 1;
BA_ "GenMsgCycleTime" BO_ 2284093602 3300;
BA_ "SendType" BO_ 2284093602 "Burst";
BA_ "Variant" BO_ 2284093602 "bmu_comp25";
BA_ "VFrameFormat" BO_ 2284093602 1;
BA_ "GenMsgCycleTime" BO_ 2284093603 3300;
BA_ "SendType" BO_ 2284093603 "Burst";
BA_ "Variant" BO_ 2284093603 "bmu_comp25";
BA_ "VFrameFormat" BO_ 2284093603 1;
BA_ "GenMsgCycleTime" BO_ 2284093616 3300;
BA_ "SendType" BO_ 2284093616 "Burst";
BA_ "Variant" BO_ 2284093616 "bmu_comp25";
BA_ "VFrameFormat" BO_ 2284093616 1;
BA_ "GenMsgCycleTime" BO_ 2284093617 3300;
BA_ "SendType" BO_ 2284093617 "Burst";
BA_ "Variant" BO_ 2284093617 "bmu_comp25";
BA_ "VFrameFormat" BO_ 2284093617 1;
BA_ "GenMsgCycleTime" BO_ 2284093618 3300;
BA_ "SendType" BO_ 2284093618 "Burst";
BA_ "Variant" BO_ 2284093618 "bmu_comp25";
BA_ "VFrameFormat" BO_ 2284093618 1;
BA_ "GenMsgCycleTime" BO_ 2284093619 3300;
BA_ "SendType" BO_ 2284093619 "Burst";
BA_ "Variant" BO_ 2284093619 "bmu_comp25";
BA_ "VFrameFormat" BO_ 2284093619 1;
BA_ "GenMsgCycleTime" BO_ 2284093632 3300;
BA_ "SendType" BO_ 2284093632 "Burst";
BA_ "Variant" BO_ 2284093632 "bmu_comp25";
BA_ "VFrameFormat" BO_ 2284093632 1;
BA_ "GenMsgCycleTime" BO_ 2284093633 3300;
BA_ "SendType" BO_ 2284093633 "Burst";
BA_ "Variant" BO_ 2284093633 "bmu_comp25";
BA_ "VFrameFormat" BO_ 2284093633 1;
BA_ "GenMsgCycleTime" BO_ 2284093634 3300;
BA_ "SendType" BO_ 2284093634 "Burst";
BA_ "Variant" BO_ 2284093634 "bmu_comp25";
BA_ "VFrameFormat" BO_ 2284093634 1;
BA_ "GenMsgCycleTime" BO_ 2284093635 3300;
BA_ "SendType" BO_ 2284093635 "Burst";
BA_ "Variant" BO_ 2284093635 "bmu_comp25";
BA_ "VFrameFormat" BO_ 2284093635 1;
BA_ "GenMsgCycleTime" BO_ 2284093648 3300;
BA_ "SendType" BO_ 2284093648 "Burst";
BA_ "Variant" BO_ 2284093648 "bmu_comp25";
BA_ "VFrameFormat" BO_ 2284093648 1;
BA_ "GenMsgCycleTime" BO_ 2284093649 3300;
BA_ "SendType" BO_ 2284093649 "Burst";
BA_ "Variant" BO_ 2284093649 "bmu_comp25";
BA_ "VFrameFormat" BO_ 2284093649 1;
BA_ "GenMsgCycleTime" BO_ 2284093650 3300;
BA_ "SendType" BO_ 2284093650 "Burst";
BA_ "Variant" BO_ 2284093650 "bmu_comp25";
BA_ "VFrameFormat" BO_ 2284093650 1;
BA_ "GenMsgCycleTime" BO_ 2284093651 3300;
BA_ "SendType" BO_ 2284093651 "Burst";
BA_ "Variant" BO_ 2284093651 "bmu_comp25";
BA_ "VFrameFormat" BO_ 2284093651 1;
BA_ "GenMsgCycleTime" BO_ 2284093664 3300;
BA_ "SendType" BO_ 2284093664 "Burst";
BA_ "Variant" BO_ 2284093664 "bmu_comp25";
BA_ "VFrameFormat" BO_ 2284093664 1;
BA_ "GenMsgCycleTime" BO_ 2284093665 3300;
BA_ "SendType" BO_ 2284093665 "Burst";
BA_ "Variant" BO_ 2284093665 "bmu_comp25";
BA_ "VFrameFormat" BO_ 2284093665 1;
BA_ "GenMsgCycleTime" BO_ 2284093666 3300;
BA_ "SendType" BO_ 2284093666 "Burst";
BA_ "Variant" BO_ 2284093666 "bmu_comp25";
BA_ "VFrameFormat" BO_ 2284093666 1;
BA_ "GenMsgCycleTime" BO_ 2284093667 3300;
BA_ "SendType" BO_ 2284093667 "Burst";
BA_ "Variant" BO_ 2284093667 "bmu_comp25";
BA_ "VFrameFormat" BO_ 2284093667 1;
BA_ "GenMsgCycleTime" BO_ 2284093680 3300;
BA_ "SendType" BO_ 2284093680 "Burst";
BA_ "Variant" BO_ 2284093680 "bmu_comp25";
BA_ "VFrameFormat" BO_ 2284093680 1;
BA_ "GenMsgCycleTime" BO_ 2284093681 3300;
BA_ "SendType" BO_ 2284093681 "Burst";
BA_ "Variant" BO_ 2284093681 "bmu_comp25";
BA_ "VFrameFormat" BO_ 2284093681 1;
BA_ "GenMsgCycleTime" BO_ 2284093682 3300;
BA_ "SendType" BO_ 2284093682 "Burst";
BA_ "Variant" BO_ 2284093682 "bmu_comp25";
BA_ "VFrameFormat" BO_ 2284093682 1;
BA_ "GenMsgCycleTime" BO_ 2284093683 3300;
BA_ "SendType" BO_ 2284093683 "Burst";
BA_ "Variant" BO_ 2284093683 "bmu_comp25";
BA_ "VFrameFormat" BO_ 2284093683 1;
BA_ "GenMsgCycleTime" BO_ 2284093696 3300;
BA_ "SendType" BO_ 2284093696 "Burst";
BA_ "Variant" BO_ 2284093696 "bmu_comp25";
BA_ "VFrameFormat" BO_ 2284093696 1;
BA_ "GenMsgCycleTime" BO_ 2284093697 3300;
BA_ "SendType" BO_ 2284093697 "Burst";
BA_ "Variant" BO_ 2284093697 "bmu_comp25";
BA_ "VFrameFormat" BO_ 2284093697 1;
BA_ "GenMsgCycleTime" BO_ 2284093698 3300;
BA_ "SendType" BO_ 2284093698 "Burst";
BA_ "Variant" BO_ 2284093698 "bmu_comp25";
BA_ "VFrameFormat" BO_ 2284093698 1;
BA_ "GenMsgCycleTime" BO_ 2284093699 3300;
BA_ "SendType" BO_ 2284093699 "Burst";
BA_ "Variant" BO_ 2284093699 "bmu_comp25";
BA_ "VFrameFormat" BO_ 2284093699 1;
BA_ "GenMsgCycleTime" BO_ 2284093712 3300;
BA_ "SendType" BO_ 2284093712 "Burst";
BA_ "Variant" BO_ 2284093712 "bmu_comp25";
BA_ "VFrameFormat" BO_ 2284093712 1;
BA_ "GenMsgCycleTime" BO_ 2284093713 3300;
BA_ "SendType" BO_ 2284093713 "Burst";
BA_ "Variant" BO_ 2284093713 "bmu_comp25";
BA_ "VFrameFormat" BO_ 2284093713 1;
BA_ "GenMsgCycleTime" BO_ 2284093714 3300;
BA_ "SendType" BO_ 2284093714 "Burst";
BA_ "Variant" BO_ 2284093714 "bmu_comp25";
BA_ "VFrameFormat" BO_ 2284093714 1;
BA_ "GenMsgCycleTime" BO_ 2284093715 3300;
BA_ "SendType" BO_ 2284093715 "Burst";
BA_ "Variant" BO_ 2284093715 "bmu_comp25";
BA_ "VFrameFormat" BO_ 2284093715 1;
BA_ "GenMsgCycleTime" BO_ 2284093728 3300;
BA_ "SendType" BO_ 2284093728 "Burst";
BA_ "Variant" BO_ 2284093728 "bmu_comp25";
BA_ "VFrameFormat" BO_ 2284093728 1;
BA_ "GenMsgCycleTime" BO_ 2284093729 3300;
BA_ "SendType" BO_ 2284093729 "Burst";
BA_ "Variant" BO_ 2284093729 "bmu_comp25";
BA_ "VFrameFormat" BO_ 2284093729 1;
BA_ "GenMsgCycleTime" BO_ 2284093730 3300;
BA_ "SendType" BO_ 2284093730 "Burst";
BA_ "Variant" BO_ 2284093730 "bmu_comp25";
BA_ "VFrameFormat" BO_ 2284093730 1;
BA_ "GenMsgCycleTime" BO_ 2284093731 3300;
BA_ "SendType" BO_ 2284093731 "Burst";
BA_ "Variant" BO_ 2284093731 "bmu_comp25";
BA_ "VFrameFormat" BO_ 2284093731 1;
BA_ "GenMsgCycleTime" BO_ 2284093744 3300;
BA_ "SendType" BO_ 2284093744 "Burst";
BA_ "Variant" BO_ 2284093744 "bmu_comp25";
BA_ "VFrameFormat" BO_ 2284093744 1;
BA_ "GenMsgCycleTime" BO_ 2284093745 3300;
BA_ "SendType" BO_ 2284093745 "Burst";
BA_ "Variant" BO_ 2284093745 "bmu_comp25";
BA_ "VFrameFormat" BO_ 2284093745 1;
BA_ "GenMsgCycleTime" BO_ 2284093746 3300;
BA_ "SendType" BO_ 2284093746 "Burst";
BA_ "Variant" BO_ 2284093746 "bmu_comp25";
BA_ "VFrameFormat" BO_ 2284093746 1;
BA_ "GenMsgCycleTime" BO_ 2284093747 3300;
BA_ "SendType" BO_ 2284093747 "Burst";
BA_ "Variant" BO_ 2284093747 "bmu_comp25";
BA_ "VFrameFormat" BO_ 2284093747 1;
BA_ "GenMsgCycleTime" BO_ 2284093760 3300;
BA_ "SendType" BO_ 2284093760 "Burst";
BA_ "Variant" BO_ 2284093760 "bmu_comp25";
BA_ "VFrameFormat" BO_ 2284093760 1;
BA_ "GenMsgCycleTime" BO_ 2284093761 3300;
BA_ "SendType" BO_ 2284093761 "Burst";
BA_ "Variant" BO_ 2284093761 "bmu_comp25";
BA_ "VFrameFormat" BO_ 2284093761 1;
BA_ "GenMsgCycleTime" BO_ 2284093762 3300;
BA_ "SendType" BO_ 2284093762 "Burst";
BA_ "Variant" BO_ 2284093762 "bmu_comp25";
BA_ "VFrameFormat" BO_ 2284093762 1;
BA_ "GenMsgCycleTime" BO_ 2284093763 3300;
BA_ "SendType" BO_ 2284093763 "Burst";
BA_ "Variant" BO_ 2284093763 "bmu_comp25";
BA_ "VFrameFormat" BO_ 2284093763 1;
BA_ "GenMsgCycleTime" BO_ 2284093776 3300;
BA_ "SendType" BO_ 2284093776 "Burst";
BA_ "Variant" BO_ 2284093776 "bmu_comp25";
BA_ "VFrameFormat" BO_ 2284093776 1;
BA_ "GenMsgCycleTime" BO_ 2284093777 3300;
BA_ "SendType" BO_ 2284093777 "Burst";
BA_ "Variant" BO_ 2284093777 "bmu_comp25";
BA_ "VFrameFormat" BO_ 2284093777 1;
BA_ "GenMsgCycleTime" BO_ 2284093778 3300;
BA_ "SendType" BO_ 2284093778 "Burst";
BA_ "Variant" BO_ 2284093778 "bmu_comp25";
BA_ "VFrameFormat" BO_ 2284093778 1;
BA_ "GenMsgCycleTime" BO_ 2284093779 3300;
BA_ "SendType" BO_ 2284093779 "Burst";
BA_ "Variant" BO_ 2284093779 "bmu_comp25";
BA_ "VFrameFormat" BO_ 2284093779 1;
BA_ "GenMsgCycleTime" BO_ 2284093792 3300;
BA_ "SendType" BO_ 2284093792 "Burst";
BA_ "Variant" BO_ 2284093792 "bmu_comp25";
BA_ "VFrameFormat" BO_ 2284093792 1;
BA_ "GenMsgCycleTime" BO_ 2284093793 3300;
BA_ "SendType" BO_ 2284093793 "Burst";
BA_ "Variant" BO_ 2284093793 "bmu_comp25";
BA_ "VFrameFormat" BO_ 2284093793 1;
BA_ "GenMsgCycleTime" BO_ 2284093794 3300;
BA_ "SendType" BO_ 2284093794 "Burst";
BA_ "Variant" BO_ 2284093794 "bmu_comp25";
BA_ "VFrameFormat" BO_ 2284093794 1;
BA_ "GenMsgCycleTime" BO_ 2284093795 3300;
BA_ "SendType" BO_ 2284093795 "Burst";
BA_ "Variant" BO_ 2284093795 "bmu_comp25";
BA_ "VFrameFormat" BO_ 2284093795 1;
BA_ "GenMsgCycleTime" BO_ 2284093808 3300;
BA_ "SendType" BO_ 2284093808 "Burst";
BA_ "Variant" BO_ 2284093808 "bmu_comp25";
BA_ "VFrameFormat" BO_ 2284093808 1;
BA_ "GenMsgCycleTime" BO_ 2284093809 3300;
BA_ "SendType" BO_ 2284093809 "Burst";
BA_ "Variant" BO_ 2284093809 "bmu_comp25";
BA_ "VFrameFormat" BO_ 2284093809 1;
BA_ "GenMsgCycleTime" BO_ 2284093810 3300;
BA_ "SendType" BO_ 2284093810 "Burst";
BA_ "Variant" BO_ 2284093810 "bmu_comp25";
BA_ "VFrameFormat" BO_ 2284093810 1;
BA_ "GenMsgCycleTime" BO_ 2284093811 3300;
BA_ "SendType" BO_ 2284093811 "Burst";
BA_ "Variant" BO_ 2284093811 "bmu_comp25";
BA_ "VFrameFormat" BO_ 2284093811 1;
BA_ "GenMsgCycleTime" BO_ 2284094464 3300;
BA_ "SendType" BO_ 2284094464 "Burst";
BA_ "RxTimeoutMs" BO_ 2284094464 7000;
BA_ "Variant" BO_ 2284094464 "bmu_comp25";
BA_ "VFrameFormat" BO_ 2284094464 1;
BA_ "GenMsgCycleTime" BO_ 2284094465 3300;
BA_ "SendType" BO_ 2284094465 "Burst";
BA_ "RxTimeoutMs" BO_ 2284094465 7000;
BA_ "Variant" BO_ 2284094465 "bmu_comp25";
BA_ "VFrameFormat" BO_ 2284094465 1;
BA_ "GenMsgCycleTime" BO_ 2284094480 3300;
BA_ "SendType" BO_ 2284094480 "Burst";
BA_ "RxTimeoutMs" BO_ 2284094480 7000;
BA_ "Variant" BO_ 2284094480 "bmu_comp25";
BA_ "VFrameFormat" BO_ 2284094480 1;
BA_ "GenMsgCycleTime" BO_ 2284094481 3300;
BA_ "SendType" BO_ 2284094481 "Burst";
BA_ "RxTimeoutMs" BO_ 2284094481 7000;
BA_ "Variant" BO_ 2284094481 "bmu_comp25";
BA_ "VFrameFormat" BO_ 2284094481 1;
BA_ "GenMsgCycleTime" BO_ 2284094496 3300;
BA_ "SendType" BO_ 2284094496 "Burst";
BA_ "RxTimeoutMs" BO_ 2284094496 7000;
BA_ "Variant" BO_ 2284094496 "bmu_comp25";
BA_ "VFrameFormat" BO_ 2284094496 1;
BA_ "GenMsgCycleTime" BO_ 2284094497 3300;
BA_ "SendType" BO_ 2284094497 "Burst";
BA_ "RxTimeoutMs" BO_ 2284094497 7000;
BA_ "Variant" BO_ 2284094497 "bmu_comp25";
BA_ "VFrameFormat" BO_ 2284094497 1;
BA_ "GenMsgCycleTime" BO_ 2284094512 3300;
BA_ "SendType" BO_ 2284094512 "Burst";
BA_ "RxTimeoutMs" BO_ 2284094512 7000;
BA_ "Variant" BO_ 2284094512 "bmu_comp25";
BA_ "VFrameFormat" BO_ 2284094512 1;
BA_ "GenMsgCycleTime" BO_ 2284094513 3300;
BA_ "SendType" BO_ 2284094513 "Burst";
BA_ "RxTimeoutMs" BO_ 2284094513 7000;
BA_ "Variant" BO_ 2284094513 "bmu_comp25";
BA_ "VFrameFormat" BO_ 2284094513 1;
BA_ "GenMsgCycleTime" BO_ 2284094528 3300;
BA_ "SendType" BO_ 2284094528 "Burst";
BA_ "RxTimeoutMs" BO_ 2284094528 7000;
BA_ "Variant" BO_ 2284094528 "bmu_comp25";
BA_ "VFrameFormat" BO_ 2284094528 1;
BA_ "GenMsgCycleTime" BO_ 2284094529 3300;
BA_ "SendType" BO_ 2284094529 "Burst";
BA_ "RxTimeoutMs" BO_ 2284094529 7000;
BA_ "Variant" BO_ 2284094529 "bmu_comp25";
BA_ "VFrameFormat" BO_ 2284094529 1;
BA_ "GenMsgCycleTime" BO_ 2284094544 3300;
BA_ "SendType" BO_ 2284094544 "Burst";
BA_ "RxTimeoutMs" BO_ 2284094544 7000;
BA_ "Variant" BO_ 2284094544 "bmu_comp25";
BA_ "VFrameFormat" BO_ 2284094544 1;
BA_ "GenMsgCycleTime" BO_ 2284094545 3300;
BA_ "SendType" BO_ 2284094545 "Burst";
BA_ "RxTimeoutMs" BO_ 2284094545 7000;
BA_ "Variant" BO_ 2284094545 "bmu_comp25";
BA_ "VFrameFormat" BO_ 2284094545 1;
BA_ "GenMsgCycleTime" BO_ 2284094560 3300;
BA_ "SendType" BO_ 2284094560 "Burst";
BA_ "RxTimeoutMs" BO_ 2284094560 7000;
BA_ "Variant" BO_ 2284094560 "bmu_comp25";
BA_ "VFrameFormat" BO_ 2284094560 1;
BA_ "GenMsgCycleTime" BO_ 2284094561 3300;
BA_ "SendType" BO_ 2284094561 "Burst";
BA_ "RxTimeoutMs" BO_ 2284094561 7000;
BA_ "Variant" BO_ 2284094561 "bmu_comp25";
BA_ "VFrameFormat" BO_ 2284094561 1;
BA_ "GenMsgCycleTime" BO_ 2284094576 3300;
BA_ "SendType" BO_ 2284094576 "Burst";
BA_ "RxTimeoutMs" BO_ 2284094576 7000;
BA_ "Variant" BO_ 2284094576 "bmu_comp25";
BA_ "VFrameFormat" BO_ 2284094576 1;
BA_ "GenMsgCycleTime" BO_ 2284094577 3300;
BA_ "SendType" BO_ 2284094577 "Burst";
BA_ "RxTimeoutMs" BO_ 2284094577 7000;
BA_ "Variant" BO_ 2284094577 "bmu_comp25";
BA_ "VFrameFormat" BO_ 2284094577 1;
BA_ "GenMsgCycleTime" BO_ 2284094592 3300;
BA_ "SendType" BO_ 2284094592 "Burst";
BA_ "RxTimeoutMs" BO_ 2284094592 7000;
BA_ "Variant" BO_ 2284094592 "bmu_comp25";
BA_ "VFrameFormat" BO_ 2284094592 1;
BA_ "GenMsgCycleTime" BO_ 2284094593 3300;
BA_ "SendType" BO_ 2284094593 "Burst";
BA_ "RxTimeoutMs" BO_ 2284094593 7000;
BA_ "Variant" BO_ 2284094593 "bmu_comp25";
BA_ "VFrameFormat" BO_ 2284094593 1;
BA_ "GenMsgCycleTime" BO_ 2284094608 3300;
BA_ "SendType" BO_ 2284094608 "Burst";
BA_ "RxTimeoutMs" BO_ 2284094608 7000;
BA_ "Variant" BO_ 2284094608 "bmu_comp25";
BA_ "VFrameFormat" BO_ 2284094608 1;
BA_ "GenMsgCycleTime" BO_ 2284094609 3300;
BA_ "SendType" BO_ 2284094609 "Burst";
BA_ "RxTimeoutMs" BO_ 2284094609 7000;
BA_ "Variant" BO_ 2284094609 "bmu_comp25";
BA_ "VFrameFormat" BO_ 2284094609 1;
BA_ "GenMsgCycleTime" BO_ 2284094624 3300;
BA_ "SendType" BO_ 2284094624 "Burst";
BA_ "RxTimeoutMs" BO_ 2284094624 7000;
BA_ "Variant" BO_ 2284094624 "bmu_comp25";
BA_ "VFrameFormat" BO_ 2284094624 1;
BA_ "GenMsgCycleTime" BO_ 2284094625 3300;
BA_ "SendType" BO_ 2284094625 "Burst";
BA_ "RxTimeoutMs" BO_ 2284094625 7000;
BA_ "Variant" BO_ 2284094625 "bmu_comp25";
BA_ "VFrameFormat" BO_ 2284094625 1;
BA_ "GenMsgCycleTime" BO_ 2284094640 3300;
BA_ "SendType" BO_ 2284094640 "Burst";
BA_ "RxTimeoutMs" BO_ 2284094640 7000;
BA_ "Variant" BO_ 2284094640 "bmu_comp25";
BA_ "VFrameFormat" BO_ 2284094640 1;
BA_ "GenMsgCycleTime" BO_ 2284094641 3300;
BA_ "SendType" BO_ 2284094641 "Burst";
BA_ "RxTimeoutMs" BO_ 2284094641 7000;
BA_ "Variant" BO_ 2284094641 "bmu_comp25";
BA_ "VFrameFormat" BO_ 2284094641 1;
BA_ "GenMsgCycleTime" BO_ 2284094656 3300;
BA_ "SendType" BO_ 2284094656 "Burst";
BA_ "RxTimeoutMs" BO_ 2284094656 7000;
BA_ "Variant" BO_ 2284094656 "bmu_comp25";
BA_ "VFrameFormat" BO_ 2284094656 1;
BA_ "GenMsgCycleTime" BO_ 2284094657 3300;
BA_ "SendType" BO_ 2284094657 "Burst";
BA_ "RxTimeoutMs" BO_ 2284094657 7000;
BA_ "Variant" BO_ 2284094657 "bmu_comp25";
BA_ "VFrameFormat" BO_ 2284094657 1;
BA_ "GenMsgCycleTime" BO_ 2284094672 3300;
BA_ "SendType" BO_ 2284094672 "Burst";
BA_ "RxTimeoutMs" BO_ 2284094672 7000;
BA_ "Variant" BO_ 2284094672 "bmu_comp25";
BA_ "VFrameFormat" BO_ 2284094672 1;
BA_ "GenMsgCycleTime" BO_ 2284094673 3300;
BA_ "SendType" BO_ 2284094673 "Burst";
BA_ "RxTimeoutMs" BO_ 2284094673 7000;
BA_ "Variant" BO_ 2284094673 "bmu_comp25";
BA_ "VFrameFormat" BO_ 2284094673 1;
BA_ "GenMsgCycleTime" BO_ 2284094688 3300;
BA_ "SendType" BO_ 2284094688 "Burst";
BA_ "RxTimeoutMs" BO_ 2284094688 7000;
BA_ "Variant" BO_ 2284094688 "bmu_comp25";
BA_ "VFrameFormat" BO_ 2284094688 1;
BA_ "GenMsgCycleTime" BO_ 2284094689 3300;
BA_ "SendType" BO_ 2284094689 "Burst";
BA_ "RxTimeoutMs" BO_ 2284094689 7000;
BA_ "Variant" BO_ 2284094689 "bmu_comp25";
BA_ "VFrameFormat" BO_ 2284094689 1;
BA_ "GenMsgCycleTime" BO_ 2284094704 3300;
BA_ "SendType" BO_ 2284094704 "Burst";
BA_ "RxTimeoutMs" BO_ 2284094704 7000;
BA_ "Variant" BO_ 2284094704 "bmu_comp25";
BA_ "VFrameFormat" BO_ 2284094704 1;
BA_ "GenMsgCycleTime" BO_ 2284094705 3300;
BA_ "SendType" BO_ 2284094705 "Burst";
BA_ "RxTimeoutMs" BO_ 2284094705 7000;
BA_ "Variant" BO_ 2284094705 "bmu_comp25";
BA_ "VFrameFormat" BO_ 2284094705 1;
BA_ "GenMsgCycleTime" BO_ 2284094720 3300;
BA_ "SendType" BO_ 2284094720 "Burst";
BA_ "RxTimeoutMs" BO_ 2284094720 7000;
BA_ "Variant" BO_ 2284094720 "bmu_comp25";
BA_ "VFrameFormat" BO_ 2284094720 1;
BA_ "GenMsgCycleTime" BO_ 2284094721 3300;
BA_ "SendType" BO_ 2284094721 "Burst";
BA_ "RxTimeoutMs" BO_ 2284094721 7000;
BA_ "Variant" BO_ 2284094721 "bmu_comp25";
BA_ "VFrameFormat" BO_ 2284094721 1;
BA_ "GenMsgCycleTime" BO_ 2284094736 3300;
BA_ "SendType" BO_ 2284094736 "Burst";
BA_ "RxTimeoutMs" BO_ 2284094736 7000;
BA_ "Variant" BO_ 2284094736 "bmu_comp25";
BA_ "VFrameFormat" BO_ 2284094736 1;
BA_ "GenMsgCycleTime" BO_ 2284094737 3300;
BA_ "SendType" BO_ 2284094737 "Burst";
BA_ "RxTimeoutMs" BO_ 2284094737 7000;
BA_ "Variant" BO_ 2284094737 "bmu_comp25";
BA_ "VFrameFormat" BO_ 2284094737 1;
BA_ "GenMsgCycleTime" BO_ 2284094752 3300;
BA_ "SendType" BO_ 2284094752 "Burst";
BA_ "RxTimeoutMs" BO_ 2284094752 7000;
BA_ "Variant" BO_ 2284094752 "bmu_comp25";
BA_ "VFrameFormat" BO_ 2284094752 1;
BA_ "GenMsgCycleTime" BO_ 2284094753 3300;
BA_ "SendType" BO_ 2284094753 "Burst";
BA_ "RxTimeoutMs" BO_ 2284094753 7000;
BA_ "Variant" BO_ 2284094753 "bmu_comp25";
BA_ "VFrameFormat" BO_ 2284094753 1;
BA_ "GenMsgCycleTime" BO_ 2284094768 3300;
BA_ "SendType" BO_ 2284094768 "Burst";
BA_ "RxTimeoutMs" BO_ 2284094768 7000;
BA_ "Variant" BO_ 2284094768 "bmu_comp25";
BA_ "VFrameFormat" BO_ 2284094768 1;
BA_ "GenMsgCycleTime" BO_ 2284094769 3300;
BA_ "SendType" BO_ 2284094769 "Burst";
BA_ "RxTimeoutMs" BO_ 2284094769 7000;
BA_ "Variant" BO_ 2284094769 "bmu_comp25";
BA_ "VFrameFormat" BO_ 2284094769 1;
BA_ "GenMsgCycleTime" BO_ 2284094784 3300;
BA_ "SendType" BO_ 2284094784 "Burst";
BA_ "RxTimeoutMs" BO_ 2284094784 7000;
BA_ "Variant" BO_ 2284094784 "bmu_comp25";
BA_ "VFrameFormat" BO_ 2284094784 1;
BA_ "GenMsgCycleTime" BO_ 2284094785 3300;
BA_ "SendType" BO_ 2284094785 "Burst";
BA_ "RxTimeoutMs" BO_ 2284094785 7000;
BA_ "Variant" BO_ 2284094785 "bmu_comp25";
BA_ "VFrameFormat" BO_ 2284094785 1;
BA_ "GenMsgCycleTime" BO_ 2284094800 3300;
BA_ "SendType" BO_ 2284094800 "Burst";
BA_ "RxTimeoutMs" BO_ 2284094800 7000;
BA_ "Variant" BO_ 2284094800 "bmu_comp25";
BA_ "VFrameFormat" BO_ 2284094800 1;
BA_ "GenMsgCycleTime" BO_ 2284094801 3300;
BA_ "SendType" BO_ 2284094801 "Burst";
BA_ "RxTimeoutMs" BO_ 2284094801 7000;
BA_ "Variant" BO_ 2284094801 "bmu_comp25";
BA_ "VFrameFormat" BO_ 2284094801 1;
BA_ "GenMsgCycleTime" BO_ 2284094816 3300;
BA_ "SendType" BO_ 2284094816 "Burst";
BA_ "RxTimeoutMs" BO_ 2284094816 7000;
BA_ "Variant" BO_ 2284094816 "bmu_comp25";
BA_ "VFrameFormat" BO_ 2284094816 1;
BA_ "GenMsgCycleTime" BO_ 2284094817 3300;
BA_ "SendType" BO_ 2284094817 "Burst";
BA_ "RxTimeoutMs" BO_ 2284094817 7000;
BA_ "Variant" BO_ 2284094817 "bmu_comp25";
BA_ "VFrameFormat" BO_ 2284094817 1;
BA_ "GenMsgCycleTime" BO_ 2284094832 3300;
BA_ "SendType" BO_ 2284094832 "Burst";
BA_ "RxTimeoutMs" BO_ 2284094832 7000;
BA_ "Variant" BO_ 2284094832 "bmu_comp25";
BA_ "VFrameFormat" BO_ 2284094832 1;
BA_ "GenMsgCycleTime" BO_ 2284094833 3300;
BA_ "SendType" BO_ 2284094833 "Burst";
BA_ "RxTimeoutMs" BO_ 2284094833 7000;
BA_ "Variant" BO_ 2284094833 "bmu_comp25";
BA_ "VFrameFormat" BO_ 2284094833 1;
BA_ "GenMsgCycleTime" BO_ 2284095488 3300;
BA_ "SendType" BO_ 2284095488 "Burst";
BA_ "Variant" BO_ 2284095488 "bmu_comp25";
BA_ "VFrameFormat" BO_ 2284095488 1;
BA_ "GenMsgCycleTime" BO_ 2284095504 3300;
BA_ "SendType" BO_ 2284095504 "Burst";
BA_ "Variant" BO_ 2284095504 "bmu_comp25";
BA_ "VFrameFormat" BO_ 2284095504 1;
BA_ "GenMsgCycleTime" BO_ 2284095520 3300;
BA_ "SendType" BO_ 2284095520 "Burst";
BA_ "Variant" BO_ 2284095520 "bmu_comp25";
BA_ "VFrameFormat" BO_ 2284095520 1;
BA_ "GenMsgCycleTime" BO_ 2284095536 3300;
BA_ "SendType" BO_ 2284095536 "Burst";
BA_ "Variant" BO_ 2284095536 "bmu_comp25";
BA_ "VFrameFormat" BO_ 2284095536 1;
BA_ "GenMsgCycleTime" BO_ 2284095552 3300;
BA_ "SendType" BO_ 2284095552 "Burst";
BA_ "Variant" BO_ 2284095552 "bmu_comp25";
BA_ "VFrameFormat" BO_ 2284095552 1;
BA_ "GenMsgCycleTime" BO_ 2284095568 3300;
BA_ "SendType" BO_ 2284095568 "Burst";
BA_ "Variant" BO_ 2284095568 "bmu_comp25";
BA_ "VFrameFormat" BO_ 2284095568 1;
BA_ "GenMsgCycleTime" BO_ 2284095584 3300;
BA_ "SendType" BO_ 2284095584 "Burst";
BA_ "Variant" BO_ 2284095584 "bmu_comp25";
BA_ "VFrameFormat" BO_ 2284095584 1;
BA_ "GenMsgCycleTime" BO_ 2284095600 3300;
BA_ "SendType" BO_ 2284095600 "Burst";
BA_ "Variant" BO_ 2284095600 "bmu_comp25";
BA_ "VFrameFormat" BO_ 2284095600 1;
BA_ "GenMsgCycleTime" BO_ 2284095616 3300;
BA_ "SendType" BO_ 2284095616 "Burst";
BA_ "Variant" BO_ 2284095616 "bmu_comp25";
BA_ "VFrameFormat" BO_ 2284095616 1;
BA_ "GenMsgCycleTime" BO_ 2284095632 3300;
BA_ "SendType" BO_ 2284095632 "Burst";
BA_ "Variant" BO_ 2284095632 "bmu_comp25";
BA_ "VFrameFormat" BO_ 2284095632 1;
BA_ "GenMsgCycleTime" BO_ 2284095648 3300;
BA_ "SendType" BO_ 2284095648 "Burst";
BA_ "Variant" BO_ 2284095648 "bmu_comp25";
BA_ "VFrameFormat" BO_ 2284095648 1;
BA_ "GenMsgCycleTime" BO_ 2284095664 3300;
BA_ "SendType" BO_ 2284095664 "Burst";
BA_ "Variant" BO_ 2284095664 "bmu_comp25";
BA_ "VFrameFormat" BO_ 2284095664 1;
BA_ "GenMsgCycleTime" BO_ 2284095680 3300;
BA_ "SendType" BO_ 2284095680 "Burst";
BA_ "Variant" BO_ 2284095680 "bmu_comp25";
BA_ "VFrameFormat" BO_ 2284095680 1;
BA_ "GenMsgCycleTime" BO_ 2284095696 3300;
BA_ "SendType" BO_ 2284095696 "Burst";
BA_ "Variant" BO_ 2284095696 "bmu_comp25";
BA_ "VFrameFormat" BO_ 2284095696 1;
BA_ "GenMsgCycleTime" BO_ 2284095712 3300;
BA_ "SendType" BO_ 2284095712 "Burst";
BA_ "Variant" BO_ 2284095712 "bmu_comp25";
BA_ "VFrameFormat" BO_ 2284095712 1;
BA_ "GenMsgCycleTime" BO_ 2284095728 3300;
BA_ "SendType" BO_ 2284095728 "Burst";
BA_ "Variant" BO_ 2284095728 "bmu_comp25";
BA_ "VFrameFormat" BO_ 2284095728 1;
VAL_ 2147486780 DTI_L_CmdDriveEnable 0 "NOT_ALLOWED" 1 "ALLOWED" ;
VAL_ 2147486781 DTI_R_CmdDriveEnable 0 "NOT_ALLOWED" 1 "ALLOWED" ;
VAL_ 2147491644 DTI_L_ControlMode 0 "NOT_USED" 1 "SPEED" 2 "CURRENT" 3 "CURRENT_BRAKE" 4 "POSITION" 7 "NONE" ;
VAL_ 2147491644 DTI_L_MotorStill 0 "ROTATING" 1 "STILL" ;
VAL_ 2147491645 DTI_R_ControlMode 0 "NOT_USED" 1 "SPEED" 2 "CURRENT" 3 "CURRENT_BRAKE" 4 "POSITION" 7 "NONE" ;
VAL_ 2147491645 DTI_R_MotorStill 0 "ROTATING" 1 "STILL" ;
VAL_ 2147492412 DTI_L_FaultCode 0 "NO_FAULTS" 1 "OVERVOLTAGE" 2 "UNDERVOLTAGE" 3 "DRV" 4 "ABS_OVERCURRENT" 5 "CTLR_OVERTEMP" 6 "MOTOR_OVERTEMP" 7 "SENSOR_WIRE_FAULT" 8 "SENSOR_GENERAL_FAULT" 9 "CAN_COMMAND_ERROR" 10 "ANALOG_INPUT_ERROR" ;
VAL_ 2147492413 DTI_R_FaultCode 0 "NO_FAULTS" 1 "OVERVOLTAGE" 2 "UNDERVOLTAGE" 3 "DRV" 4 "ABS_OVERCURRENT" 5 "CTLR_OVERTEMP" 6 "MOTOR_OVERTEMP" 7 "SENSOR_WIRE_FAULT" 8 "SENSOR_GENERAL_FAULT" 9 "CAN_COMMAND_ERROR" 10 "ANALOG_INPUT_ERROR" ;
VAL_ 2147492924 DTI_L_DriveEnabled 0 "DISABLED" 1 "ENABLED" ;
VAL_ 2147492925 DTI_R_DriveEnabled 0 "DISABLED" 1 "ENABLED" ;
VAL_ 2281963520 BMU_State 0 "START" 1 "INIT_PERIPHERAL" 2 "INIT_CMU" 3 "CHECK_CMU_GPIO" 4 "CHECK_SENDYNE" 5 "CHECK_BOARD" 6 "READY" 7 "PRECHARGE" 8 "TS_ACTIVE" 13 "TRIG_SHDN" 15 "SHUTDOWN" 22 "CHRG_CHECK_BOARD" 23 "CHRG_READY" 24 "CHRG_PRECHARGE" 25 "CHRG_TS_ACTIVE" 26 "CHRG_FAIL" 255 "ERROR" ;
